VERSION "0.2"

NS_ :

BS_:

BU_: dSPACE External IFV_CWMP

BO_ 3221225472 VECTOR__INDEPENDENT_SIG_MSG: 0 Vector__XXX
 SG_ VIS_TSR_SIGN_ID_1 : 0|8@1+ (1,0) [0|255] "" Vector__XXX
 SG_ VIS_TSR_SCENE_STATUS_1 : 0|1@1+ (1,0) [0|1] "" Vector__XXX
 SG_ VIS_TSR_SCENE_ID_1 : 0|8@1+ (1,0) [0|255] "" Vector__XXX
 SG_ VIS_TSR_LANE_CHANGE : 0|2@1+ (1,0) [0|2] "" Vector__XXX
 SG_ VIS_TSR_ROAD_CLASS : 0|3@1+ (1,0) [0|4] "" Vector__XXX
 SG_ VIS_TSR_SPEED_UNIT : 0|2@1+ (1,0) [0|2] "" Vector__XXX
 SG_ VIS_TSR_TRAFFIC_STYLE : 0|1@1+ (1,0) [0|1] "" Vector__XXX
 SG_ s_AHBC_Reason_code : 0|32@1+ (1,0) [0|4294967295] "" Vector__XXX
 SG_ VIS_AHBC_DARK_ONCOMING_LANE : 0|1@1+ (1,0) [0|1] "" Vector__XXX
 SG_ VIS_AHBC_PRECEDING_SPOTS : 0|8@1+ (1,0) [0|255] "" Vector__XXX
 SG_ VIS_AHBC_ONCOMING_SPOTS : 0|8@1+ (1,0) [0|255] "" Vector__XXX
 SG_ VIS_AHBC_CLEAR_FIELD_OF_VIEW : 0|2@1+ (1,0) [0|2] "" Vector__XXX
 SG_ VIS_AHBC_STRUCT_SEPARATION_DET : 0|3@1+ (1,0) [0|4] "" Vector__XXX
 SG_ VIS_AHBC_DAY_TIME_STATUS : 0|2@1+ (1,0) [0|3] "" Vector__XXX
 SG_ VIS_AHBC_FOG_DETECTION : 0|1@1+ (1,0) [0|1] "" Vector__XXX
 SG_ VIS_AHBC_HIGHWAY_DETECTION : 0|1@1+ (1,0) [0|1] "" Vector__XXX
 SG_ VIS_AHBC_URBAN_AREA_DETECTION : 0|2@1+ (1,0) [0|2] "" Vector__XXX
 SG_ VIS_AHBC_TRAFFIC_STYLE_DETECTION : 0|1@1+ (1,0) [0|1] "" Vector__XXX
 SG_ VIS_AHBC_OBJ_10_VERTICAL_POS : 0|9@1+ (0.04,-5) [-5|5] "deg" Vector__XXX
 SG_ VIS_AHBC_OBJ_10_TYPE : 0|3@1+ (1,0) [0|5] "" Vector__XXX
 SG_ VIS_AHBC_OBJ_10_ID : 0|7@1+ (1,0) [0|127] "" Vector__XXX
 SG_ VIS_AHBC_OBJ_10_HORIZONTAL_POS : 0|11@1+ (0.04,-24) [-24|24] "deg" Vector__XXX
 SG_ VIS_AHBC_OBJ_10_HORIZONTAL_DIM : 0|9@1+ (0.04,0) [0|10] "deg" Vector__XXX
 SG_ VIS_AHBC_OBJ_10_DISTANCE : 0|4@1+ (1,0) [0|15] "" Vector__XXX
 SG_ VIS_AHBC_OBJ_09_VERTICAL_POS : 0|9@1+ (0.04,-5) [-5|5] "deg" Vector__XXX
 SG_ VIS_AHBC_OBJ_09_TYPE : 0|3@1+ (1,0) [0|5] "" Vector__XXX
 SG_ VIS_AHBC_OBJ_09_ID : 0|7@1+ (1,0) [0|127] "" Vector__XXX
 SG_ VIS_AHBC_OBJ_09_HORIZONTAL_POS : 0|11@1+ (0.04,-24) [-24|24] "deg" Vector__XXX
 SG_ VIS_AHBC_OBJ_09_HORIZONTAL_DIM : 0|9@1+ (0.04,0) [0|10] "deg" Vector__XXX
 SG_ VIS_AHBC_OBJ_09_DISTANCE : 0|4@1+ (1,0) [0|15] "" Vector__XXX
 SG_ VIS_AHBC_OBJ_08_VERTICAL_POS : 0|9@1+ (0.04,-5) [-5|5] "deg" Vector__XXX
 SG_ VIS_AHBC_OBJ_08_TYPE : 0|3@1+ (1,0) [0|5] "" Vector__XXX
 SG_ VIS_AHBC_OBJ_08_ID : 0|7@1+ (1,0) [0|127] "" Vector__XXX
 SG_ VIS_AHBC_OBJ_08_HORIZONTAL_POS : 0|11@1+ (0.04,-24) [-24|24] "deg" Vector__XXX
 SG_ VIS_AHBC_OBJ_08_HORIZONTAL_DIM : 0|9@1+ (0.04,0) [0|10] "deg" Vector__XXX
 SG_ VIS_AHBC_OBJ_08_DISTANCE : 0|4@1+ (1,0) [0|15] "" Vector__XXX
 SG_ VIS_AHBC_OBJ_07_VERTICAL_POS : 0|9@1+ (0.04,-5) [-5|5] "deg" Vector__XXX
 SG_ VIS_AHBC_OBJ_07_TYPE : 0|3@1+ (1,0) [0|5] "" Vector__XXX
 SG_ VIS_AHBC_OBJ_07_ID : 0|7@1+ (1,0) [0|127] "" Vector__XXX
 SG_ VIS_AHBC_OBJ_07_HORIZONTAL_POS : 0|11@1+ (0.04,-24) [-24|24] "deg" Vector__XXX
 SG_ VIS_AHBC_OBJ_07_HORIZONTAL_DIM : 0|9@1+ (0.04,0) [0|10] "deg" Vector__XXX
 SG_ VIS_AHBC_OBJ_07_DISTANCE : 0|4@1+ (1,0) [0|15] "" Vector__XXX
 SG_ VIS_AHBC_OBJ_06_VERTICAL_POS : 0|9@1+ (0.04,-5) [-5|5] "deg" Vector__XXX
 SG_ VIS_AHBC_OBJ_06_TYPE : 0|3@1+ (1,0) [0|5] "" Vector__XXX
 SG_ VIS_AHBC_OBJ_06_ID : 0|7@1+ (1,0) [0|127] "" Vector__XXX
 SG_ VIS_AHBC_OBJ_06_HORIZONTAL_POS : 0|11@1+ (0.04,-24) [-24|24] "deg" Vector__XXX
 SG_ VIS_AHBC_OBJ_06_HORIZONTAL_DIM : 0|9@1+ (0.04,0) [0|10] "deg" Vector__XXX
 SG_ VIS_AHBC_OBJ_06_DISTANCE : 0|4@1+ (1,0) [0|15] "" Vector__XXX
 SG_ VIS_AHBC_OBJ_05_VERTICAL_POS : 0|9@1+ (0.04,-5) [-5|5] "deg" Vector__XXX
 SG_ VIS_AHBC_OBJ_05_TYPE : 0|3@1+ (1,0) [0|5] "" Vector__XXX
 SG_ VIS_AHBC_OBJ_05_ID : 0|7@1+ (1,0) [0|127] "" Vector__XXX
 SG_ VIS_AHBC_OBJ_05_HORIZONTAL_POS : 0|11@1+ (0.04,-24) [-24|24] "deg" Vector__XXX
 SG_ VIS_AHBC_OBJ_05_HORIZONTAL_DIM : 0|9@1+ (0.04,0) [0|10] "deg" Vector__XXX
 SG_ VIS_AHBC_OBJ_05_DISTANCE : 0|4@1+ (1,0) [0|15] "" Vector__XXX
 SG_ VIS_AHBC_OBJ_04_VERTICAL_POS : 0|9@1+ (0.04,-5) [-5|5] "deg" Vector__XXX
 SG_ VIS_AHBC_OBJ_04_TYPE : 0|3@1+ (1,0) [0|5] "" Vector__XXX
 SG_ VIS_AHBC_OBJ_04_ID : 0|7@1+ (1,0) [0|127] "" Vector__XXX
 SG_ VIS_AHBC_OBJ_04_HORIZONTAL_POS : 0|11@1+ (0.04,-24) [-24|24] "deg" Vector__XXX
 SG_ VIS_AHBC_OBJ_04_HORIZONTAL_DIM : 0|9@1+ (0.04,0) [0|10] "deg" Vector__XXX
 SG_ VIS_AHBC_OBJ_04_DISTANCE : 0|4@1+ (1,0) [0|15] "" Vector__XXX
 SG_ VIS_AHBC_OBJ_03_VERTICAL_POS : 0|9@1+ (0.04,-5) [-5|5] "deg" Vector__XXX
 SG_ VIS_AHBC_OBJ_03_TYPE : 0|3@1+ (1,0) [0|5] "" Vector__XXX
 SG_ VIS_AHBC_OBJ_03_ID : 0|7@1+ (1,0) [0|127] "" Vector__XXX
 SG_ VIS_AHBC_OBJ_03_HORIZONTAL_POS : 0|11@1+ (0.04,-24) [-24|24] "deg" Vector__XXX
 SG_ VIS_AHBC_OBJ_03_HORIZONTAL_DIM : 0|9@1+ (0.04,0) [0|10] "deg" Vector__XXX
 SG_ VIS_AHBC_OBJ_03_DISTANCE : 0|4@1+ (1,0) [0|15] "" Vector__XXX
 SG_ VIS_AHBC_OBJ_02_VERTICAL_POS : 0|9@1+ (0.04,-5) [-5|5] "deg" Vector__XXX
 SG_ VIS_AHBC_OBJ_02_TYPE : 0|3@1+ (1,0) [0|5] "" Vector__XXX
 SG_ VIS_AHBC_OBJ_02_ID : 0|7@1+ (1,0) [0|127] "" Vector__XXX
 SG_ VIS_AHBC_OBJ_02_HORIZONTAL_POS : 0|11@1+ (0.04,-24) [-24|24] "deg" Vector__XXX
 SG_ VIS_AHBC_OBJ_02_HORIZONTAL_DIM : 0|9@1+ (0.04,0) [0|10] "deg" Vector__XXX
 SG_ VIS_AHBC_OBJ_02_DISTANCE : 0|4@1+ (1,0) [0|15] "" Vector__XXX
 SG_ VIS_AHBC_OBJ_01_VERTICAL_POS : 0|9@1+ (0.04,-5) [-5|5] "deg" Vector__XXX
 SG_ VIS_AHBC_OBJ_01_TYPE : 0|3@1+ (1,0) [0|5] "" Vector__XXX
 SG_ VIS_AHBC_OBJ_01_ID : 0|7@1+ (1,0) [0|127] "" Vector__XXX
 SG_ VIS_AHBC_OBJ_01_HORIZONTAL_POS : 0|11@1+ (0.04,-24) [-24|24] "deg" Vector__XXX
 SG_ VIS_AHBC_OBJ_01_HORIZONTAL_DIM : 0|9@1+ (0.04,0) [0|10] "deg" Vector__XXX
 SG_ VIS_AHBC_OBJ_01_DISTANCE : 0|4@1+ (1,0) [0|15] "" Vector__XXX
 SG_ VIS_LANE_RIGHT_PARALL_STATUS : 0|3@1+ (1,0) [0|7] "" Vector__XXX
 SG_ VIS_LANE_RIGHT_INDIVID_STATUS : 0|3@1+ (1,0) [0|7] "" Vector__XXX
 SG_ VIS_LANE_LEFT_PARALL_STATUS : 0|3@1+ (1,0) [0|7] "" Vector__XXX
 SG_ VIS_LANE_LEFT_INDIVID_STATUS : 0|3@1+ (1,0) [0|7] "" Vector__XXX
 SG_ VIS_PREDICTION_INFORMATION_R : 0|6@1+ (1,0) [0|63] "" Vector__XXX
 SG_ VIS_PREDICTION_INFORMATION_L : 0|6@1+ (1,0) [0|63] "" Vector__XXX
 SG_ VIS_CENTER_POLYNOMIAL_WIDTH : 0|10@1+ (0.01,0) [0|10] "m" Vector__XXX
 SG_ VIS_CENTER_POLYNOMIAL_A3 : 0|16@1+ (1E-008,-0.00017) [-0.00017|0.000167] "1/m^2" Vector__XXX
 SG_ VIS_CENTER_POLYNOMIAL_A2 : 0|11@1+ (1E-005,-0.01) [-0.01|0.01] "1/m" Vector__XXX
 SG_ VIS_CENTER_POLYNOMIAL_LINECASE : 0|2@1+ (1,0) [0|3] "" Vector__XXX
 SG_ VIS_CENTER_POLYNOMIAL_A1 : 0|11@1+ (0.0009,-0.9) [-0.9|0.9] "rad" Vector__XXX
 SG_ VIS_CENTER_POLYNOMIAL_A0 : 0|12@1+ (0.01,-16) [-16|15.99] "m" Vector__XXX
 SG_ VIS_CENTER_POLYNOMIAL_LANECONF : 0|2@1+ (1,0) [0|2] "" Vector__XXX
 SG_ VIS_OBS_WIDTH_15 : 0|7@1+ (0.1,0) [0|6] "m" Vector__XXX
 SG_ VIS_OBS_WIDTH_14 : 0|7@1+ (0.1,0) [0|6] "m" Vector__XXX
 SG_ VIS_OBS_WIDTH_13 : 0|7@1+ (0.1,0) [0|6] "m" Vector__XXX
 SG_ VIS_OBS_WIDTH_12 : 0|7@1+ (0.1,0) [0|6] "m" Vector__XXX
 SG_ VIS_OBS_WIDTH_11 : 0|7@1+ (0.1,0) [0|6] "m" Vector__XXX
 SG_ VIS_OBS_WIDTH_10 : 0|7@1+ (0.1,0) [0|6] "m" Vector__XXX
 SG_ VIS_OBS_WIDTH_09 : 0|7@1+ (0.1,0) [0|6] "m" Vector__XXX
 SG_ VIS_OBS_WIDTH_08 : 0|7@1+ (0.1,0) [0|6] "m" Vector__XXX
 SG_ VIS_OBS_WIDTH_07 : 0|7@1+ (0.1,0) [0|6] "m" Vector__XXX
 SG_ VIS_OBS_WIDTH_06 : 0|7@1+ (0.1,0) [0|12.7] "m" Vector__XXX
 SG_ VIS_OBS_WIDTH_05 : 0|7@1+ (0.1,0) [0|6] "m" Vector__XXX
 SG_ VIS_OBS_WIDTH_04 : 0|7@1+ (0.1,0) [0|6] "m" Vector__XXX
 SG_ VIS_OBS_WIDTH_03 : 0|7@1+ (0.1,0) [0|6] "m" Vector__XXX
 SG_ VIS_OBS_WIDTH_02 : 0|7@1+ (0.1,0) [0|6] "m" Vector__XXX
 SG_ VIS_OBS_LONG_VEL_15 : 0|12@1+ (0.0625,-128) [-128|127.9375] "m/s" Vector__XXX
 SG_ VIS_OBS_LONG_VEL_14 : 0|12@1+ (0.0625,-128) [-128|127.9375] "m/s" Vector__XXX
 SG_ VIS_OBS_LONG_VEL_13 : 0|12@1+ (0.0625,-128) [-128|127.9375] "m/s" Vector__XXX
 SG_ VIS_OBS_LONG_VEL_12 : 0|12@1+ (0.0625,-128) [-128|127.9375] "m/s" Vector__XXX
 SG_ VIS_OBS_LONG_VEL_11 : 0|12@1+ (0.0625,-128) [-128|127.9375] "m/s" Vector__XXX
 SG_ VIS_OBS_LONG_VEL_10 : 0|12@1+ (0.0625,-128) [-128|127.9375] "m/s" Vector__XXX
 SG_ VIS_OBS_LONG_VEL_09 : 0|12@1+ (0.0625,-128) [-128|127.9375] "m/s" Vector__XXX
 SG_ VIS_OBS_LONG_VEL_08 : 0|12@1+ (0.0625,-128) [-128|127.9375] "m/s" Vector__XXX
 SG_ VIS_OBS_LONG_VEL_07 : 0|12@1+ (0.0625,-128) [-128|127.9375] "m/s" Vector__XXX
 SG_ VIS_OBS_LONG_VEL_06 : 0|12@1+ (0.0625,-128) [-128|127.9375] "m/s" Vector__XXX
 SG_ VIS_OBS_LONG_VEL_05 : 0|12@1+ (0.0625,-128) [-128|127.9375] "m/s" Vector__XXX
 SG_ VIS_OBS_LONG_VEL_04 : 0|12@1+ (0.0625,-128) [-128|127.9375] "m/s" Vector__XXX
 SG_ VIS_OBS_LONG_VEL_03 : 0|12@1+ (0.0625,-128) [-128|127.9375] "m/s" Vector__XXX
 SG_ VIS_OBS_LONG_VEL_02 : 0|12@1+ (0.0625,-128) [-128|127.9375] "m/s" Vector__XXX
 SG_ VIS_OBS_LONG_POS_15 : 0|13@1+ (0.03125,0) [0|255] "m" Vector__XXX
 SG_ VIS_OBS_LONG_POS_14 : 0|13@1+ (0.03125,0) [0|255] "m" Vector__XXX
 SG_ VIS_OBS_LONG_POS_13 : 0|13@1+ (0.03125,0) [0|255] "m" Vector__XXX
 SG_ VIS_OBS_LONG_POS_12 : 0|13@1+ (0.03125,0) [0|255] "m" Vector__XXX
 SG_ VIS_OBS_LONG_POS_11 : 0|13@1+ (0.03125,0) [0|255] "m" Vector__XXX
 SG_ VIS_OBS_LONG_POS_10 : 0|13@1+ (0.03125,0) [0|255] "m" Vector__XXX
 SG_ VIS_OBS_LONG_POS_09 : 0|13@1+ (0.03125,0) [0|255] "m" Vector__XXX
 SG_ VIS_OBS_LONG_POS_08 : 0|13@1+ (0.03125,0) [0|255] "m" Vector__XXX
 SG_ VIS_OBS_LONG_POS_07 : 0|13@1+ (0.03125,0) [0|255] "m" Vector__XXX
 SG_ VIS_OBS_LONG_POS_06 : 0|13@1+ (0.03125,0) [0|255] "m" Vector__XXX
 SG_ VIS_OBS_LONG_POS_05 : 0|13@1+ (0.03125,0) [0|255] "m" Vector__XXX
 SG_ VIS_OBS_LONG_POS_04 : 0|13@1+ (0.03125,0) [0|255] "m" Vector__XXX
 SG_ VIS_OBS_LONG_POS_03 : 0|13@1+ (0.03125,0) [0|255] "m" Vector__XXX
 SG_ VIS_OBS_LONG_POS_02 : 0|13@1+ (0.03125,0) [0|255] "m" Vector__XXX
 SG_ VIS_OBS_LAT_VEL_15 : 0|12@1+ (0.0625,-128) [-128|127.9375] "m/s" Vector__XXX
 SG_ VIS_OBS_LAT_VEL_14 : 0|12@1+ (0.0625,-128) [-128|127.9375] "m/s" Vector__XXX
 SG_ VIS_OBS_LAT_VEL_13 : 0|12@1+ (0.0625,-128) [-128|127.9375] "m/s" Vector__XXX
 SG_ VIS_OBS_LAT_VEL_12 : 0|12@1+ (0.0625,-128) [-128|127.9375] "m/s" Vector__XXX
 SG_ VIS_OBS_LAT_VEL_11 : 0|12@1+ (0.0625,-128) [-128|127.9375] "m/s" Vector__XXX
 SG_ VIS_OBS_LAT_VEL_10 : 0|12@1+ (0.0625,-128) [-128|127.9375] "m/s" Vector__XXX
 SG_ VIS_OBS_LAT_VEL_09 : 0|12@1+ (0.0625,-128) [-128|127.9375] "m/s" Vector__XXX
 SG_ VIS_OBS_LAT_VEL_08 : 0|12@1+ (0.0625,-128) [-128|127.9375] "m/s" Vector__XXX
 SG_ VIS_OBS_LAT_VEL_07 : 0|12@1+ (0.0625,-128) [-128|127.9375] "m/s" Vector__XXX
 SG_ VIS_OBS_LAT_VEL_06 : 0|12@1+ (0.0625,-128) [-128|127.9375] "m/s" Vector__XXX
 SG_ VIS_OBS_LAT_VEL_05 : 0|12@1+ (0.0625,-128) [-128|127.9375] "m/s" Vector__XXX
 SG_ VIS_OBS_LAT_VEL_04 : 0|12@1+ (0.0625,-128) [-128|127.9375] "m/s" Vector__XXX
 SG_ VIS_OBS_LAT_VEL_03 : 0|12@1+ (0.0625,-128) [-128|127.9375] "m/s" Vector__XXX
 SG_ VIS_OBS_LAT_VEL_02 : 0|12@1+ (0.0625,-128) [-128|127.9375] "m/s" Vector__XXX
 SG_ VIS_OBS_LAT_POS_15 : 0|12@1+ (0.0625,-128) [-128|127.9375] "m" Vector__XXX
 SG_ VIS_OBS_LAT_POS_14 : 0|12@1+ (0.0625,-128) [-128|127.9375] "m" Vector__XXX
 SG_ VIS_OBS_LAT_POS_13 : 0|12@1+ (0.0625,-128) [-128|127.9375] "m" Vector__XXX
 SG_ VIS_OBS_LAT_POS_12 : 0|12@1+ (0.0625,-128) [-128|127.9375] "m" Vector__XXX
 SG_ VIS_OBS_LAT_POS_11 : 0|12@1+ (0.0625,-128) [-128|127.9375] "m" Vector__XXX
 SG_ VIS_OBS_LAT_POS_10 : 0|12@1+ (0.0625,-128) [-128|127.9375] "m" Vector__XXX
 SG_ VIS_OBS_LAT_POS_09 : 0|12@1+ (0.0625,-128) [-128|127.9375] "m" Vector__XXX
 SG_ VIS_OBS_LAT_POS_08 : 0|12@1+ (0.0625,-128) [-128|127.9375] "m" Vector__XXX
 SG_ VIS_OBS_LAT_POS_07 : 0|12@1+ (0.0625,-128) [-128|127.9375] "m" Vector__XXX
 SG_ VIS_OBS_LAT_POS_06 : 0|12@1+ (0.0625,-128) [-128|127.9375] "m" Vector__XXX
 SG_ VIS_OBS_LAT_POS_05 : 0|12@1+ (0.0625,-128) [-128|127.9375] "m" Vector__XXX
 SG_ VIS_OBS_LAT_POS_04 : 0|12@1+ (0.0625,-128) [-128|127.9375] "m" Vector__XXX
 SG_ VIS_OBS_LAT_POS_03 : 0|12@1+ (0.0625,-128) [-128|127.9375] "m" Vector__XXX
 SG_ VIS_OBS_LAT_POS_02 : 0|12@1+ (0.0625,-128) [-128|127.9375] "m" Vector__XXX
 SG_ VIS_OBS_WIDTH_01 : 0|7@1+ (0.1,0) [0|6] "m" Vector__XXX
 SG_ VIS_OBS_MESSAGE_COUNTER_MSG3 : 0|2@1+ (1,0) [0|3] "" Vector__XXX
 SG_ VIS_OBS_LONG_VEL_01 : 0|12@1+ (0.0625,-128) [-128|127.9375] "m/s" Vector__XXX
 SG_ VIS_OBS_LONG_POS_01 : 0|13@1+ (0.03125,0) [0|255] "m" Vector__XXX
 SG_ VIS_OBS_LAT_VEL_01 : 0|12@1+ (0.0625,-128) [-128|127.9375] "m/s" Vector__XXX
 SG_ VIS_OBS_LAT_POS_01 : 0|12@1+ (0.0625,-128) [-128|127.9375] "m" Vector__XXX
 SG_ VIS_OBS_COUNT_MSG3 : 0|4@1+ (1,0) [0|15] "obs" Vector__XXX
 SG_ VIS_OBS_TURN_INDICATOR_15 : 0|2@1+ (1,0) [0|3] "" Vector__XXX
 SG_ VIS_OBS_TURN_INDICATOR_14 : 0|2@1+ (1,0) [0|3] "" Vector__XXX
 SG_ VIS_OBS_TURN_INDICATOR_13 : 0|2@1+ (1,0) [0|3] "" Vector__XXX
 SG_ VIS_OBS_TURN_INDICATOR_12 : 0|2@1+ (1,0) [0|3] "" Vector__XXX
 SG_ VIS_OBS_TURN_INDICATOR_11 : 0|2@1+ (1,0) [0|3] "" Vector__XXX
 SG_ VIS_OBS_TURN_INDICATOR_10 : 0|2@1+ (1,0) [0|3] "" Vector__XXX
 SG_ VIS_OBS_TURN_INDICATOR_09 : 0|2@1+ (1,0) [0|3] "" Vector__XXX
 SG_ VIS_OBS_TURN_INDICATOR_08 : 0|2@1+ (1,0) [0|3] "" Vector__XXX
 SG_ VIS_OBS_TURN_INDICATOR_07 : 0|2@1+ (1,0) [0|3] "" Vector__XXX
 SG_ VIS_OBS_TURN_INDICATOR_06 : 0|2@1+ (1,0) [0|3] "" Vector__XXX
 SG_ VIS_OBS_TURN_INDICATOR_05 : 0|2@1+ (1,0) [0|3] "" Vector__XXX
 SG_ VIS_OBS_TURN_INDICATOR_04 : 0|2@1+ (1,0) [0|3] "" Vector__XXX
 SG_ VIS_OBS_TURN_INDICATOR_03 : 0|2@1+ (1,0) [0|3] "" Vector__XXX
 SG_ VIS_OBS_TURN_INDICATOR_02 : 0|2@1+ (1,0) [0|3] "" Vector__XXX
 SG_ VIS_OBS_PED_WAIST_UP_15 : 0|1@1+ (1,0) [0|1] "" Vector__XXX
 SG_ VIS_OBS_PED_WAIST_UP_14 : 0|1@1+ (1,0) [0|1] "" Vector__XXX
 SG_ VIS_OBS_PED_WAIST_UP_13 : 0|1@1+ (1,0) [0|1] "" Vector__XXX
 SG_ VIS_OBS_PED_WAIST_UP_12 : 0|1@1+ (1,0) [0|1] "" Vector__XXX
 SG_ VIS_OBS_PED_WAIST_UP_11 : 0|1@1+ (1,0) [0|1] "" Vector__XXX
 SG_ VIS_OBS_PED_WAIST_UP_10 : 0|1@1+ (1,0) [0|1] "" Vector__XXX
 SG_ VIS_OBS_PED_WAIST_UP_09 : 0|1@1+ (1,0) [0|1] "" Vector__XXX
 SG_ VIS_OBS_PED_WAIST_UP_08 : 0|1@1+ (1,0) [0|1] "" Vector__XXX
 SG_ VIS_OBS_PED_WAIST_UP_07 : 0|1@1+ (1,0) [0|1] "" Vector__XXX
 SG_ VIS_OBS_PED_WAIST_UP_06 : 0|1@1+ (1,0) [0|1] "" Vector__XXX
 SG_ VIS_OBS_PED_WAIST_UP_05 : 0|1@1+ (1,0) [0|1] "" Vector__XXX
 SG_ VIS_OBS_PED_WAIST_UP_04 : 0|1@1+ (1,0) [0|1] "" Vector__XXX
 SG_ VIS_OBS_PED_WAIST_UP_03 : 0|1@1+ (1,0) [0|1] "" Vector__XXX
 SG_ VIS_OBS_PED_WAIST_UP_02 : 0|1@1+ (1,0) [0|1] "" Vector__XXX
 SG_ VIS_OBS_ID_15 : 0|4@1+ (1,0) [0|15] "" Vector__XXX
 SG_ VIS_OBS_ID_14 : 0|4@1+ (1,0) [0|15] "" Vector__XXX
 SG_ VIS_OBS_ID_13 : 0|4@1+ (1,0) [0|15] "" Vector__XXX
 SG_ VIS_OBS_ID_12 : 0|4@1+ (1,0) [0|15] "" Vector__XXX
 SG_ VIS_OBS_ID_11 : 0|4@1+ (1,0) [0|15] "" Vector__XXX
 SG_ VIS_OBS_ID_10 : 0|4@1+ (1,0) [0|15] "" Vector__XXX
 SG_ VIS_OBS_ID_09 : 0|4@1+ (1,0) [0|15] "" Vector__XXX
 SG_ VIS_OBS_ID_08 : 0|4@1+ (1,0) [0|15] "" Vector__XXX
 SG_ VIS_OBS_ID_07 : 0|4@1+ (1,0) [0|15] "" Vector__XXX
 SG_ VIS_OBS_ID_06 : 0|4@1+ (1,0) [0|15] "" Vector__XXX
 SG_ VIS_OBS_ID_05 : 0|4@1+ (1,0) [0|15] "" Vector__XXX
 SG_ VIS_OBS_ID_04 : 0|4@1+ (1,0) [0|15] "" Vector__XXX
 SG_ VIS_OBS_ID_03 : 0|4@1+ (1,0) [0|15] "" Vector__XXX
 SG_ VIS_OBS_ID_02 : 0|4@1+ (1,0) [0|15] "" Vector__XXX
 SG_ VIS_OBS_HEIGHT_15 : 0|5@1+ (0.1,0) [0|3] "m" Vector__XXX
 SG_ VIS_OBS_HEIGHT_14 : 0|5@1+ (0.1,0) [0|3] "m" Vector__XXX
 SG_ VIS_OBS_HEIGHT_13 : 0|5@1+ (0.1,0) [0|3] "m" Vector__XXX
 SG_ VIS_OBS_HEIGHT_12 : 0|5@1+ (0.1,0) [0|3] "m" Vector__XXX
 SG_ VIS_OBS_HEIGHT_11 : 0|5@1+ (0.1,0) [0|3] "m" Vector__XXX
 SG_ VIS_OBS_HEIGHT_10 : 0|5@1+ (0.1,0) [0|3] "m" Vector__XXX
 SG_ VIS_OBS_HEIGHT_09 : 0|5@1+ (0.1,0) [0|3] "m" Vector__XXX
 SG_ VIS_OBS_HEIGHT_08 : 0|5@1+ (0.1,0) [0|3] "m" Vector__XXX
 SG_ VIS_OBS_HEIGHT_07 : 0|5@1+ (0.1,0) [0|3] "m" Vector__XXX
 SG_ VIS_OBS_HEIGHT_06 : 0|5@1+ (0.1,0) [0|3] "m" Vector__XXX
 SG_ VIS_OBS_HEIGHT_05 : 0|5@1+ (0.1,0) [0|3] "m" Vector__XXX
 SG_ VIS_OBS_HEIGHT_04 : 0|5@1+ (0.1,0) [0|3] "m" Vector__XXX
 SG_ VIS_OBS_HEIGHT_03 : 0|5@1+ (0.1,0) [0|3] "m" Vector__XXX
 SG_ VIS_OBS_HEIGHT_02 : 0|5@1+ (0.1,0) [0|3] "m" Vector__XXX
 SG_ VIS_OBS_CLASSIFICATION_15 : 0|4@1+ (1,0) [0|10] "" Vector__XXX
 SG_ VIS_OBS_CLASSIFICATION_14 : 0|4@1+ (1,0) [0|10] "" Vector__XXX
 SG_ VIS_OBS_CLASSIFICATION_13 : 0|4@1+ (1,0) [0|10] "" Vector__XXX
 SG_ VIS_OBS_CLASSIFICATION_12 : 0|4@1+ (1,0) [0|10] "" Vector__XXX
 SG_ VIS_OBS_CLASSIFICATION_11 : 0|4@1+ (1,0) [0|10] "" Vector__XXX
 SG_ VIS_OBS_CLASSIFICATION_10 : 0|4@1+ (1,0) [0|10] "" Vector__XXX
 SG_ VIS_OBS_CLASSIFICATION_09 : 0|4@1+ (1,0) [0|10] "" Vector__XXX
 SG_ VIS_OBS_CLASSIFICATION_08 : 0|4@1+ (1,0) [0|10] "" Vector__XXX
 SG_ VIS_OBS_CLASSIFICATION_07 : 0|4@1+ (1,0) [0|10] "" Vector__XXX
 SG_ VIS_OBS_CLASSIFICATION_06 : 0|4@1+ (1,0) [0|10] "" Vector__XXX
 SG_ VIS_OBS_CLASSIFICATION_05 : 0|4@1+ (1,0) [0|10] "" Vector__XXX
 SG_ VIS_OBS_CLASSIFICATION_04 : 0|4@1+ (1,0) [0|10] "" Vector__XXX
 SG_ VIS_OBS_CLASSIFICATION_03 : 0|4@1+ (1,0) [0|10] "" Vector__XXX
 SG_ VIS_OBS_CLASSIFICATION_02 : 0|4@1+ (1,0) [0|10] "" Vector__XXX
 SG_ VIS_OBS_BRAKE_LIGHT_INDIC_15 : 0|2@1+ (1,0) [0|2] "" Vector__XXX
 SG_ VIS_OBS_BRAKE_LIGHT_INDIC_14 : 0|2@1+ (1,0) [0|2] "" Vector__XXX
 SG_ VIS_OBS_BRAKE_LIGHT_INDIC_13 : 0|2@1+ (1,0) [0|2] "" Vector__XXX
 SG_ VIS_OBS_BRAKE_LIGHT_INDIC_12 : 0|2@1+ (1,0) [0|2] "" Vector__XXX
 SG_ VIS_OBS_BRAKE_LIGHT_INDIC_11 : 0|2@1+ (1,0) [0|2] "" Vector__XXX
 SG_ VIS_OBS_BRAKE_LIGHT_INDIC_10 : 0|2@1+ (1,0) [0|2] "" Vector__XXX
 SG_ VIS_OBS_BRAKE_LIGHT_INDIC_09 : 0|2@1+ (1,0) [0|2] "" Vector__XXX
 SG_ VIS_OBS_BRAKE_LIGHT_INDIC_08 : 0|2@1+ (1,0) [0|2] "" Vector__XXX
 SG_ VIS_OBS_BRAKE_LIGHT_INDIC_07 : 0|2@1+ (1,0) [0|2] "" Vector__XXX
 SG_ VIS_OBS_BRAKE_LIGHT_INDIC_06 : 0|2@1+ (1,0) [0|2] "" Vector__XXX
 SG_ VIS_OBS_BRAKE_LIGHT_INDIC_05 : 0|2@1+ (1,0) [0|2] "" Vector__XXX
 SG_ VIS_OBS_BRAKE_LIGHT_INDIC_04 : 0|2@1+ (1,0) [0|2] "" Vector__XXX
 SG_ VIS_OBS_BRAKE_LIGHT_INDIC_03 : 0|2@1+ (1,0) [0|2] "" Vector__XXX
 SG_ VIS_OBS_BRAKE_LIGHT_INDIC_02 : 0|2@1+ (1,0) [0|2] "" Vector__XXX
 SG_ VIS_OBS_TURN_INDICATOR_01 : 0|2@1+ (1,0) [0|3] "" Vector__XXX
 SG_ VIS_OBS_PED_WAIST_UP_01 : 0|1@1+ (1,0) [0|1] "" Vector__XXX
 SG_ VIS_OBS_MESSAGE_COUNTER_MSG1 : 0|2@1+ (1,0) [0|3] "" Vector__XXX
 SG_ VIS_OBS_ID_01 : 0|4@1+ (1,0) [0|15] "" Vector__XXX
 SG_ VIS_OBS_HEIGHT_01 : 0|5@1+ (0.1,0) [0|3] "m" Vector__XXX
 SG_ VIS_OBS_COUNT_MSG1 : 0|4@1+ (1,0) [0|15] "obs" Vector__XXX
 SG_ VIS_OBS_CLASSIFICATION_01 : 0|4@1+ (1,0) [0|10] "" Vector__XXX
 SG_ VIS_OBS_BRAKE_LIGHT_INDIC_01 : 0|2@1+ (1,0) [0|2] "" Vector__XXX
 SG_ VIS_LANE_RIGHT_PARALL_RANGE : 0|9@1+ (0.25,0) [0|127.75] "m" Vector__XXX
 SG_ VIS_LANE_RIGHT_PARALL_A3 : 0|16@1+ (1E-008,-0.00017) [-0.00017|0.000167] "1/m^2" Vector__XXX
 SG_ VIS_LANE_RIGHT_PARALL_A2 : 0|12@1+ (5E-006,-0.01) [-0.01|0.01] "1/m" Vector__XXX
 SG_ VIS_LANE_RIGHT_PARALL_A1 : 0|11@1+ (0.0009,-0.9) [-0.9|0.9] "" Vector__XXX
 SG_ VIS_LANE_RIGHT_PARALL_A0 : 0|12@1+ (0.01,-16) [-16|15.99] "m" Vector__XXX
 SG_ VIS_LANE_RIGHT_PA_MARKER_COLOR : 0|2@1+ (1,0) [0|3] "" Vector__XXX
 SG_ VIS_LANE_RIGHT_INDIVID_RANGE : 0|9@1+ (0.25,0) [0|127.75] "m" Vector__XXX
 SG_ VIS_LANE_RIGHT_INDIVID_A3 : 0|16@1+ (1E-008,-0.00017) [-0.00017|0.000167] "1/m^2" Vector__XXX
 SG_ VIS_LANE_RIGHT_INDIVID_A2 : 0|12@1+ (5E-006,-0.01) [-0.01|0.01] "1/m" Vector__XXX
 SG_ VIS_LANE_RIGHT_INDIVID_A1 : 0|11@1+ (0.0009,-0.9) [-0.9|0.9] "" Vector__XXX
 SG_ VIS_LANE_RIGHT_INDIVID_A0 : 0|12@1+ (0.01,-16) [-16|15.99] "m" Vector__XXX
 SG_ VIS_LANE_RIGHT_IN_MARKER_COLOR : 0|2@1+ (1,0) [0|3] "" Vector__XXX
 SG_ VIS_LANE_LEFT_PARALL_RANGE : 0|9@1+ (0.25,0) [0|127.75] "m" Vector__XXX
 SG_ VIS_LANE_LEFT_PARALL_A3 : 0|16@1+ (1E-008,-0.00017) [-0.00017|0.000167] "1/m^2" Vector__XXX
 SG_ VIS_LANE_LEFT_PARALL_A2 : 0|12@1+ (5E-006,-0.01) [-0.01|0.01] "1/m" Vector__XXX
 SG_ VIS_LANE_LEFT_PARALL_A1 : 0|11@1+ (0.0009,-0.9) [-0.9|0.9] "" Vector__XXX
 SG_ VIS_LANE_LEFT_PARALL_A0 : 0|12@1+ (0.01,-16) [-16|15.99] "m" Vector__XXX
 SG_ VIS_LANE_LEFT_PA_MARKER_COLOR : 0|2@1+ (1,0) [0|3] "" Vector__XXX
 SG_ VIS_LANE_LEFT_INDIVID_RANGE : 0|9@1+ (0.25,0) [0|127.75] "m" Vector__XXX
 SG_ VIS_LANE_LEFT_INDIVID_A3 : 0|16@1+ (1E-008,-0.00017) [-0.00017|0.000167] "1/m^2" Vector__XXX
 SG_ VIS_LANE_LEFT_INDIVID_A2 : 0|12@1+ (5E-006,-0.01) [-0.01|0.01] "1/m" Vector__XXX
 SG_ VIS_LANE_LEFT_INDIVID_A1 : 0|11@1+ (0.0009,-0.9) [-0.9|0.9] "" Vector__XXX
 SG_ VIS_LANE_LEFT_INDIVID_A0 : 0|12@1+ (0.01,-16) [-16|15.99] "m" Vector__XXX
 SG_ VIS_LANE_LEFT_IN_MARKER_COLOR : 0|2@1+ (1,0) [0|3] "" Vector__XXX
 SG_ SIGN_8_VIS_TSR_RELEVANT : 0|1@1+ (1,0) [0|1] "" Vector__XXX
 SG_ SIGN_8_VIS_TSR_RELEVANT_DECISION : 0|3@1+ (1,0) [0|7] "" Vector__XXX
 SG_ SIGN_8_VIS_TSR_LOCATION : 0|1@1+ (1,0) [0|1] "" Vector__XXX
 SG_ SIGN_8_VIS_TSR_POS_LONG : 0|7@1+ (1,0) [0|127] "" Vector__XXX
 SG_ SIGN_8_VIS_TSR_SIGN_EMBEDDED : 0|1@1+ (1,0) [0|1] "" Vector__XXX
 SG_ SIGN_8_VIS_TSR_POSITION_LATERAL : 0|7@1+ (1,-64) [-64|63] "m" Vector__XXX
 SG_ SIGN_8_VIS_TSR_SUPPL_TYPE_1ST : 0|5@1+ (1,0) [0|24] "" Vector__XXX
 SG_ SIGN_8_VIS_TSR_ID : 0|3@1+ (1,0) [0|7] "" Vector__XXX
 SG_ SIGN_8_VIS_TSR_SIGN_VALUE : 0|8@1+ (1,0) [0|255] "" Vector__XXX
 SG_ SIGN_8_VIS_TSR_CONFIDENCE : 0|5@1+ (0.0625,0) [0|1] "" Vector__XXX
 SG_ SIGN_8_VIS_TSR_STATUS : 0|3@1+ (1,0) [0|7] "" Vector__XXX
 SG_ SIGN_8_VIS_TSR_SUPPL_TYPE_2ND : 0|5@1+ (1,0) [0|24] "" Vector__XXX
 SG_ SIGN_8_VIS_TSR_LOCATION_LANE : 0|3@1+ (1,-4) [-4|3] "" Vector__XXX
 SG_ SIGN_8_VIS_TSR_ELECTRONIC_SIGN : 0|1@1+ (1,0) [0|1] "" Vector__XXX
 SG_ SIGN_8_VIS_TSR_TYPE : 0|7@1+ (1,0) [0|127] "" Vector__XXX
 SG_ SIGN_7_VIS_TSR_RELEVANT : 0|1@1+ (1,0) [0|1] "" Vector__XXX
 SG_ SIGN_7_VIS_TSR_RELEVANT_DECISION : 0|3@1+ (1,0) [0|7] "" Vector__XXX
 SG_ SIGN_7_VIS_TSR_LOCATION : 0|1@1+ (1,0) [0|1] "" Vector__XXX
 SG_ SIGN_7_VIS_TSR_POS_LONG : 0|7@1+ (1,0) [0|127] "" Vector__XXX
 SG_ SIGN_7_VIS_TSR_SIGN_EMBEDDED : 0|1@1+ (1,0) [0|1] "" Vector__XXX
 SG_ SIGN_7_VIS_TSR_POSITION_LATERAL : 0|7@1+ (1,-64) [-64|63] "m" Vector__XXX
 SG_ SIGN_7_VIS_TSR_SUPPL_TYPE_1ST : 0|5@1+ (1,0) [0|24] "" Vector__XXX
 SG_ SIGN_7_VIS_TSR_ID : 0|3@1+ (1,0) [0|7] "" Vector__XXX
 SG_ SIGN_7_VIS_TSR_SIGN_VALUE : 0|8@1+ (1,0) [0|255] "" Vector__XXX
 SG_ SIGN_7_VIS_TSR_CONFIDENCE : 0|5@1+ (0.0625,0) [0|1] "" Vector__XXX
 SG_ SIGN_7_VIS_TSR_STATUS : 0|3@1+ (1,0) [0|7] "" Vector__XXX
 SG_ SIGN_7_VIS_TSR_SUPPL_TYPE_2ND : 0|5@1+ (1,0) [0|24] "" Vector__XXX
 SG_ SIGN_7_VIS_TSR_LOCATION_LANE : 0|3@1+ (1,-4) [-4|3] "" Vector__XXX
 SG_ SIGN_7_VIS_TSR_ELECTRONIC_SIGN : 0|1@1+ (1,0) [0|1] "" Vector__XXX
 SG_ SIGN_7_VIS_TSR_TYPE : 0|7@1+ (1,0) [0|127] "" Vector__XXX
 SG_ SIGN_6_VIS_TSR_RELEVANT : 0|1@1+ (1,0) [0|1] "" Vector__XXX
 SG_ SIGN_6_VIS_TSR_RELEVANT_DECISION : 0|3@1+ (1,0) [0|7] "" Vector__XXX
 SG_ SIGN_6_VIS_TSR_LOCATION : 0|1@1+ (1,0) [0|1] "" Vector__XXX
 SG_ SIGN_6_VIS_TSR_POS_LONG : 0|7@1+ (1,0) [0|127] "" Vector__XXX
 SG_ SIGN_6_VIS_TSR_SIGN_EMBEDDED : 0|1@1+ (1,0) [0|1] "" Vector__XXX
 SG_ SIGN_6_VIS_TSR_POSITION_LATERAL : 0|7@1+ (1,-64) [-64|63] "m" Vector__XXX
 SG_ SIGN_6_VIS_TSR_SUPPL_TYPE_1ST : 0|5@1+ (1,0) [0|24] "" Vector__XXX
 SG_ SIGN_6_VIS_TSR_ID : 0|3@1+ (1,0) [0|7] "" Vector__XXX
 SG_ SIGN_6_VIS_TSR_SIGN_VALUE : 0|8@1+ (1,0) [0|255] "" Vector__XXX
 SG_ SIGN_6_VIS_TSR_CONFIDENCE : 0|5@1+ (0.0625,0) [0|1] "" Vector__XXX
 SG_ SIGN_6_VIS_TSR_STATUS : 0|3@1+ (1,0) [0|7] "" Vector__XXX
 SG_ SIGN_6_VIS_TSR_SUPPL_TYPE_2ND : 0|5@1+ (1,0) [0|24] "" Vector__XXX
 SG_ SIGN_6_VIS_TSR_LOCATION_LANE : 0|3@1+ (1,-4) [-4|3] "" Vector__XXX
 SG_ SIGN_6_VIS_TSR_ELECTRONIC_SIGN : 0|1@1+ (1,0) [0|1] "" Vector__XXX
 SG_ SIGN_6_VIS_TSR_TYPE : 0|7@1+ (1,0) [0|127] "" Vector__XXX
 SG_ SIGN_5_VIS_TSR_RELEVANT : 0|1@1+ (1,0) [0|1] "" Vector__XXX
 SG_ SIGN_5_VIS_TSR_RELEVANT_DECISION : 0|3@1+ (1,0) [0|7] "" Vector__XXX
 SG_ SIGN_5_VIS_TSR_LOCATION : 0|1@1+ (1,0) [0|1] "" Vector__XXX
 SG_ SIGN_5_VIS_TSR_POS_LONG : 0|7@1+ (1,0) [0|127] "" Vector__XXX
 SG_ SIGN_5_VIS_TSR_SIGN_EMBEDDED : 0|1@1+ (1,0) [0|1] "" Vector__XXX
 SG_ SIGN_5_VIS_TSR_POSITION_LATERAL : 0|7@1+ (1,-64) [-64|63] "m" Vector__XXX
 SG_ SIGN_5_VIS_TSR_SUPPL_TYPE_1ST : 0|5@1+ (1,0) [0|24] "" Vector__XXX
 SG_ SIGN_5_VIS_TSR_ID : 0|3@1+ (1,0) [0|7] "" Vector__XXX
 SG_ SIGN_5_VIS_TSR_SIGN_VALUE : 0|8@1+ (1,0) [0|255] "" Vector__XXX
 SG_ SIGN_5_VIS_TSR_CONFIDENCE : 0|5@1+ (0.0625,0) [0|1] "" Vector__XXX
 SG_ SIGN_5_VIS_TSR_STATUS : 0|3@1+ (1,0) [0|7] "" Vector__XXX
 SG_ SIGN_5_VIS_TSR_SUPPL_TYPE_2ND : 0|5@1+ (1,0) [0|24] "" Vector__XXX
 SG_ SIGN_5_VIS_TSR_LOCATION_LANE : 0|3@1+ (1,-4) [-4|3] "" Vector__XXX
 SG_ SIGN_5_VIS_TSR_ELECTRONIC_SIGN : 0|1@1+ (1,0) [0|1] "" Vector__XXX
 SG_ SIGN_5_VIS_TSR_TYPE : 0|7@1+ (1,0) [0|127] "" Vector__XXX
 SG_ SIGN_4_VIS_TSR_RELEVANT : 0|1@1+ (1,0) [0|1] "" Vector__XXX
 SG_ SIGN_4_VIS_TSR_RELEVANT_DECISION : 0|3@1+ (1,0) [0|7] "" Vector__XXX
 SG_ SIGN_4_VIS_TSR_LOCATION : 0|1@1+ (1,0) [0|1] "" Vector__XXX
 SG_ SIGN_4_VIS_TSR_POS_LONG : 0|7@1+ (1,0) [0|127] "" Vector__XXX
 SG_ SIGN_4_VIS_TSR_SIGN_EMBEDDED : 0|1@1+ (1,0) [0|1] "" Vector__XXX
 SG_ SIGN_4_VIS_TSR_POSITION_LATERAL : 0|7@1+ (1,-64) [-64|63] "m" Vector__XXX
 SG_ SIGN_4_VIS_TSR_SUPPL_TYPE_1ST : 0|5@1+ (1,0) [0|24] "" Vector__XXX
 SG_ SIGN_4_VIS_TSR_ID : 0|3@1+ (1,0) [0|7] "" Vector__XXX
 SG_ SIGN_4_VIS_TSR_SIGN_VALUE : 0|8@1+ (1,0) [0|255] "" Vector__XXX
 SG_ SIGN_4_VIS_TSR_CONFIDENCE : 0|5@1+ (0.0625,0) [0|1] "" Vector__XXX
 SG_ SIGN_4_VIS_TSR_STATUS : 0|3@1+ (1,0) [0|7] "" Vector__XXX
 SG_ SIGN_4_VIS_TSR_SUPPL_TYPE_2ND : 0|5@1+ (1,0) [0|24] "" Vector__XXX
 SG_ SIGN_4_VIS_TSR_LOCATION_LANE : 0|3@1+ (1,-4) [-4|3] "" Vector__XXX
 SG_ SIGN_4_VIS_TSR_ELECTRONIC_SIGN : 0|1@1+ (1,0) [0|1] "" Vector__XXX
 SG_ SIGN_4_VIS_TSR_TYPE : 0|7@1+ (1,0) [0|127] "" Vector__XXX
 SG_ SIGN_3_VIS_TSR_RELEVANT : 0|1@1+ (1,0) [0|1] "" Vector__XXX
 SG_ SIGN_3_VIS_TSR_RELEVANT_DECISION : 0|3@1+ (1,0) [0|7] "" Vector__XXX
 SG_ SIGN_3_VIS_TSR_LOCATION : 0|1@1+ (1,0) [0|1] "" Vector__XXX
 SG_ SIGN_3_VIS_TSR_POS_LONG : 0|7@1+ (1,0) [0|127] "" Vector__XXX
 SG_ SIGN_3_VIS_TSR_SIGN_EMBEDDED : 0|1@1+ (1,0) [0|1] "" Vector__XXX
 SG_ SIGN_3_VIS_TSR_POSITION_LATERAL : 0|7@1+ (1,-64) [-64|63] "m" Vector__XXX
 SG_ SIGN_3_VIS_TSR_SUPPL_TYPE_1ST : 0|5@1+ (1,0) [0|24] "" Vector__XXX
 SG_ SIGN_3_VIS_TSR_ID : 0|3@1+ (1,0) [0|7] "" Vector__XXX
 SG_ SIGN_3_VIS_TSR_SIGN_VALUE : 0|8@1+ (1,0) [0|255] "" Vector__XXX
 SG_ SIGN_3_VIS_TSR_CONFIDENCE : 0|5@1+ (0.0625,0) [0|1] "" Vector__XXX
 SG_ SIGN_3_VIS_TSR_STATUS : 0|3@1+ (1,0) [0|7] "" Vector__XXX
 SG_ SIGN_3_VIS_TSR_SUPPL_TYPE_2ND : 0|5@1+ (1,0) [0|24] "" Vector__XXX
 SG_ SIGN_3_VIS_TSR_LOCATION_LANE : 0|3@1+ (1,-4) [-4|3] "" Vector__XXX
 SG_ SIGN_3_VIS_TSR_ELECTRONIC_SIGN : 0|1@1+ (1,0) [0|1] "" Vector__XXX
 SG_ SIGN_3_VIS_TSR_TYPE : 0|7@1+ (1,0) [0|127] "" Vector__XXX
 SG_ SIGN_2_VIS_TSR_RELEVANT : 0|1@1+ (1,0) [0|1] "" Vector__XXX
 SG_ SIGN_2_VIS_TSR_RELEVANT_DECISION : 0|3@1+ (1,0) [0|7] "" Vector__XXX
 SG_ SIGN_2_VIS_TSR_LOCATION : 0|1@1+ (1,0) [0|1] "" Vector__XXX
 SG_ SIGN_2_VIS_TSR_POS_LONG : 0|7@1+ (1,0) [0|127] "" Vector__XXX
 SG_ SIGN_2_VIS_TSR_SIGN_EMBEDDED : 0|1@1+ (1,0) [0|1] "" Vector__XXX
 SG_ SIGN_2_VIS_TSR_POSITION_LATERAL : 0|7@1+ (1,-64) [-64|63] "m" Vector__XXX
 SG_ SIGN_2_VIS_TSR_SUPPL_TYPE_1ST : 0|5@1+ (1,0) [0|24] "" Vector__XXX
 SG_ SIGN_2_VIS_TSR_ID : 0|3@1+ (1,0) [0|7] "" Vector__XXX
 SG_ SIGN_2_VIS_TSR_SIGN_VALUE : 0|8@1+ (1,0) [0|255] "" Vector__XXX
 SG_ SIGN_2_VIS_TSR_CONFIDENCE : 0|5@1+ (0.0625,0) [0|1] "" Vector__XXX
 SG_ SIGN_2_VIS_TSR_STATUS : 0|3@1+ (1,0) [0|7] "" Vector__XXX
 SG_ SIGN_2_VIS_TSR_SUPPL_TYPE_2ND : 0|5@1+ (1,0) [0|24] "" Vector__XXX
 SG_ SIGN_2_VIS_TSR_LOCATION_LANE : 0|3@1+ (1,-4) [-4|3] "" Vector__XXX
 SG_ SIGN_2_VIS_TSR_ELECTRONIC_SIGN : 0|1@1+ (1,0) [0|1] "" Vector__XXX
 SG_ SIGN_2_VIS_TSR_TYPE : 0|7@1+ (1,0) [0|127] "" Vector__XXX
 SG_ SIGN_1_VIS_TSR_RELEVANT : 0|1@1+ (1,0) [0|1] "" Vector__XXX
 SG_ SIGN_1_VIS_TSR_RELEVANT_DECISION : 0|3@1+ (1,0) [0|7] "" Vector__XXX
 SG_ SIGN_1_VIS_TSR_LOCATION : 0|1@1+ (1,0) [0|0] "" Vector__XXX
 SG_ SIGN_1_VIS_TSR_POS_LONG : 0|7@1+ (1,0) [0|127] "" Vector__XXX
 SG_ SIGN_1_VIS_TSR_SIGN_EMBEDDED : 0|1@1+ (1,0) [0|1] "" Vector__XXX
 SG_ SIGN_1_VIS_TSR_POSITION_LATERAL : 0|7@1+ (1,-64) [-64|63] "m" Vector__XXX
 SG_ SIGN_1_VIS_TSR_SUPPL_TYPE_1ST : 0|5@1+ (1,0) [0|24] "" Vector__XXX
 SG_ SIGN_1_VIS_TSR_ID : 0|3@1+ (1,0) [0|7] "" Vector__XXX
 SG_ SIGN_1_VIS_TSR_SIGN_VALUE : 0|8@1+ (1,0) [0|255] "" Vector__XXX
 SG_ SIGN_1_VIS_TSR_CONFIDENCE : 0|5@1+ (0.0625,0) [0|1] "" Vector__XXX
 SG_ SIGN_1_VIS_TSR_STATUS : 0|3@1+ (1,0) [0|7] "" Vector__XXX
 SG_ SIGN_1_VIS_TSR_SUPPL_TYPE_2ND : 0|5@1+ (1,0) [0|24] "" Vector__XXX
 SG_ SIGN_1_VIS_TSR_LOCATION_LANE : 0|3@1+ (1,-4) [-4|3] "" Vector__XXX
 SG_ SIGN_1_VIS_TSR_ELECTRONIC_SIGN : 0|1@1+ (1,0) [0|1] "" Vector__XXX
 SG_ SIGN_1_VIS_TSR_TYPE : 0|7@1+ (1,0) [0|127] "" Vector__XXX
 SG_ VIS_LANE_PARALL_PROB : 0|1@1+ (1,0) [0|1] "" Vector__XXX
 SG_ VIS_ROAD_ISTUNNEL_ENTRYEXIT : 0|1@1+ (1,0) [0|1] "" Vector__XXX
 SG_ VIS_OBS_CIPV : 0|4@1+ (1,0) [0|15] "" Vector__XXX
 SG_ VIS_FCN_VIS_VRU_FCE_UNCONF_BRK : 0|4@1+ (1,0) [0|15] "" Vector__XXX
 SG_ VIS_FCN_VIS_VEH_FCE_UNCONF_BRK : 0|4@1+ (1,0) [0|15] "" Vector__XXX
 SG_ VIS_FCW_VIS_ONLY_VRU_WARN : 0|4@1+ (1,0) [0|15] "" Vector__XXX
 SG_ VIS_FCW_VIS_ONLY_VRU_PART_BRAKE : 0|4@1+ (1,0) [0|15] "" Vector__XXX
 SG_ VIS_FCW_VIS_ONLY_VEH_PART_BRAKE : 0|4@1+ (1,0) [0|15] "" Vector__XXX
 SG_ VIS_FCW_SENS_LEVEL : 0|2@1+ (1,0) [0|2] "" Vector__XXX
 SG_ VIS_FCW_NEAR_RNG_OBS_VIO : 0|2@1+ (1,0) [0|3] "" Vector__XXX
 SG_ VIS_FCW_VIS_ONLY_VEH_WARN : 0|4@1+ (1,0) [0|15] "" Vector__XXX
 SG_ VIS_FCW_VIS_ONLY_VEH_BRAKE : 0|4@1+ (1,0) [0|15] "" Vector__XXX
 SG_ VIS_FCW_VIS_ONLY_VRU_BRAKE : 0|4@1+ (1,0) [0|15] "" Vector__XXX
 SG_ PAC_visTrkID : 0|4@1+ (1,0) [0|15] "" Vector__XXX
 SG_ PAC_Stage_age : 0|8@1+ (1,0) [0|255] "" Vector__XXX
 SG_ PAC_Object_class : 0|4@1+ (1,0) [0|10] "" Vector__XXX
 SG_ P9C_visTrkID : 0|4@1+ (1,0) [0|15] "" Vector__XXX
 SG_ P9C_Stage_age : 0|8@1+ (1,0) [0|255] "" Vector__XXX
 SG_ P9C_Object_class : 0|4@1+ (1,0) [0|10] "" Vector__XXX
 SG_ P8C_visTrkID : 0|4@1+ (1,0) [0|15] "" Vector__XXX
 SG_ P8C_Stage_age : 0|8@1+ (1,0) [0|255] "" Vector__XXX
 SG_ P8C_Object_class : 0|4@1+ (1,0) [0|10] "" Vector__XXX
 SG_ P7C_visTrkID : 0|4@1+ (1,0) [0|15] "" Vector__XXX
 SG_ P7C_Stage_age : 0|8@1+ (1,0) [0|255] "" Vector__XXX
 SG_ P7C_Object_class : 0|4@1+ (1,0) [0|10] "" Vector__XXX
 SG_ P6C_visTrkID : 0|4@1+ (1,0) [0|15] "" Vector__XXX
 SG_ P6C_Stage_age : 0|8@1+ (1,0) [0|255] "" Vector__XXX
 SG_ P6C_Object_class : 0|4@1+ (1,0) [0|10] "" Vector__XXX
 SG_ P5C_visTrkID : 0|4@1+ (1,0) [0|15] "" Vector__XXX
 SG_ P5C_Stage_age : 0|8@1+ (1,0) [0|255] "" Vector__XXX
 SG_ P5C_Object_class : 0|4@1+ (1,0) [0|10] "" Vector__XXX
 SG_ P4C_visTrkID : 0|4@1+ (1,0) [0|15] "" Vector__XXX
 SG_ P4C_Stage_age : 0|8@1+ (1,0) [0|255] "" Vector__XXX
 SG_ P4C_Object_class : 0|4@1+ (1,0) [0|10] "" Vector__XXX
 SG_ P3C_visTrkID : 0|4@1+ (1,0) [0|15] "" Vector__XXX
 SG_ P3C_Stage_age : 0|8@1+ (1,0) [0|255] "" Vector__XXX
 SG_ P3C_Object_class : 0|4@1+ (1,0) [0|10] "" Vector__XXX
 SG_ P2C_visTrkID : 0|4@1+ (1,0) [0|15] "" Vector__XXX
 SG_ P2C_Stage_age : 0|8@1+ (1,0) [0|255] "" Vector__XXX
 SG_ P2C_Object_class : 0|4@1+ (1,0) [0|10] "" Vector__XXX
 SG_ PAB_A_lat_obj : 0|11@1+ (0.01,-10) [-10|10] "m/s^2" Vector__XXX
 SG_ PAB_V_lat_obj : 0|12@1+ (0.05,-20) [-20|20] "m/s" Vector__XXX
 SG_ PAB_FcwConfidence : 0|3@1+ (1,0) [0|1] "" Vector__XXX
 SG_ PAB_CmbbPrimaryConfidence : 0|3@1+ (1,0) [0|3] "" Vector__XXX
 SG_ PAB_Status : 0|3@1+ (1,0) [0|7] "" Vector__XXX
 SG_ PAB_Age : 0|8@1+ (1,0) [0|255] "" Vector__XXX
 SG_ P9B_V_lat_obj : 0|12@1+ (0.05,-20) [-20|20] "m/s" Vector__XXX
 SG_ P9B_FcwConfidence : 0|3@1+ (1,0) [0|1] "" Vector__XXX
 SG_ P9B_CmbbPrimaryConfidence : 0|3@1+ (1,0) [0|3] "" Vector__XXX
 SG_ P9B_Status : 0|3@1+ (1,0) [0|7] "" Vector__XXX
 SG_ P9B_Age : 0|8@1+ (1,0) [0|255] "" Vector__XXX
 SG_ P9B_A_lat_obj : 0|11@1+ (0.01,-10) [-10|10] "m/s^2" Vector__XXX
 SG_ P8B_V_lat_obj : 0|12@1+ (0.05,-20) [-20|20] "m/s" Vector__XXX
 SG_ P8B_FcwConfidence : 0|3@1+ (1,0) [0|1] "" Vector__XXX
 SG_ P8B_CmbbPrimaryConfidence : 0|3@1+ (1,0) [0|3] "" Vector__XXX
 SG_ P8B_Status : 0|3@1+ (1,0) [0|7] "" Vector__XXX
 SG_ P8B_Age : 0|8@1+ (1,0) [0|255] "" Vector__XXX
 SG_ P8B_A_lat_obj : 0|11@1+ (0.01,-10) [-10|10] "m/s^2" Vector__XXX
 SG_ P7B_V_lat_obj : 0|12@1+ (0.05,-20) [-20|20] "m/s" Vector__XXX
 SG_ P7B_FcwConfidence : 0|3@1+ (1,0) [0|1] "" Vector__XXX
 SG_ P7B_CmbbPrimaryConfidence : 0|3@1+ (1,0) [0|3] "" Vector__XXX
 SG_ P7B_Status : 0|3@1+ (1,0) [0|7] "" Vector__XXX
 SG_ P7B_Age : 0|8@1+ (1,0) [0|255] "" Vector__XXX
 SG_ P7B_A_lat_obj : 0|11@1+ (0.01,-10) [-10|10] "m/s^2" Vector__XXX
 SG_ P6B_V_lat_obj : 0|12@1+ (0.05,-20) [-20|20] "m/s" Vector__XXX
 SG_ P6B_FcwConfidence : 0|3@1+ (1,0) [0|1] "" Vector__XXX
 SG_ P6B_CmbbPrimaryConfidence : 0|3@1+ (1,0) [0|3] "" Vector__XXX
 SG_ P6B_Status : 0|3@1+ (1,0) [0|7] "" Vector__XXX
 SG_ P6B_Age : 0|8@1+ (1,0) [0|255] "" Vector__XXX
 SG_ P6B_A_lat_obj : 0|11@1+ (0.01,-10) [-10|10] "m/s^2" Vector__XXX
 SG_ P5B_V_lat_obj : 0|12@1+ (0.05,-20) [-20|20] "m/s" Vector__XXX
 SG_ P5B_FcwConfidence : 0|3@1+ (1,0) [0|1] "" Vector__XXX
 SG_ P5B_CmbbPrimaryConfidence : 0|3@1+ (1,0) [0|3] "" Vector__XXX
 SG_ P5B_Status : 0|3@1+ (1,0) [0|7] "" Vector__XXX
 SG_ P5B_Age : 0|8@1+ (1,0) [0|255] "" Vector__XXX
 SG_ P5B_A_lat_obj : 0|11@1+ (0.01,-10) [-10|10] "m/s^2" Vector__XXX
 SG_ P4B_V_lat_obj : 0|12@1+ (0.05,-20) [-20|20] "m/s" Vector__XXX
 SG_ P4B_FcwConfidence : 0|3@1+ (1,0) [0|1] "" Vector__XXX
 SG_ P4B_CmbbPrimaryConfidence : 0|3@1+ (1,0) [0|3] "" Vector__XXX
 SG_ P4B_Status : 0|3@1+ (1,0) [0|7] "" Vector__XXX
 SG_ P4B_Age : 0|8@1+ (1,0) [0|255] "" Vector__XXX
 SG_ P4B_A_lat_obj : 0|11@1+ (0.01,-10) [-10|10] "m/s^2" Vector__XXX
 SG_ P3B_V_lat_obj : 0|12@1+ (0.05,-20) [-20|20] "m/s" Vector__XXX
 SG_ P3B_FcwConfidence : 0|3@1+ (1,0) [0|1] "" Vector__XXX
 SG_ P3B_CmbbPrimaryConfidence : 0|3@1+ (1,0) [0|3] "" Vector__XXX
 SG_ P3B_Status : 0|3@1+ (1,0) [0|7] "" Vector__XXX
 SG_ P3B_Age : 0|8@1+ (1,0) [0|255] "" Vector__XXX
 SG_ P3B_A_lat_obj : 0|11@1+ (0.01,-10) [-10|10] "m/s^2" Vector__XXX
 SG_ P2B_V_lat_obj : 0|12@1+ (0.05,-20) [-20|20] "m/s" Vector__XXX
 SG_ P2B_FcwConfidence : 0|3@1+ (1,0) [0|1] "" Vector__XXX
 SG_ P2B_CmbbPrimaryConfidence : 0|3@1+ (1,0) [0|3] "" Vector__XXX
 SG_ P2B_Status : 0|3@1+ (1,0) [0|7] "" Vector__XXX
 SG_ P2B_Age : 0|8@1+ (1,0) [0|255] "" Vector__XXX
 SG_ P2B_A_lat_obj : 0|11@1+ (0.01,-10) [-10|10] "m/s^2" Vector__XXX
 SG_ PAA_V_long_obj : 0|12@1+ (0.05,-100) [-100|100] "m/s" Vector__XXX
 SG_ PAA_TrackID : 0|7@1+ (1,0) [0|64] "" Vector__XXX
 SG_ PAA_L_long_rel : 0|12@1+ (0.05,0) [0|180] "m" Vector__XXX
 SG_ PAA_L_lat_rel : 0|14@1+ (0.01,-50) [-50|50] "m" Vector__XXX
 SG_ PAA_A_long_obj : 0|12@1+ (0.01,-20) [-20|20] "m/s^2" Vector__XXX
 SG_ P9A_V_long_obj : 0|12@1+ (0.05,-100) [-100|100] "m/s" Vector__XXX
 SG_ P9A_TrackID : 0|7@1+ (1,0) [0|64] "" Vector__XXX
 SG_ P9A_L_long_rel : 0|12@1+ (0.05,0) [0|180] "m" Vector__XXX
 SG_ P9A_L_lat_rel : 0|14@1+ (0.01,-50) [-50|50] "m" Vector__XXX
 SG_ P9A_A_long_obj : 0|12@1+ (0.01,-20) [-20|20] "m/s^2" Vector__XXX
 SG_ P8A_V_long_obj : 0|12@1+ (0.05,-100) [-100|100] "m/s" Vector__XXX
 SG_ P8A_TrackID : 0|7@1+ (1,0) [0|64] "" Vector__XXX
 SG_ P8A_L_long_rel : 0|12@1+ (0.05,0) [0|180] "m" Vector__XXX
 SG_ P8A_L_lat_rel : 0|14@1+ (0.01,-50) [-50|50] "m" Vector__XXX
 SG_ P8A_A_long_obj : 0|12@1+ (0.01,-20) [-20|20] "m/s^2" Vector__XXX
 SG_ P7A_V_long_obj : 0|12@1+ (0.05,-100) [-100|100] "m/s" Vector__XXX
 SG_ P7A_TrackID : 0|7@1+ (1,0) [0|64] "" Vector__XXX
 SG_ P7A_L_long_rel : 0|12@1+ (0.05,0) [0|180] "m" Vector__XXX
 SG_ P7A_L_lat_rel : 0|14@1+ (0.01,-50) [-50|50] "m" Vector__XXX
 SG_ P7A_A_long_obj : 0|12@1+ (0.01,-20) [-20|20] "m/s^2" Vector__XXX
 SG_ P6A_L_lat_rel : 0|14@1+ (0.01,-50) [-50|50] "m" Vector__XXX
 SG_ P6A_A_long_obj : 0|12@1+ (0.01,-20) [-20|20] "m/s^2" Vector__XXX
 SG_ P6A_V_long_obj : 0|12@1+ (0.05,-100) [-100|100] "m/s" Vector__XXX
 SG_ P6A_L_long_rel : 0|12@1+ (0.05,0) [0|180] "m" Vector__XXX
 SG_ P6A_TrackID : 0|7@1+ (1,0) [0|64] "" Vector__XXX
 SG_ P5A_L_lat_rel : 0|14@1+ (0.01,-50) [-50|50] "m" Vector__XXX
 SG_ P5A_A_long_obj : 0|12@1+ (0.01,-20) [-20|20] "m/s^2" Vector__XXX
 SG_ P5A_V_long_obj : 0|12@1+ (0.05,-100) [-100|100] "m/s" Vector__XXX
 SG_ P5A_L_long_rel : 0|12@1+ (0.05,0) [0|180] "m" Vector__XXX
 SG_ P5A_TrackID : 0|7@1+ (1,0) [0|64] "" Vector__XXX
 SG_ P4A_L_lat_rel : 0|14@1+ (0.01,-50) [-50|50] "m" Vector__XXX
 SG_ P4A_A_long_obj : 0|12@1+ (0.01,-20) [-20|20] "m/s^2" Vector__XXX
 SG_ P4A_V_long_obj : 0|12@1+ (0.05,-100) [-100|100] "m/s" Vector__XXX
 SG_ P4A_L_long_rel : 0|12@1+ (0.05,0) [0|180] "m" Vector__XXX
 SG_ P4A_TrackID : 0|7@1+ (1,0) [0|64] "" Vector__XXX
 SG_ P3A_L_lat_rel : 0|14@1+ (0.01,-50) [-50|50] "m" Vector__XXX
 SG_ P3A_A_long_obj : 0|12@1+ (0.01,-20) [-20|20] "m/s^2" Vector__XXX
 SG_ P3A_V_long_obj : 0|12@1+ (0.05,-100) [-100|100] "m/s" Vector__XXX
 SG_ P3A_L_long_rel : 0|12@1+ (0.05,0) [0|180] "m" Vector__XXX
 SG_ P3A_TrackID : 0|7@1+ (1,0) [0|64] "" Vector__XXX
 SG_ P2A_L_lat_rel : 0|14@1+ (0.01,-50) [-50|50] "m" Vector__XXX
 SG_ P2A_V_long_obj : 0|12@1+ (0.05,-100) [-100|100] "m/s" Vector__XXX
 SG_ P2A_A_long_obj : 0|12@1+ (0.01,-20) [-20|20] "m/s^2" Vector__XXX
 SG_ P2A_L_long_rel : 0|12@1+ (0.05,0) [0|180] "m" Vector__XXX
 SG_ P2A_TrackID : 0|7@1+ (1,0) [0|64] "" Vector__XXX
 SG_ P1B_Age : 0|8@1+ (1,0) [0|255] "" Vector__XXX
 SG_ P1B_V_lat_obj : 0|12@1+ (0.05,-20) [-20|20] "m/s" Vector__XXX
 SG_ P1B_FcwConfidence : 0|3@1+ (1,0) [0|1] "" Vector__XXX
 SG_ P1B_CmbbPrimaryConfidence : 0|3@1+ (1,0) [0|3] "" Vector__XXX
 SG_ P1B_Status : 0|3@1+ (1,0) [0|7] "" Vector__XXX
 SG_ P1B_A_lat_obj : 0|11@1+ (0.01,-10) [-10|10] "m/s^2" Vector__XXX
 SG_ ldp_Veh_status_check : 0|1@1+ (1,0) [0|1] "" Vector__XXX
 SG_ LKA_Handcode_diag_RC_Mask : 0|23@1- (1,0) [0|8388607] "" Vector__XXX
 SG_ Handcode_Diag_Validity_mask : 0|20@1- (1,0) [0|1048575] "" Vector__XXX
 SG_ LKA_Feature_diag_mask : 0|19@1- (1,0) [-262144|262143] "" Vector__XXX
 SG_ LKA_Feature_diag : 0|1@1+ (1,0) [0|1] "" Vector__XXX
 SG_ ldp_f_left_driver_suppression : 0|1@1+ (1,0) [0|1] "" Vector__XXX
 SG_ ldp_torq_req_from_right_w_PI : 0|8@1- (0.05,0) [-6.4|6.35] "" Vector__XXX
 SG_ ldp_torq_req_from_left_w_PI : 0|8@1- (0.05,0) [-6.4|6.35] "" Vector__XXX
 SG_ ldp_i_term_init_flags : 0|8@1+ (1,0) [0|255] "" Vector__XXX
 SG_ ldp_i_term_freeze_flags : 0|8@1+ (1,0) [0|255] "" Vector__XXX
 SG_ ldp_i_term : 0|8@1- (0.025,0) [-3.2|3.175] "" Vector__XXX
 SG_ ldp_f_hands_off_warning : 0|1@1+ (1,0) [0|1] "" Vector__XXX
 SG_ ldp_right_lane_change : 0|1@1+ (1,0) [0|1] "" Vector__XXX
 SG_ ldp_left_lane_change : 0|1@1+ (1,0) [0|1] "" Vector__XXX
 SG_ ldp_road_state : 0|1@1+ (1,0) [0|1] "" Vector__XXX
 SG_ ldp_f_right_curve : 0|1@1+ (1,0) [0|1] "" Vector__XXX
 SG_ ldp_f_left_curve : 0|1@1+ (1,0) [0|1] "" Vector__XXX
 SG_ ldp_valid_MM_lane_width : 0|1@1+ (1,0) [0|1] "" Vector__XXX
 SG_ ldp_valid_MM_curvature : 0|1@1+ (1,0) [0|1] "" Vector__XXX
 SG_ ldp_MM_turn_signal : 0|2@1+ (1,0) [0|3] "" Vector__XXX
 SG_ ldp_f_right_driver_suppression : 0|1@1+ (1,0) [0|1] "" Vector__XXX
 SG_ ldp_SysStatusInfo : 0|3@1+ (1,0) [0|7] "enum" Vector__XXX
 SG_ ldp_Veh_status_check_mask : 0|8@1- (1,0) [0|255] "" Vector__XXX
 SG_ LKA_Handcode_Comm_diag_Mask : 0|6@1- (1,0) [0|63] "" Vector__XXX
 SG_ ldp_hands_off_warning : 0|1@1+ (1,0) [0|1] "" Vector__XXX
 SG_ LKA_Moded_Torq_Req_w_LCT : 0|10@1- (0.01,0) [-5.12|5.11] "Nm" Vector__XXX
 SG_ ME_vision_fault : 0|1@1- (1,0) [0|1] "" Vector__XXX
 SG_ ldp_sw_version : 0|12@1+ (0.001,0) [0|4.095] "" Vector__XXX
 SG_ ldp_f_recent_turn_made : 0|1@1+ (1,0) [0|1] "" Vector__XXX
 SG_ ldp_LKAMode : 0|4@1+ (1,0) [0|8] "" Vector__XXX
 SG_ ldp_EPS_fault : 0|1@1+ (1,0) [0|1] "" Vector__XXX
 SG_ ldp_right_P_term : 0|8@1- (0.02,0) [-2.56|2.54] "" Vector__XXX
 SG_ ldp_left_P_term : 0|8@1- (0.02,0) [-2.56|2.54] "" Vector__XXX
 SG_ ldp_torq_req_from_right_raw : 0|10@1- (0.01,0) [-5.12|5.11] "Nm" Vector__XXX
 SG_ ldp_torq_req_from_left_raw : 0|10@1- (0.01,0) [-5.12|5.11] "Nm" Vector__XXX
 SG_ ldp_torq_req_from_right_mag_lim : 0|10@1- (0.01,0) [-5.12|5.11] "Nm" Vector__XXX
 SG_ ldp_torq_req_from_left_mag_lim : 0|10@1- (0.01,0) [-5.12|5.11] "Nm" Vector__XXX
 SG_ ldp_f_brake_pedal_inhibit : 0|1@1+ (1,0) [0|1] "" Vector__XXX
 SG_ ldp_f_accel_pedal_inhibit : 0|1@1+ (1,0) [0|1] "" Vector__XXX
 SG_ ldp_f_right_hi_conf : 0|1@1+ (1,0) [0|1] "" Vector__XXX
 SG_ ldp_f_left_hi_conf : 0|1@1+ (1,0) [0|1] "" Vector__XXX
 SG_ ldp_f_dist_right_mkr : 0|1@1+ (1,0) [0|1] "" Vector__XXX
 SG_ ldp_f_dist_left_mkr : 0|1@1+ (1,0) [0|1] "" Vector__XXX
 SG_ ldp_f_right_TTLC_lo_or_low_latR : 0|1@1+ (1,0) [0|1] "" Vector__XXX
 SG_ ldp_f_left_TTLC_lo_or_low_latR : 0|1@1+ (1,0) [0|1] "" Vector__XXX
 SG_ ldp_curr_right_dist_to_mkr : 0|12@1- (0.01,0) [-20.48|20.47] "m" Vector__XXX
 SG_ ldp_curr_left_dist_to_mkr : 0|12@1- (0.01,0) [-20.48|20.47] "m" Vector__XXX
 SG_ ldp_fut_host_abs_posn : 0|12@1- (0.01,0) [-20.48|20.47] "m" Vector__XXX
 SG_ ldp_curr_lane_width : 0|8@1+ (0.05,0) [0|12.75] "m" Vector__XXX
 SG_ ldp_curr_host_abs_posn : 0|12@1- (0.01,0) [-20.48|20.47] "m" Vector__XXX
 SG_ ldp_f_right_mkr_crossed : 0|1@1+ (1,0) [0|1] "" Vector__XXX
 SG_ ldp_f_sas_turning_right : 0|1@1+ (1,0) [0|1] "" Vector__XXX
 SG_ ldp_f_driv_override_right : 0|1@1+ (1,0) [0|1] "" Vector__XXX
 SG_ ldp_f_right_lane_aligned : 0|1@1+ (1,0) [0|1] "" Vector__XXX
 SG_ ldp_f_right_mrkr_valid : 0|1@1+ (1,0) [0|1] "" Vector__XXX
 SG_ ldp_f_right_intervention_valid : 0|1@1+ (1,0) [0|1] "" Vector__XXX
 SG_ ldp_Final_Torq_Cmd : 0|10@1- (0.01,0) [-5.12|5.11] "Nm" Vector__XXX
 SG_ ldp_right_TTLC : 0|12@1- (0.005,0) [-10.24|10.235] "sec" Vector__XXX
 SG_ ldp_right_lane_heading : 0|12@1- (0.0025,0) [-5.12|5.1175] "deg" Vector__XXX
 SG_ ldp_right_lat_rate : 0|12@1- (0.01,0) [-20.48|20.47] "m/s" Vector__XXX
 SG_ ldp_fut_right_dist_to_mkr : 0|12@1- (0.005,0) [-10.24|10.235] "m" Vector__XXX
 SG_ ldp_f_left_mkr_crossed : 0|1@1+ (1,0) [0|1] "" Vector__XXX
 SG_ ldp_f_sas_turning_left : 0|1@1+ (1,0) [0|1] "" Vector__XXX
 SG_ ldp_f_driv_override_left : 0|1@1+ (1,0) [0|1] "" Vector__XXX
 SG_ ldp_f_left_lane_aligned : 0|1@1+ (1,0) [0|1] "" Vector__XXX
 SG_ ldp_f_left_mrkr_valid : 0|1@1+ (1,0) [0|1] "" Vector__XXX
 SG_ ldp_f_left_intervention_valid : 0|1@1+ (1,0) [0|1] "" Vector__XXX
 SG_ LKA_Moded_Torq_Req_raw : 0|10@1- (0.01,0) [-5.12|5.11] "Nm" Vector__XXX
 SG_ ldp_left_TTLC : 0|12@1- (0.005,0) [-10.24|10.235] "sec" Vector__XXX
 SG_ ldp_left_lane_heading : 0|12@1- (0.0025,0) [-5.12|5.1175] "deg" Vector__XXX
 SG_ ldp_left_lat_rate : 0|12@1- (0.01,0) [-20.48|20.47] "m/s" Vector__XXX
 SG_ ldp_fut_left_dist_to_mkr : 0|12@1- (0.005,0) [-10.24|10.235] "m" Vector__XXX
 SG_ MM_inhibit_flags : 0|10@0+ (1,0) [0|1023] "enum" Vector__XXX
 SG_ k_select_LDP_function : 0|1@0+ (1,0) [0|1] "" Vector__XXX
 SG_ ldp_f_misuse : 0|1@0+ (1,0) [0|1] "" Vector__XXX
 SG_ ldp_f_disable_LDP : 0|1@0+ (1,0) [0|1] "" Vector__XXX
 SG_ ldp_hands_off_warning : 0|1@0+ (1,0) [0|1] "" Vector__XXX
 SG_ ME_vision_fault : 0|1@0+ (1,0) [0|1] "" Vector__XXX
 SG_ ldp_sw_version : 0|12@0+ (0.001,0) [0|4.095] "" Vector__XXX
 SG_ ldp_f_recent_turn_made : 0|1@0+ (1,0) [0|1] "" Vector__XXX
 SG_ ldp_EPS_fault : 0|1@0+ (1,0) [0|0] "" Vector__XXX
 SG_ AHBC_Spd_Enable_debug : 0|1@0+ (1,0) [0|1] "" Vector__XXX
 SG_ AHBC_VIS_REASON_CODE : 0|20@0+ (1,0) [0|1048575] "Bit Mapped" Vector__XXX
 SG_ AHBC_StrucSepera_Apear_debug : 0|1@0+ (1,0) [0|1] "" Vector__XXX
 SG_ AHBC_ObjNum_debug : 0|5@0+ (1,0) [0|20] "" Vector__XXX
 SG_ AHBC_inhibit_temp : 0|20@0+ (1,0) [0|1048575] "Bit Mapped" Vector__XXX
 SG_ LKA_Handcode_Comm_diag_Mask : 0|6@1- (1,0) [0|63] "" Vector__XXX
 SG_ VIS_Spd_Indx_temp : 0|8@0+ (1,0) [0|20] "" Vector__XXX
 SG_ ldp_Veh_status_check_mask : 0|8@1- (1,0) [0|255] "" Vector__XXX
 SG_ ldp_Veh_status_check : 0|1@1- (1,0) [0|1] "" Vector__XXX
 SG_ LKA_Handcode_diag_RC_Mask : 0|23@1- (1,0) [0|8388607] "" Vector__XXX
 SG_ Handcode_Diag_Validity_mask : 0|20@1- (1,0) [0|1048575] "" Vector__XXX
 SG_ LKA_Feature_diag_mask : 0|11@1- (1,0) [0|2047] "" Vector__XXX
 SG_ LKA_Feature_diag : 0|1@1- (1,0) [0|1] "" Vector__XXX
 SG_ ldp_Final_Torq_Cmd : 0|10@1- (0.01,0) [-5.12|5.11] "Nm" Vector__XXX
 SG_ IMUSecondaryPlausibilityFault : 0|1@0+ (1,0) [0|0] "" Vector__XXX
 SG_ IMUPrimaryPlausibilityFault : 0|1@0+ (1,0) [0|0] "" Vector__XXX
 SG_ WSSPlausibilityFault : 0|1@0+ (1,0) [0|0] "" Vector__XXX
 SG_ SASPlausibilityFault : 0|1@0+ (1,0) [0|0] "" Vector__XXX
 SG_ SP_f_rlm_cutin : 0|1@0+ (1,0) [0|0] "" Vector__XXX
 SG_ SP_f_llm_cutin : 0|1@0+ (1,0) [0|0] "" Vector__XXX

BO_ 2 New_Message_97: 8 Vector__XXX
 SG_ New_Signal_2825 : 32|8@1+ (1,0) [0|0] "" Vector__XXX

BO_ 1 New_Message_96: 8 Vector__XXX
 SG_ New_Signal_2819 : 48|8@1+ (1,0) [0|0] "" Vector__XXX

BO_ 0 New_Message_95: 8 Vector__XXX
 SG_ New_Signal_2818 : 40|8@1+ (1,0) [0|0] "" Vector__XXX

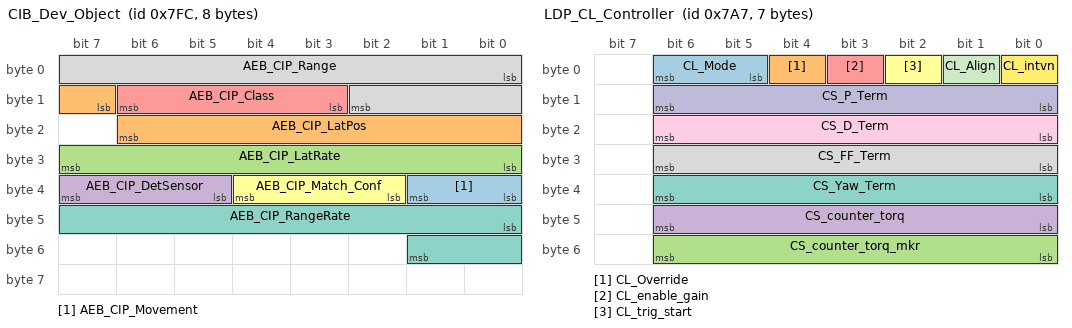
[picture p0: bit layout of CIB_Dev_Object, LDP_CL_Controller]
BO_ 2044 CIB_Dev_Object: 8 Vector__XXX
 SG_ AEB_CIP_Movement : 32|2@1+ (1,0) [0|3] "" Vector__XXX
 SG_ AEB_CIP_LatPos : 15|8@1- (0.1,0) [-12.8|12.7] "" Vector__XXX
 SG_ AEB_CIP_LatRate : 24|8@1- (0.1,0) [-12.8|12.7] "" Vector__XXX
 SG_ AEB_CIP_DetSensor : 37|3@1+ (1,0) [0|7] "" Vector__XXX
 SG_ AEB_CIP_Class : 11|4@1+ (1,0) [0|15] "" Vector__XXX
 SG_ AEB_CIP_Match_Conf : 34|3@1+ (1,0) [0|7] "" Vector__XXX
 SG_ AEB_CIP_RangeRate : 40|10@1- (0.1,0) [-51.2|51.1] "" Vector__XXX
 SG_ AEB_CIP_Range : 0|11@1+ (0.1,0) [0|204.7] "" Vector__XXX

BO_ 2043 CIB_Dev_Threshold_2: 8 Vector__XXX
 SG_ AEB_IMULonAcc : 32|12@1- (0.01,0) [-20.48|20.47] "" Vector__XXX
 SG_ AEB_LowBrakeAccelOffset : 16|16@1- (0.001,0) [-32.768|32.767] "" Vector__XXX
 SG_ AEB_Low_Annoying : 0|16@1- (0.001,0) [-32.768|32.767] "" Vector__XXX

BO_ 2042 CIB_Dev_Threshold_1: 8 Vector__XXX
 SG_ AEB_HiBrakeAccelOffset : 48|16@1- (0.001,0) [-32.768|32.767] "" Vector__XXX
 SG_ AEB_High_Thresh : 32|16@1- (0.001,0) [-32.768|32.767] "" Vector__XXX
 SG_ AEB_Low_Thresh : 16|16@1- (0.001,0) [-32.768|32.767] "" Vector__XXX
 SG_ AEB_Prefill_Thresh : 0|16@1- (0.001,0) [-32.768|32.767] "" Vector__XXX

BO_ 1959 LDP_CL_Controller: 7 dSPACE
 SG_ CL_Mode : 5|2@1+ (1,0) [0|3] "" Vector__XXX
 SG_ CL_Override : 4|1@1+ (1,0) [0|1] "" Vector__XXX
 SG_ CS_counter_torq_mkr : 48|7@1- (0.05,0) [-3.2|3.15] "Nm" Vector__XXX
 SG_ CS_counter_torq : 40|7@1- (0.05,0) [-3.2|3.15] "Nm" Vector__XXX
 SG_ CL_enable_gain : 3|1@1+ (1,0) [0|1] "" Vector__XXX
 SG_ CL_trig_start : 2|1@1+ (1,0) [0|1] "" Vector__XXX
 SG_ CS_Yaw_Term : 32|7@1- (0.05,0) [-3.2|3.15] "Nm" Vector__XXX
 SG_ CS_FF_Term : 24|7@1- (0.05,0) [-3.2|3.15] "Nm" Vector__XXX
 SG_ CS_D_Term : 16|7@1- (0.05,0) [-3.2|3.15] "Nm" Vector__XXX
 SG_ CS_P_Term : 8|7@1- (0.05,0) [-3.2|3.15] "Nm" Vector__XXX
 SG_ CL_Align : 1|1@1+ (1,0) [0|1] "" Vector__XXX
 SG_ CL_intvn : 0|1@1+ (1,0) [0|1] "" Vector__XXX

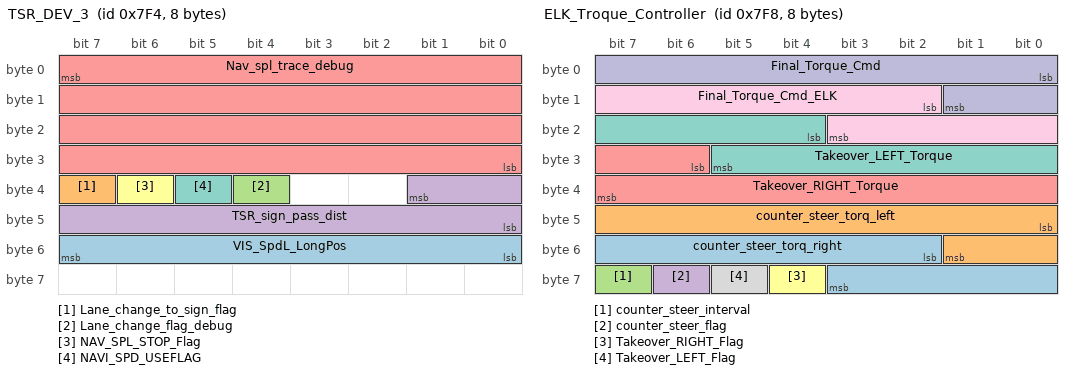
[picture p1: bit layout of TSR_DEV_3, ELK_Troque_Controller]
BO_ 2036 TSR_DEV_3: 8 dSPACE
 SG_ VIS_SpdL_LongPos : 55|8@0+ (1,0) [0|255] "" Vector__XXX
 SG_ Lane_change_to_sign_flag : 39|1@0+ (1,0) [0|1] "boolean" Vector__XXX
 SG_ Lane_change_flag_debug : 36|1@0+ (1,0) [0|1] "boolean" Vector__XXX
 SG_ TSR_sign_pass_dist : 33|10@0+ (0.1,0) [0|102.3] "m" Vector__XXX
 SG_ Nav_spl_trace_debug : 7|32@0- (0.01,0) [-5000|50000] "m" Vector__XXX
 SG_ NAV_SPL_STOP_Flag : 38|1@0+ (1,0) [0|1] "boolean" Vector__XXX
 SG_ NAVI_SPD_USEFLAG : 37|1@0+ (1,0) [0|1] "boolean" Vector__XXX

BO_ 2040 ELK_Troque_Controller: 8 Vector__XXX
 SG_ counter_steer_torq_right : 50|10@1- (0.01,0) [-5.12|5.11] "Nm" Vector__XXX
 SG_ counter_steer_torq_left : 40|10@1- (0.01,0) [-5.12|5.11] "Nm" Vector__XXX
 SG_ counter_steer_interval : 63|1@1+ (1,0) [0|1] "" Vector__XXX
 SG_ counter_steer_flag : 62|1@1+ (1,0) [0|1] "" Vector__XXX
 SG_ Takeover_RIGHT_Torque : 30|10@1- (0.01,0) [-5.12|5.11] "Nm" Vector__XXX
 SG_ Takeover_RIGHT_Flag : 60|1@1+ (1,0) [0|1] "" Vector__XXX
 SG_ Takeover_LEFT_Torque : 20|10@1- (0.01,0) [-5.12|5.11] "Nm" Vector__XXX
 SG_ Takeover_LEFT_Flag : 61|1@1+ (1,0) [0|1] "" Vector__XXX
 SG_ Final_Torque_Cmd_ELK : 10|10@1- (0.01,0) [-5.12|5.11] "Nm" Vector__XXX
 SG_ Final_Torque_Cmd : 0|10@1- (0.01,0) [-5.12|5.11] "Nm" Vector__XXX

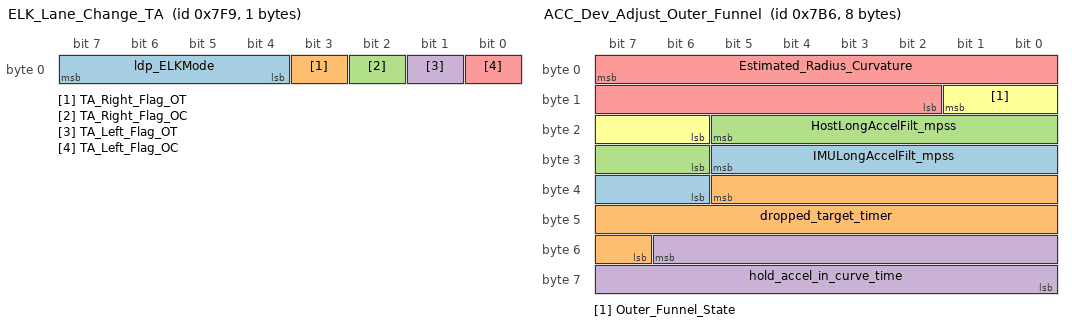
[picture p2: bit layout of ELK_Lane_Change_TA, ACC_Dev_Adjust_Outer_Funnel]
BO_ 2041 ELK_Lane_Change_TA: 1 Vector__XXX
 SG_ ldp_ELKMode : 4|4@1+ (1,0) [0|8] "" Vector__XXX
 SG_ TA_Right_Flag_OT : 3|1@1+ (1,0) [0|1] "" Vector__XXX
 SG_ TA_Right_Flag_OC : 2|1@1+ (1,0) [0|1] "" Vector__XXX
 SG_ TA_Left_Flag_OT : 1|1@1+ (1,0) [0|1] "" Vector__XXX
 SG_ TA_Left_Flag_OC : 0|1@1+ (1,0) [0|1] "" Vector__XXX

BO_ 2027 ILC2: 8 Vector__XXX
 SG_ SP_A1_ILC : 55|16@0- (0.01,0) [0|0] "" Vector__XXX
 SG_ SP_A0_ILC : 39|16@0- (0.01,0) [0|0] "" Vector__XXX
 SG_ x_f : 23|16@0+ (0.1,0) [0|0] "" Vector__XXX
 SG_ y_f_ref : 7|16@0- (0.1,0) [0|0] "" Vector__XXX

BO_ 2026 ILC1: 8 Vector__XXX
 SG_ preview_range_ALC_P1 : 15|16@0+ (0.1,0) [0|0] "" Vector__XXX
 SG_ ALC_phase_debug : 4|4@0+ (0.5,0) [0|0] "" Vector__XXX
 SG_ ALC_P1_active : 5|1@0+ (1,0) [0|0] "" Vector__XXX
 SG_ ALC_done : 6|1@0+ (1,0) [0|0] "" Vector__XXX
 SG_ ALC_active : 7|1@0+ (1,0) [0|0] "" Vector__XXX

BO_ 2035 TSR_DEV_2: 8 dSPACE
 SG_ TSR_Latch_dist : 51|12@0- (0.1,0) [-200|200] "m" Vector__XXX
 SG_ VIS_trace_dist : 29|26@0- (0.1,0) [-5000|50000] "m" Vector__XXX
 SG_ VIS_Spd_temp : 21|8@0+ (1,0) [0|250] "k/mph" Vector__XXX
 SG_ VIS_Spd_Conf_temp : 15|10@0+ (0.001,0) [0|1] "" Vector__XXX
 SG_ VIS_disp_value : 7|8@0+ (1,0) [0|255] "km/h" Vector__XXX

BO_ 2025 LaneBias: 8 Vector__XXX
 SG_ RightLaneBias2ACTIVE_Magic_Out : 55|16@0+ (1,0) [0|0] "" Vector__XXX
 SG_ LeftLaneBias2ACTIVE_Magic_Out : 39|16@0+ (1,0) [0|0] "" Vector__XXX
 SG_ ACTIVE2RightLaneBias_Magic_Out : 23|16@0+ (1,0) [0|0] "" Vector__XXX
 SG_ ACTIVE2LeftLaneBias_Magic_Out : 7|16@0+ (1,0) [0|0] "" Vector__XXX

BO_ 1983 ACC_Dev_Extra_Info: 8 dSPACE
 SG_ ACCBSCE_AutBrkTp : 2|3@1+ (1,0) [0|0] "" Vector__XXX
 SG_ Auto_Resume_OK : 1|1@1+ (1,0) [0|0] "" Vector__XXX
 SG_ Go_Notifier_Request : 0|1@1+ (1,0) [0|0] "" Vector__XXX

BO_ 2008 TJA_Dev_Disengage: 8 dSPACE
 SG_ TJA_Last_Disengage_Magic_3 : 55|16@0+ (1,0) [0|0] "" Vector__XXX
 SG_ TJA_Last_Disengage_Magic_2 : 39|16@0+ (1,0) [0|0] "" Vector__XXX
 SG_ TJA_Last_Disengage_Magic_1 : 23|16@0+ (1,0) [0|0] "" Vector__XXX
 SG_ TJA_Last_Disengage_Magic_0 : 7|16@0+ (1,0) [0|0] "" Vector__XXX

BO_ 2007 TJA_Develop_Info: 7 dSPACE
 SG_ TJA_wait_hold_release : 36|1@0+ (1,0) [0|1] "" Vector__XXX
 SG_ TJA_InvalidDrv_TillStop : 16|1@0+ (1,0) [0|1] "" Vector__XXX
 SG_ TJA_Active_ACCOnly : 17|1@0+ (1,0) [0|1] "" Vector__XXX
 SG_ TJA_Allow_Activation_Magic : 55|8@0+ (1,0) [0|0] "" Vector__XXX
 SG_ LatCtlRampType_Rq : 38|2@0+ (1,0) [0|3] "" Vector__XXX
 SG_ TJA_Warn_Disp_Rq : 47|2@0+ (1,0) [0|3] "" Vector__XXX
 SG_ TJA_Res_Rq : 45|1@0+ (1,0) [0|1] "" Vector__XXX
 SG_ TJA_Mode : 29|4@0+ (1,0) [0|15] "" Vector__XXX
 SG_ TJA_LatCtrl_Rq : 39|1@0+ (1,0) [0|1] "" Vector__XXX
 SG_ TJA_ACC_Rq : 25|2@0+ (1,0) [0|3] "" Vector__XXX
 SG_ TJA_UcrtLocation_flg : 20|1@0+ (1,0) [0|1] "none" Vector__XXX
 SG_ TJA_handsoff_Warning : 44|1@0+ (1,0) [0|1] "" Vector__XXX
 SG_ TJA_Situation_enum : 19|2@0+ (1,0) [0|3] "" Vector__XXX
 SG_ TJA_DrvCancel_flg : 21|1@0+ (1,0) [0|1] "none" Vector__XXX
 SG_ TJA_Drv_OvRd_enum : 31|2@0+ (1,0) [0|3] "" Vector__XXX
 SG_ TJA_DriverInvalid_flg : 22|1@0+ (1,0) [0|1] "none" Vector__XXX
 SG_ TJA_Allow_Activation : 23|1@0+ (1,0) [0|1] "" Vector__XXX
 SG_ TJA_VehInvalid_Magic : 7|16@0+ (1,0) [0|65535] "" Vector__XXX

BO_ 1988 CIB_Inhibits_5_4: 8 dSPACE
 SG_ CIB_Inhibit_5_Flags : 7|32@0+ (1,0) [0|0] "Bit Mapped" Vector__XXX
 SG_ CIB_Inhibit_4_Flags : 39|32@0+ (1,0) [0|0] "Bit Mapped" Vector__XXX

BO_ 1987 CIB_Inhibits_3_2: 8 dSPACE
 SG_ CIB_Inhibit_2_Flags : 39|32@0+ (1,0) [0|0] "Bit Mapped" Vector__XXX
 SG_ CIB_Inhibit_3_Flags : 7|32@0+ (1,0) [0|0] "Bit Mapped" Vector__XXX

BO_ 1986 CIB_Inhibits_1_0: 8 dSPACE
 SG_ CIB_Inhibit_0_Flags : 39|32@0+ (1,0) [0|0] "Bit Mapped" Vector__XXX
 SG_ CIB_Inhibit_1_Flags : 7|32@0+ (1,0) [0|0] "Bit Mapped" Vector__XXX

BO_ 1994 FCW_Inhibits_5_4: 8 dSPACE
 SG_ FCW_Inhibit_5_Flags : 7|32@0+ (1,0) [0|0] "Bit Mapped" Vector__XXX
 SG_ FCW_Inhibit_4_Flags : 39|32@0+ (1,0) [0|0] "Bit Mapped" Vector__XXX

BO_ 1993 FCW_Inhibits_3_2: 8 dSPACE
 SG_ FCW_Inhibit_2_Flags : 39|32@0+ (1,0) [0|0] "Bit Mapped" Vector__XXX
 SG_ FCW_Inhibit_3_Flags : 7|32@0+ (1,0) [0|0] "Bit Mapped" Vector__XXX

BO_ 1992 FCW_Inhibits_1_0: 8 dSPACE
 SG_ FCW_Inhibit_1_Flags : 7|32@0+ (1,0) [0|0] "Bit Mapped" Vector__XXX
 SG_ FCW_Inhibit_0_Flags : 39|32@0+ (1,0) [0|0] "Bit Mapped" Vector__XXX

BO_ 1973 ACC_Dev_Diseng_5_4: 8 dSPACE
 SG_ Disengage_ACC_5_Flags : 7|32@0+ (1,0) [0|0] "Bit Mapped" Vector__XXX
 SG_ Disengage_ACC_4_Flags : 39|32@0+ (1,0) [0|0] "Bit Mapped" Vector__XXX

BO_ 1972 ACC_Dev_Diseng_3_2: 8 dSPACE
 SG_ Disengage_ACC_2_Flags : 39|32@0+ (1,0) [0|0] "Bit Mapped" Vector__XXX
 SG_ Disengage_ACC_3_Flags : 7|32@0+ (1,0) [0|0] "Bit Mapped" Vector__XXX

BO_ 1971 ACC_Dev_Diseng_1_0: 8 dSPACE
 SG_ Disengage_ACC_0_Flags : 39|32@0+ (1,0) [0|0] "Bit Mapped" Vector__XXX
 SG_ Disengage_ACC_1_Flags : 7|32@0+ (1,0) [0|0] "Bit Mapped" Vector__XXX

BO_ 1970 ACC_Dev_Inh_5_4: 8 dSPACE
 SG_ Inhibit_ACC_4_Flags : 39|32@0+ (1,0) [0|0] "Bit Mapped" Vector__XXX
 SG_ Inhibit_ACC_5_Flags : 7|32@0+ (1,0) [0|0] "Bit Mapped" Vector__XXX

BO_ 1969 ACC_Dev_Inh_3_2: 8 dSPACE
 SG_ Inhibit_ACC_2_Flags : 39|32@0+ (1,0) [0|0] "Bit Mapped" Vector__XXX
 SG_ Inhibit_ACC_3_Flags : 7|32@0+ (1,0) [0|0] "Bit Mapped" Vector__XXX

BO_ 1968 ACC_Dev_Inh_1_0: 8 dSPACE
 SG_ Inhibit_ACC_0_Flags : 39|32@0+ (1,0) [0|0] "Bit Mapped" Vector__XXX
 SG_ Inhibit_ACC_1_Flags : 7|32@0+ (1,0) [0|0] "Bit Mapped" Vector__XXX

BO_ 1974 ACC_Dev_Adjust_Outer_Funnel: 8 dSPACE
 SG_ IMULongAccelFilt_mpss : 29|8@0- (0.0625,0) [-8|7.9375] "mpss" Vector__XXX
 SG_ dropped_target_timer : 37|15@0+ (1,0) [0|32767] "" Vector__XXX
 SG_ HostLongAccelFilt_mpss : 21|8@0- (0.0625,0) [-8|7.9375] "mpss" Vector__XXX
 SG_ hold_accel_in_curve_time : 54|15@0+ (1,0) [0|32767] "sec" Vector__XXX
 SG_ Estimated_Radius_Curvature : 7|14@0- (1,0) [-8192|8191] "m" Vector__XXX
 SG_ Outer_Funnel_State : 9|4@0+ (1,0) [0|8] "Enum" Vector__XXX

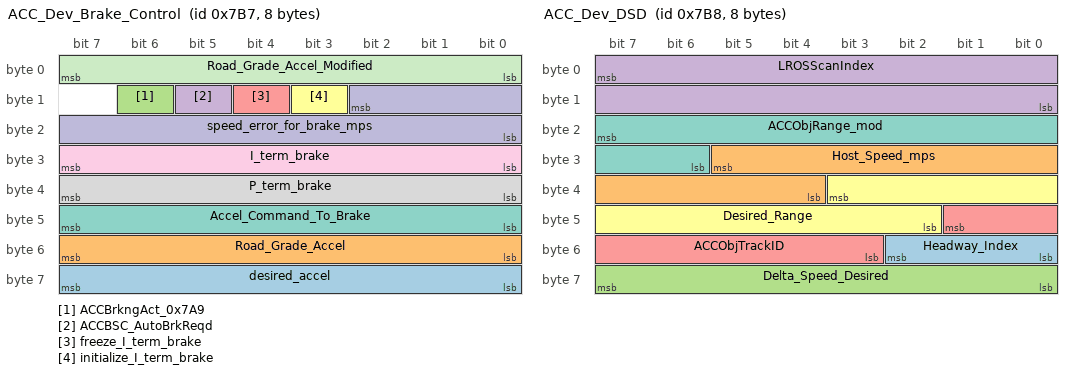
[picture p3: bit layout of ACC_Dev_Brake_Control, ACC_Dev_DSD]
BO_ 1975 ACC_Dev_Brake_Control: 8 dSPACE
 SG_ desired_accel : 63|8@0- (0.0625,0) [-8|7.9375] "mpss" Vector__XXX
 SG_ Road_Grade_Accel : 55|8@0- (0.0625,0) [-8|7.9375] "mpss" Vector__XXX
 SG_ ACCBrkngAct_0x7A9 : 14|1@0+ (1,0) [0|0] "" Vector__XXX
 SG_ ACCBSC_AutoBrkReqd : 13|1@0+ (1,0) [0|0] "" Vector__XXX
 SG_ freeze_I_term_brake : 12|1@0+ (1,0) [0|0] "" Vector__XXX
 SG_ initialize_I_term_brake : 11|1@0+ (1,0) [0|0] "" Vector__XXX
 SG_ Accel_Command_To_Brake : 47|8@0- (0.0625,0) [-8|7.9375] "mpss" Vector__XXX
 SG_ P_term_brake : 39|8@0- (0.0625,0) [-8|7.9375] "mpss" Vector__XXX
 SG_ I_term_brake : 31|8@0- (0.0625,0) [-8|7.9375] "mpss" Vector__XXX
 SG_ speed_error_for_brake_mps : 10|11@0- (0.0625,0) [-64|63.9375] "mps" Vector__XXX
 SG_ Road_Grade_Accel_Modified : 7|8@0- (0.0625,0) [-8|7.9375] "mpss" Vector__XXX

BO_ 1976 ACC_Dev_DSD: 8 dSPACE
 SG_ Headway_Index : 50|3@0+ (1,0) [0|7] "table index" Vector__XXX
 SG_ Host_Speed_mps : 29|10@0+ (0.0625,0) [0|63.9375] "m/sec" Vector__XXX
 SG_ Delta_Speed_Desired : 63|8@0- (0.0625,0) [-8|7.9375] "m/sec^2" Vector__XXX
 SG_ LROSScanIndex : 7|16@0+ (1,0) [0|65535] "Counts" Vector__XXX
 SG_ ACCObjTrackID : 41|7@0+ (1,0) [0|127] "Counts" Vector__XXX
 SG_ Desired_Range : 35|10@0+ (0.25,0) [0|255.75] "Meters" Vector__XXX
 SG_ ACCObjRange_mod : 23|10@0+ (0.25,0) [0|255.75] "Meters" Vector__XXX

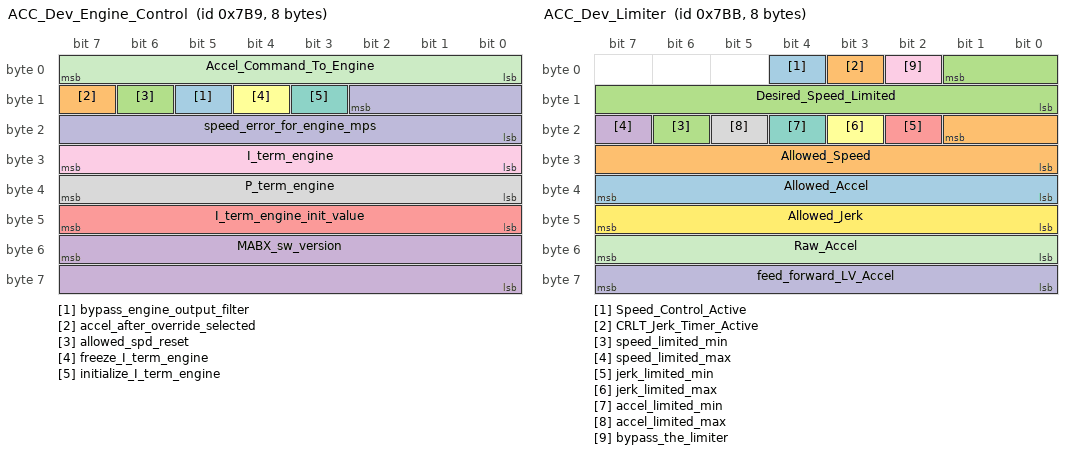
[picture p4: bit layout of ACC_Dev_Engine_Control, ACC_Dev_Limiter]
BO_ 1977 ACC_Dev_Engine_Control: 8 dSPACE
 SG_ bypass_engine_output_filter : 13|1@0+ (1,0) [0|0] "" Vector__XXX
 SG_ accel_after_override_selected : 15|1@0+ (1,0) [0|1] "Boolean" Vector__XXX
 SG_ allowed_spd_reset : 14|1@0+ (1,0) [0|1] "Boolean" Vector__XXX
 SG_ MABX_sw_version : 55|16@0+ (0.001,0) [0|65.535] "" Vector__XXX
 SG_ I_term_engine_init_value : 47|8@0- (0.0625,0) [-8|7.9375] "mpss" Vector__XXX
 SG_ freeze_I_term_engine : 12|1@0+ (1,0) [0|0] "" Vector__XXX
 SG_ initialize_I_term_engine : 11|1@0+ (1,0) [0|0] "" Vector__XXX
 SG_ P_term_engine : 39|8@0- (0.0625,0) [-8|7.9375] "mpss" Vector__XXX
 SG_ I_term_engine : 31|8@0- (0.0625,0) [-8|7.9375] "mpss" Vector__XXX
 SG_ speed_error_for_engine_mps : 10|11@0- (0.0625,0) [-64|63.9375] "mps" Vector__XXX
 SG_ Accel_Command_To_Engine : 7|8@0- (0.0625,0) [-8|7.9375] "mpss" Vector__XXX

BO_ 1978 ACC_Dev_Engine_Control_2: 8 dSPACE
 SG_ freeze_engine_integrator_flags : 7|32@0+ (1,0) [0|0] "Bit Mapped" Vector__XXX

BO_ 1979 ACC_Dev_Limiter: 8 dSPACE
 SG_ Speed_Control_Active : 4|1@0+ (1,0) [0|1] "" Vector__XXX
 SG_ CRLT_Jerk_Timer_Active : 3|1@0+ (1,0) [0|1] "" Vector__XXX
 SG_ speed_limited_min : 22|1@0+ (1,0) [0|0] "" Vector__XXX
 SG_ speed_limited_max : 23|1@0+ (1,0) [0|0] "" Vector__XXX
 SG_ jerk_limited_min : 18|1@0+ (1,0) [0|0] "" Vector__XXX
 SG_ jerk_limited_max : 19|1@0+ (1,0) [0|0] "" Vector__XXX
 SG_ accel_limited_min : 20|1@0+ (1,0) [0|0] "" Vector__XXX
 SG_ accel_limited_max : 21|1@0+ (1,0) [0|0] "" Vector__XXX
 SG_ bypass_the_limiter : 2|1@0+ (1,0) [0|0] "" Vector__XXX
 SG_ feed_forward_LV_Accel : 63|8@0- (0.0625,0) [-8|7.9375] "mpss" Vector__XXX
 SG_ Raw_Accel : 55|8@0- (0.0625,0) [-8|7.9375] "mpss" Vector__XXX
 SG_ Allowed_Jerk : 47|8@0- (0.1,0) [-12.8|12.7] "mpsss" Vector__XXX
 SG_ Allowed_Accel : 39|8@0- (0.0625,0) [-8|7.9375] "mpss" Vector__XXX
 SG_ Allowed_Speed : 17|10@0+ (0.0625,0) [0|63.9375] "mps" Vector__XXX
 SG_ Desired_Speed_Limited : 1|10@0+ (0.0625,0) [0|63.9375] "mps" Vector__XXX

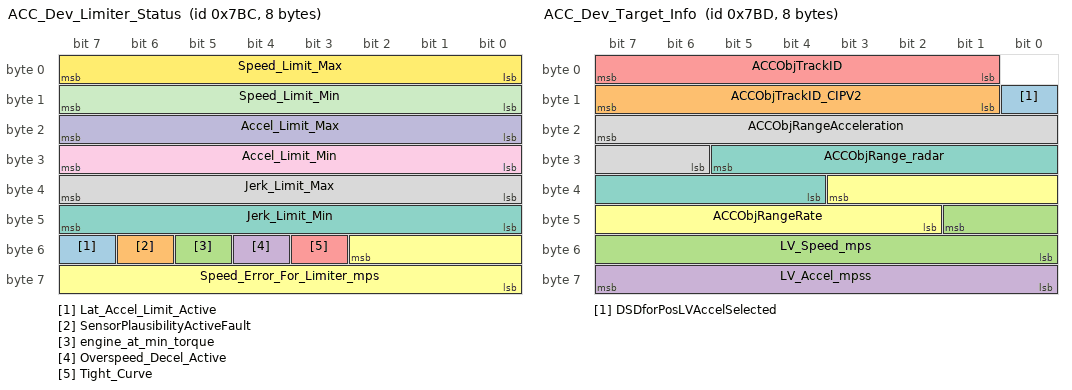
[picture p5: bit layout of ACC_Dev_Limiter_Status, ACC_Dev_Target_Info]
BO_ 1980 ACC_Dev_Limiter_Status: 8 dSPACE
 SG_ Lat_Accel_Limit_Active : 55|1@0+ (1,0) [0|0] "" Vector__XXX
 SG_ SensorPlausibilityActiveFault : 54|1@0+ (1,0) [0|0] "" Vector__XXX
 SG_ engine_at_min_torque : 53|1@0+ (1,0) [0|0] "" Vector__XXX
 SG_ Overspeed_Decel_Active : 52|1@0+ (1,0) [0|0] "" Vector__XXX
 SG_ Tight_Curve : 51|1@0+ (1,0) [0|0] "" Vector__XXX
 SG_ Speed_Error_For_Limiter_mps : 50|11@0- (0.0625,0) [-64|63.9375] "mps" Vector__XXX
 SG_ Jerk_Limit_Min : 47|8@0- (0.1,0) [-12.8|12.7] "mpsss" Vector__XXX
 SG_ Jerk_Limit_Max : 39|8@0- (0.1,0) [-12.8|12.7] "mpsss" Vector__XXX
 SG_ Accel_Limit_Min : 31|8@0- (0.0625,-2) [-10|5.9375] "mpss" Vector__XXX
 SG_ Accel_Limit_Max : 23|8@0- (0.0625,0) [-8|7.9375] "mpss" Vector__XXX
 SG_ Speed_Limit_Min : 15|8@0+ (0.25,0) [0|64] "mps" Vector__XXX
 SG_ Speed_Limit_Max : 7|8@0+ (0.25,0) [0|64] "mps" Vector__XXX

BO_ 1981 ACC_Dev_Target_Info: 8 dSPACE
 SG_ DSDforPosLVAccelSelected : 8|1@0+ (1,0) [0|1] "Boolean" Vector__XXX
 SG_ ACCObjTrackID_CIPV2 : 15|7@0+ (1,0) [0|127] "Counts" Vector__XXX
 SG_ LV_Speed_mps : 41|10@0+ (0.0625,0) [0|64] "mps" Vector__XXX
 SG_ LV_Accel_mpss : 63|8@0- (0.0625,0) [-8|7.9375] "mpss" Vector__XXX
 SG_ ACCObjTrackID : 7|7@0+ (1,0) [0|127] "Counts" Vector__XXX
 SG_ ACCObjRangeRate : 35|10@0- (0.125,0) [-64|63.875] "mps" Vector__XXX
 SG_ ACCObjRange_radar : 29|10@0+ (0.25,0) [0|255.75] "Meters" Vector__XXX
 SG_ ACCObjRangeAcceleration : 23|10@0- (0.05,0) [-25.6|25.55] "m/s/s" Vector__XXX

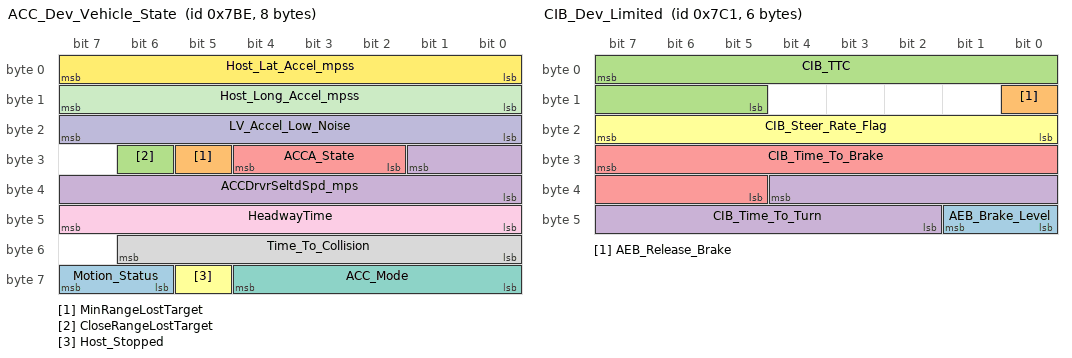
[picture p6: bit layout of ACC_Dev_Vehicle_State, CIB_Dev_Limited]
BO_ 1982 ACC_Dev_Vehicle_State: 8 dSPACE
 SG_ Motion_Status : 63|2@0+ (1,0) [0|3] "" Vector__XXX
 SG_ MinRangeLostTarget : 29|1@0+ (1,0) [0|1] "" Vector__XXX
 SG_ CloseRangeLostTarget : 30|1@0+ (1,0) [0|1] "" Vector__XXX
 SG_ ACCDrvrSeltdSpd_mps : 25|10@0+ (0.0625,0) [0|63.9375] "m/sec" Vector__XXX
 SG_ ACCA_State : 28|3@0+ (1,0) [0|0] "Enum" Vector__XXX
 SG_ Host_Stopped : 61|1@0+ (1,0) [0|0] "" Vector__XXX
 SG_ ACC_Mode : 60|5@0+ (1,0) [0|31] "ENUM" Vector__XXX
 SG_ Time_To_Collision : 54|7@0+ (0.25,0) [0|32] "sec" Vector__XXX
 SG_ HeadwayTime : 47|8@0+ (0.05,0) [0|12.75] "Sec" Vector__XXX
 SG_ LV_Accel_Low_Noise : 23|8@0- (0.0625,0) [-8|7.9375] "mpss" Vector__XXX
 SG_ Host_Long_Accel_mpss : 15|8@0- (0.0625,0) [-8|7.9375] "mpss" Vector__XXX
 SG_ Host_Lat_Accel_mpss : 7|8@0- (0.0625,0) [-8|7.9375] "mpss" Vector__XXX

BO_ 1984 CIB_Dev_Data: 8 dSPACE
 SG_ CIB_PCSEntryGatePassed : 59|1@0+ (1,0) [0|1] "Enum" Vector__XXX
 SG_ CIB_LowBrakeDeploy : 62|1@0+ (1,0) [0|1] "Enum" Vector__XXX
 SG_ CIB_HighBrakeDeploy : 61|1@0+ (1,0) [0|1] "Enum" Vector__XXX
 SG_ CIB_InPathGatePassed : 60|1@0+ (1,0) [0|1] "Enum" Vector__XXX
 SG_ CIB_ProcessCmbbTrack : 58|1@0+ (1,0) [0|1] "Enum" Vector__XXX
 SG_ CIB_ProcessEachTrack : 57|1@0+ (1,0) [0|1] "Enum" Vector__XXX
 SG_ CIB_NewTrackData : 56|1@0+ (1,0) [0|1] "Enum" Vector__XXX
 SG_ CIB_PCSAlgoEntered : 50|1@0+ (1,0) [0|1] "Enum" Vector__XXX
 SG_ CIB_StationaryObjectDelay_On : 5|1@0+ (1,0) [0|1] "Enum" Vector__XXX
 SG_ CIB_Inhibit_Steering_OR : 4|1@0+ (1,0) [0|1] "Enum" Vector__XXX
 SG_ CIB_Steering_OR : 3|1@0+ (1,0) [0|1] "Enum" Vector__XXX
 SG_ CIB_OverrideTimer_On : 2|1@0+ (1,0) [0|1] "Enum" Vector__XXX
 SG_ CIB_HighBrakeTimer_On : 1|1@0+ (1,0) [0|1] "Enum" Vector__XXX
 SG_ CIB_GasPedal_OR : 0|1@0+ (1,0) [0|1] "Enum" Vector__XXX
 SG_ CIB_Activation_Target_ID : 41|7@0- (1,0) [0|64] "Track No." Vector__XXX
 SG_ CIB_Time_To_Turn : 36|11@0+ (0.015625,0) [0|31.984375] "Sec" Vector__XXX
 SG_ CIB_Time_To_Brake : 31|11@0+ (0.015625,0) [0|31.984375] "Sec" Vector__XXX
 SG_ CIB_Steer_Rate_Flag : 23|8@0+ (1,0) [0|0] "Counts" Vector__XXX
 SG_ CIB_Filt_Accel_mpss : 15|8@0- (0.0625,0) [-8|7.9375] "mpss" Vector__XXX
 SG_ CIB_FCW : 7|1@0+ (1,0) [0|0] "Boolean" Vector__XXX
 SG_ CIB_Brake_Release : 6|1@0+ (1,0) [0|0] "boolean" Vector__XXX
 SG_ CIB_Brake_Level : 49|3@0+ (1,0) [0|0] "Enum" Vector__XXX

BO_ 1985 CIB_Dev_Limited: 6 dSPACE
 SG_ AEB_Brake_Level : 40|2@1- (1,0) [0|6] "" Vector__XXX
 SG_ AEB_Release_Brake : 8|1@1- (1,0) [0|1] "" Vector__XXX
 SG_ CIB_TTC : 7|11@0+ (0.015625,0) [0|31.984375] "Sec" Vector__XXX
 SG_ CIB_Time_To_Turn : 36|11@0+ (0.015625,0) [0|31.984375] "Sec" Vector__XXX
 SG_ CIB_Time_To_Brake : 31|11@0+ (0.015625,0) [0|31.984375] "Sec" Vector__XXX
 SG_ CIB_Steer_Rate_Flag : 23|8@0+ (1,0) [0|0] "Counts" Vector__XXX

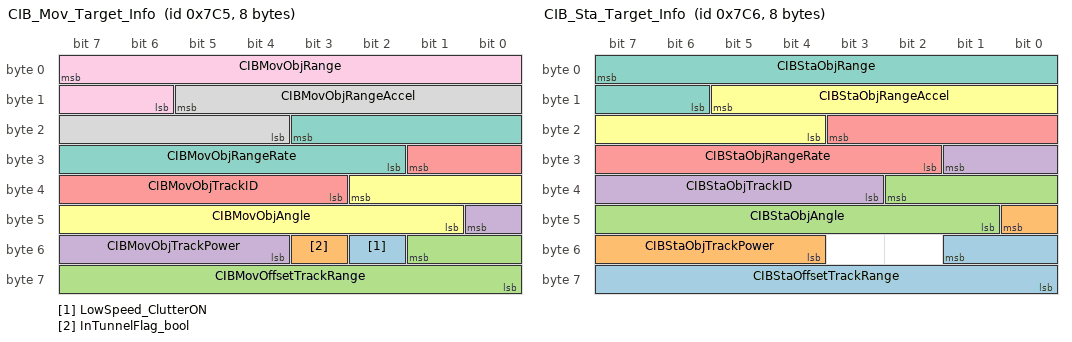
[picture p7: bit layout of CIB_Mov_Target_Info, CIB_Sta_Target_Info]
BO_ 1989 CIB_Mov_Target_Info: 8 dSPACE
 SG_ LowSpeed_ClutterON : 50|1@0+ (1,0) [0|0] "" Vector__XXX
 SG_ InTunnelFlag_bool : 51|1@0+ (1,0) [0|0] "" Vector__XXX
 SG_ CIBMovOffsetTrackRange : 49|10@0+ (0.25,0) [0|255.75] "Meters" Vector__XXX
 SG_ CIBMovObjTrackPower : 40|5@0+ (1,-10) [-10|21] "dB" Vector__XXX
 SG_ CIBMovObjTrackID : 25|7@0+ (1,0) [0|127] "Counts" Vector__XXX
 SG_ CIBMovObjAngle : 34|10@0- (0.1,0) [-51.2|51.1] "deg" Vector__XXX
 SG_ CIBMovObjRangeRate : 19|10@0- (0.125,0) [-64|63.875] "mps" Vector__XXX
 SG_ CIBMovObjRangeAccel : 13|10@0- (0.05,0) [-25.6|25.55] "m/s/s" Vector__XXX
 SG_ CIBMovObjRange : 7|10@0+ (0.25,0) [0|255.75] "Meters" Vector__XXX

BO_ 1990 CIB_Sta_Target_Info: 8 dSPACE
 SG_ CIBStaOffsetTrackRange : 49|10@0+ (0.25,0) [0|255.75] "Meters" Vector__XXX
 SG_ CIBStaObjTrackPower : 40|5@0+ (1,-10) [-10|21] "dB" Vector__XXX
 SG_ CIBStaObjAngle : 34|10@0- (0.1,0) [-51.2|51.1] "deg" Vector__XXX
 SG_ CIBStaObjTrackID : 25|7@0+ (1,0) [0|127] "Counts" Vector__XXX
 SG_ CIBStaObjRangeRate : 19|10@0- (0.125,0) [-64|63.875] "mps" Vector__XXX
 SG_ CIBStaObjRangeAccel : 13|10@0- (0.05,0) [-25.6|25.55] "m/s/s" Vector__XXX
 SG_ CIBStaObjRange : 7|10@0+ (0.25,0) [0|255.75] "Meters" Vector__XXX

BO_ 1991 FCW_Dev_Data: 4 dSPACE
 SG_ FCW_Ref_TTC : 7|16@0+ (1,0) [0|65535] "" Vector__XXX

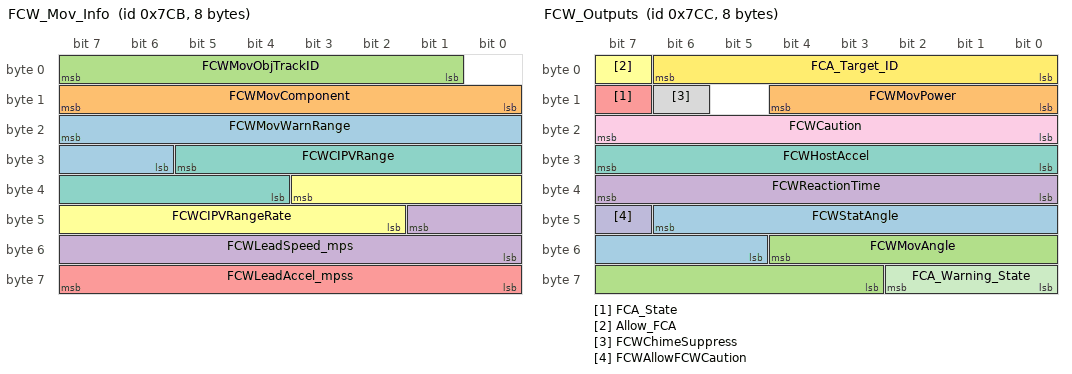
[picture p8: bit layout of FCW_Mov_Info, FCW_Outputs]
BO_ 1995 FCW_Mov_Info: 8 dSPACE
 SG_ FCWMovWarnRange : 23|10@0+ (0.25,0) [0|255.75] "Meters" Vector__XXX
 SG_ FCWMovComponent : 15|8@0+ (1,0) [0|0] "Bit Mapped" Vector__XXX
 SG_ FCWMovObjTrackID : 7|7@0+ (1,0) [0|127] "Counts" Vector__XXX
 SG_ FCWLeadSpeed_mps : 41|10@0+ (0.0625,0) [0|63.9375] "m/sec" Vector__XXX
 SG_ FCWLeadAccel_mpss : 63|8@0- (0.0625,0) [-8|7.9375] "mpss" Vector__XXX
 SG_ FCWCIPVRangeRate : 35|10@0- (0.125,0) [-64|63.875] "mps" Vector__XXX
 SG_ FCWCIPVRange : 29|10@0+ (0.25,0) [0|255.75] "Meters" Vector__XXX

BO_ 1996 FCW_Outputs: 8 dSPACE
 SG_ FCWStatAngle : 46|10@0- (0.1,0) [-51.2|51.1] "deg" Vector__XXX
 SG_ FCWMovPower : 12|5@0+ (1,-10) [-10|21] "dB" Vector__XXX
 SG_ FCWMovAngle : 52|10@0- (0.1,0) [-51.2|51.1] "deg" Vector__XXX
 SG_ FCWReactionTime : 39|8@0+ (0.0625,0) [0|10] "Sec" Vector__XXX
 SG_ FCA_State : 15|1@0+ (1,0) [0|0] "Boolean" Vector__XXX
 SG_ Allow_FCA : 7|1@0+ (1,0) [0|0] "Boolean" Vector__XXX
 SG_ FCWHostAccel : 31|8@0- (0.0625,0) [-8|7.9375] "mpss" Vector__XXX
 SG_ FCWChimeSuppress : 14|1@0+ (1,0) [0|0] "Boolean" Vector__XXX
 SG_ FCWCaution : 23|8@0+ (0.5,0) [0|100] "Percent" Vector__XXX
 SG_ FCWAllowFCWCaution : 47|1@0+ (1,0) [0|0] "Boolean" Vector__XXX
 SG_ FCA_Warning_State : 58|3@0+ (1,0) [0|0] "Enumerated" Vector__XXX
 SG_ FCA_Target_ID : 6|7@0+ (1,0) [0|127] "Counts" Vector__XXX

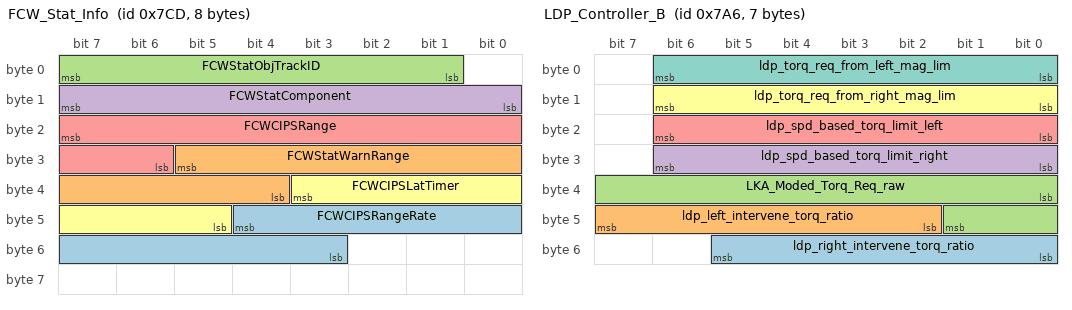
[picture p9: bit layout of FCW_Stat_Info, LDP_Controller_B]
BO_ 1997 FCW_Stat_Info: 8 dSPACE
 SG_ FCWCIPSRangeRate : 44|10@0- (0.125,0) [-64|63.875] "mps" Vector__XXX
 SG_ FCWStatWarnRange : 29|10@0+ (0.25,0) [0|255.75] "Meters" Vector__XXX
 SG_ FCWStatObjTrackID : 7|7@0+ (1,0) [0|127] "Counts" Vector__XXX
 SG_ FCWStatComponent : 15|8@0+ (1,0) [0|0] "Bit Mapped" Vector__XXX
 SG_ FCWCIPSRange : 23|10@0+ (0.25,0) [0|255.75] "Meters" Vector__XXX
 SG_ FCWCIPSLatTimer : 35|7@0+ (1,0) [0|100] "Counts" Vector__XXX

BO_ 2000 GM_Performance: 8 dSPACE
 SG_ GM_VehSpdAvgNDrvn : 6|15@0+ (0.015625,0) [0|511.984375] "km / h" Vector__XXX
 SG_ GM_Host_Speed_Filt_kph : 23|16@0+ (0.00390625,0) [0|255.99609375] "kph" Vector__XXX
 SG_ GM_Host_Jerk_g_per_sec : 55|16@0- (6.103515625E-005,0) [-2|1.9999389648] "g/sec" Vector__XXX
 SG_ GM_Host_Accel_g : 39|16@0- (6.103515625E-005,0) [-2|1.9999389648] "g" Vector__XXX

BO_ 1958 LDP_Controller_B: 7 dSPACE
 SG_ ldp_right_intervene_torq_ratio : 48|6@1+ (0.02,0) [0|1.26] "" Vector__XXX
 SG_ ldp_left_intervene_torq_ratio : 42|6@1+ (0.02,0) [0|1.26] "" Vector__XXX
 SG_ LKA_Moded_Torq_Req_raw : 32|10@1- (0.01,0) [-5.12|5.11] "Nm" Vector__XXX
 SG_ ldp_spd_based_torq_limit_right : 24|7@1- (0.05,0) [-3.2|3.15] "" Vector__XXX
 SG_ ldp_spd_based_torq_limit_left : 16|7@1- (0.05,0) [-3.2|3.15] "" Vector__XXX
 SG_ ldp_torq_req_from_right_mag_lim : 8|7@1- (0.05,0) [-3.2|3.15] "Nm" Vector__XXX
 SG_ ldp_torq_req_from_left_mag_lim : 0|7@1- (0.05,0) [-3.2|3.15] "Nm" Vector__XXX

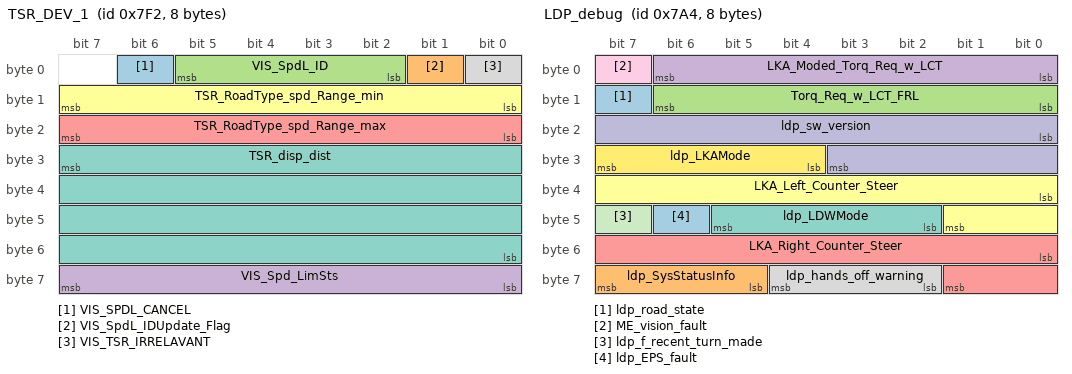
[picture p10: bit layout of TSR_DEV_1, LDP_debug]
BO_ 2034 TSR_DEV_1: 8 dSPACE
 SG_ VIS_SPDL_CANCEL : 6|1@0+ (1,0) [0|1] "boolean" Vector__XXX
 SG_ VIS_SpdL_IDUpdate_Flag : 1|1@0+ (1,0) [0|1] "boolean" Vector__XXX
 SG_ VIS_SpdL_ID : 5|4@0+ (1,0) [0|8] "" Vector__XXX
 SG_ VIS_Spd_LimSts : 63|8@0+ (1,0) [0|5] "" Vector__XXX
 SG_ TSR_RoadType_spd_Range_max : 23|8@0+ (1,0) [0|255] "km/h" Vector__XXX
 SG_ TSR_RoadType_spd_Range_min : 15|8@0+ (1,0) [0|255] "km/h" Vector__XXX
 SG_ TSR_disp_dist : 31|32@0- (0.01,0) [-5000|50000] "m" Vector__XXX
 SG_ VIS_TSR_IRRELAVANT : 0|1@0+ (1,0) [0|1] "boolean" Vector__XXX

BO_ 1957 LDP_debug_A: 5 dSPACE
 SG_ ldp_i_term_init_flags : 32|8@1+ (1,0) [0|255] "" Vector__XXX
 SG_ ldp_i_term_freeze_flags : 24|8@1+ (1,0) [0|255] "" Vector__XXX
 SG_ ldp_f_right_suppression : 18|1@1+ (1,0) [0|1] "" Vector__XXX
 SG_ ldp_f_left_suppression : 17|1@1+ (1,0) [0|1] "" Vector__XXX
 SG_ Type_Source_Boundary_Right : 4|2@1+ (1,0) [0|3] "" Vector__XXX
 SG_ Type_Source_Boundary_Left : 2|2@1+ (1,0) [0|3] "" Vector__XXX
 SG_ ldp_valid_MM_lane_Marker : 16|1@1+ (1,0) [0|1] "" Vector__XXX
 SG_ Cross_Detected : 15|1@1+ (1,0) [0|1] "" Vector__XXX
 SG_ Hill_Detected : 14|1@1+ (1,0) [0|1] "" Vector__XXX
 SG_ ldp_f_brake_pedal_inhibit : 13|1@1+ (1,0) [0|1] "" Vector__XXX
 SG_ ldp_f_accel_pedal_inhibit : 12|1@1+ (1,0) [0|1] "" Vector__XXX
 SG_ ldp_f_steer_angle_CR_inhibit : 11|1@1+ (1,0) [0|1] "" Vector__XXX
 SG_ ldp_f_left_driver_suppression : 10|1@1+ (1,0) [0|1] "" Vector__XXX
 SG_ ldp_f_hands_off_warning : 9|1@1+ (1,0) [0|1] "" Vector__XXX
 SG_ ldp_valid_MM_lane_width : 8|1@1+ (1,0) [0|1] "" Vector__XXX
 SG_ ldp_valid_MM_curvature : 7|1@1+ (1,0) [0|1] "" Vector__XXX
 SG_ ldp_MM_turn_signal : 0|2@1+ (1,0) [0|3] "" Vector__XXX
 SG_ ldp_f_right_driver_suppression : 6|1@1+ (1,0) [0|1] "" Vector__XXX

BO_ 2033 ELK_Mode_Manager: 8 Vector__XXX
 SG_ f_dist_right_mkr : 52|12@1- (0.01,0) [-20.48|20.47] "m" Vector__XXX
 SG_ f_dist_left_mkr : 28|12@1- (0.01,0) [-20.48|20.47] "" Vector__XXX
 SG_ f_dist_right_edge : 40|12@1- (0.01,0) [-20.48|20.47] "m" Vector__XXX
 SG_ f_dist_left_edge : 16|12@1- (0.01,0) [-20.48|20.47] "m" Vector__XXX
 SG_ ELK_Func_Flow_Activated_R : 14|2@1+ (1,0) [0|3] "" Vector__XXX
 SG_ ELK_Func_Flow_Activated_L : 12|2@1+ (1,0) [0|3] "" Vector__XXX
 SG_ ELK_Right_Intervene : 9|1@1+ (1,0) [0|1] "" Vector__XXX
 SG_ ELK_Left_Intervene : 8|1@1+ (1,0) [0|1] "" Vector__XXX
 SG_ ELK_Right_Lane_Change : 11|1@1+ (1,0) [0|1] "" Vector__XXX
 SG_ ELK_Left_Lane_Change : 10|1@1+ (1,0) [0|1] "" Vector__XXX
 SG_ ELK_Right_Lane_Crossed : 7|1@1+ (1,0) [0|1] "" Vector__XXX
 SG_ ELK_Left_Lane_Crossed : 6|1@1+ (1,0) [0|1] "" Vector__XXX
 SG_ ELK_Left_Suppression : 4|1@1+ (1,0) [0|1] "" Vector__XXX
 SG_ ELK_Right_Suppression : 5|1@1+ (1,0) [0|1] "" Vector__XXX
 SG_ ELK_Right_Aligned : 3|1@1+ (1,0) [0|1] "" Vector__XXX
 SG_ ELK_Left_Aligned : 2|1@1+ (1,0) [0|1] "" Vector__XXX
 SG_ ELK_Right_Override : 1|1@1+ (1,0) [0|1] "" Vector__XXX
 SG_ ELK_Left_Override : 0|1@1+ (1,0) [0|1] "" Vector__XXX

BO_ 1956 LDP_debug: 8 dSPACE
 SG_ ldp_road_state : 15|1@1+ (1,0) [0|1] "" Vector__XXX
 SG_ ldp_SysStatusInfo : 61|3@1+ (1,0) [0|7] "enum" Vector__XXX
 SG_ Torq_Req_w_LCT_FRL : 8|7@1- (0.05,0) [-3.2|3.15] "Nm" Vector__XXX
 SG_ LKA_Moded_Torq_Req_w_LCT : 0|7@1- (0.05,0) [-3.2|3.15] "Nm" Vector__XXX
 SG_ LKA_Right_Counter_Steer : 48|10@1- (0.01,0) [-5.12|5.11] "" Vector__XXX
 SG_ LKA_Left_Counter_Steer : 32|10@1- (0.01,0) [-5.12|5.11] "" Vector__XXX
 SG_ ldp_LDWMode : 42|4@1+ (1,0) [0|8] "" Vector__XXX
 SG_ ldp_hands_off_warning : 58|3@1+ (1,0) [0|7] "" Vector__XXX
 SG_ ME_vision_fault : 7|1@1- (1,0) [0|1] "" Vector__XXX
 SG_ ldp_sw_version : 16|12@1+ (0.001,0) [0|4.095] "" Vector__XXX
 SG_ ldp_f_recent_turn_made : 47|1@1+ (1,0) [0|1] "" Vector__XXX
 SG_ ldp_LKAMode : 28|4@1+ (1,0) [0|8] "" Vector__XXX
 SG_ ldp_EPS_fault : 46|1@1+ (1,0) [0|1] "" Vector__XXX

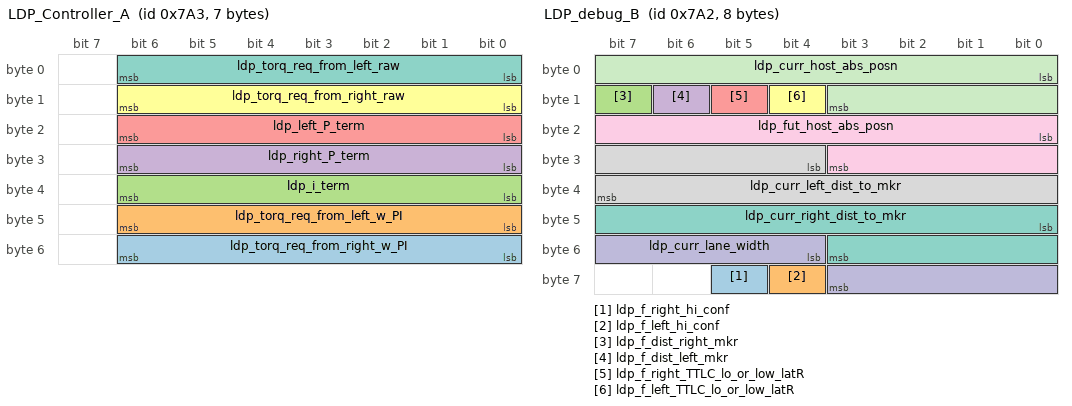
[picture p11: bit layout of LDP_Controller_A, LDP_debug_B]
BO_ 1955 LDP_Controller_A: 7 dSPACE
 SG_ ldp_torq_req_from_right_w_PI : 48|7@1- (0.05,0) [-3.2|3.15] "" Vector__XXX
 SG_ ldp_torq_req_from_left_w_PI : 40|7@1- (0.05,0) [-3.2|3.15] "" Vector__XXX
 SG_ ldp_i_term : 32|7@1- (0.05,0) [-3.2|3.15] "" Vector__XXX
 SG_ ldp_right_P_term : 24|7@1- (0.05,0) [-3.2|3.15] "" Vector__XXX
 SG_ ldp_left_P_term : 16|7@1- (0.05,0) [-3.2|3.15] "" Vector__XXX
 SG_ ldp_torq_req_from_right_raw : 8|7@1- (0.05,0) [-3.2|3.15] "Nm" Vector__XXX
 SG_ ldp_torq_req_from_left_raw : 0|7@1- (0.05,0) [-3.2|3.15] "Nm" Vector__XXX

BO_ 1954 LDP_debug_B: 8 dSPACE
 SG_ ldp_f_right_hi_conf : 61|1@1+ (1,0) [0|1] "" Vector__XXX
 SG_ ldp_f_left_hi_conf : 60|1@1+ (1,0) [0|1] "" Vector__XXX
 SG_ ldp_f_dist_right_mkr : 15|1@1+ (1,0) [0|1] "" Vector__XXX
 SG_ ldp_f_dist_left_mkr : 14|1@1+ (1,0) [0|1] "" Vector__XXX
 SG_ ldp_f_right_TTLC_lo_or_low_latR : 13|1@1+ (1,0) [0|1] "" Vector__XXX
 SG_ ldp_f_left_TTLC_lo_or_low_latR : 12|1@1+ (1,0) [0|1] "" Vector__XXX
 SG_ ldp_curr_right_dist_to_mkr : 40|12@1- (0.01,0) [-20.48|20.47] "m" Vector__XXX
 SG_ ldp_curr_left_dist_to_mkr : 28|12@1- (0.01,0) [-20.48|20.47] "m" Vector__XXX
 SG_ ldp_fut_host_abs_posn : 16|12@1- (0.01,0) [-20.48|20.47] "m" Vector__XXX
 SG_ ldp_curr_lane_width : 52|8@1+ (0.05,0) [0|12.75] "m" Vector__XXX
 SG_ ldp_curr_host_abs_posn : 0|12@1- (0.01,0) [-20.48|20.47] "m" Vector__XXX

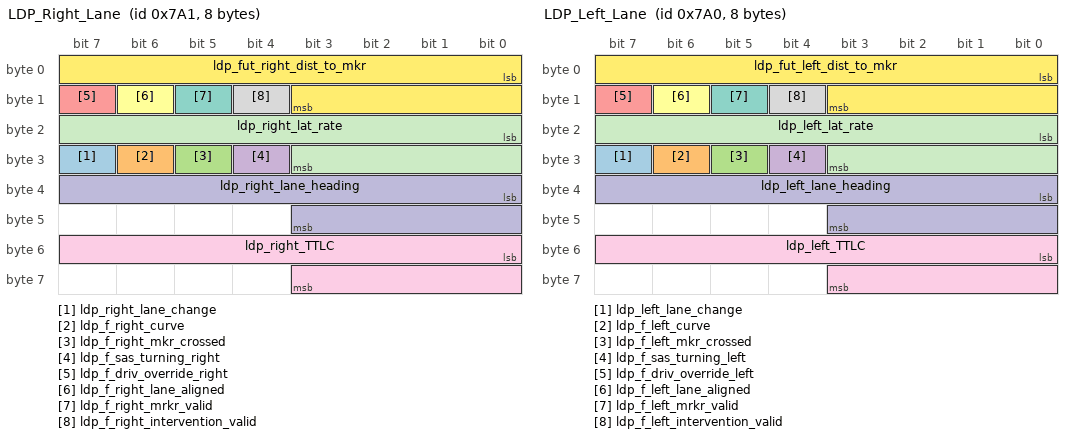
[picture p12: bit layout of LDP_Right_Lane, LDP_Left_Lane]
BO_ 1953 LDP_Right_Lane: 8 dSPACE
 SG_ ldp_right_lane_change : 31|1@1+ (1,0) [0|1] "" Vector__XXX
 SG_ ldp_f_right_curve : 30|1@1+ (1,0) [0|1] "" Vector__XXX
 SG_ ldp_f_right_mkr_crossed : 29|1@1+ (1,0) [0|1] "" Vector__XXX
 SG_ ldp_f_sas_turning_right : 28|1@1+ (1,0) [0|1] "" Vector__XXX
 SG_ ldp_f_driv_override_right : 15|1@1+ (1,0) [0|1] "" Vector__XXX
 SG_ ldp_f_right_lane_aligned : 14|1@1+ (1,0) [0|1] "" Vector__XXX
 SG_ ldp_f_right_mrkr_valid : 13|1@1+ (1,0) [0|1] "" Vector__XXX
 SG_ ldp_f_right_intervention_valid : 12|1@1+ (1,0) [0|1] "" Vector__XXX
 SG_ ldp_right_TTLC : 48|12@1- (0.005,0) [-10.24|10.235] "sec" Vector__XXX
 SG_ ldp_right_lane_heading : 32|12@1- (0.01,0) [-20.48|20.47] "deg" Vector__XXX
 SG_ ldp_right_lat_rate : 16|12@1- (0.01,0) [-20.48|20.47] "m/s" Vector__XXX
 SG_ ldp_fut_right_dist_to_mkr : 0|12@1- (0.005,0) [-10.24|10.235] "m" Vector__XXX

BO_ 1952 LDP_Left_Lane: 8 dSPACE
 SG_ ldp_left_lane_change : 31|1@1+ (1,0) [0|1] "" Vector__XXX
 SG_ ldp_f_left_curve : 30|1@1+ (1,0) [0|1] "" Vector__XXX
 SG_ ldp_f_left_mkr_crossed : 29|1@1+ (1,0) [0|1] "" Vector__XXX
 SG_ ldp_f_sas_turning_left : 28|1@1+ (1,0) [0|1] "" Vector__XXX
 SG_ ldp_f_driv_override_left : 15|1@1+ (1,0) [0|1] "" Vector__XXX
 SG_ ldp_f_left_lane_aligned : 14|1@1+ (1,0) [0|1] "" Vector__XXX
 SG_ ldp_f_left_mrkr_valid : 13|1@1+ (1,0) [0|1] "" Vector__XXX
 SG_ ldp_f_left_intervention_valid : 12|1@1+ (1,0) [0|1] "" Vector__XXX
 SG_ ldp_left_TTLC : 48|12@1- (0.005,0) [-10.24|10.235] "sec" Vector__XXX
 SG_ ldp_left_lane_heading : 32|12@1- (0.01,0) [-20.48|20.47] "deg" Vector__XXX
 SG_ ldp_left_lat_rate : 16|12@1- (0.01,0) [-20.48|20.47] "m/s" Vector__XXX
 SG_ ldp_fut_left_dist_to_mkr : 0|12@1- (0.005,0) [-10.24|10.235] "m" Vector__XXX

BO_ 1998 IBA: 8 dSPACE
 SG_ IBA_NeededAccel : 55|8@0- (0.0625,-2) [-10|5.9375] "" Vector__XXX
 SG_ IBA_MinDecelRequest : 15|8@0- (0.0625,-2) [-10|5.9375] "mpss" Vector__XXX
 SG_ IBA_BrakeRateUnfilt : 39|16@0+ (1,0) [0|65535] "" Vector__XXX
 SG_ IBA_BrakePedalActive : 6|1@0+ (1,0) [0|0] "Boolean" Vector__XXX
 SG_ IBA_BrakePressUnfilt : 23|16@0+ (1,0) [0|65535] "" Vector__XXX
 SG_ IBA_BrakePressActive : 7|1@0+ (1,0) [0|0] "Boolean" Vector__XXX

BO_ 1962 LKA_Inhibits_5_4: 8 dSPACE
 SG_ LKA_Inhibit_5_Flags : 7|32@0+ (1,0) [0|0] "Bit Mapped" Vector__XXX
 SG_ LKA_Inhibit_4_Flags : 39|32@0+ (1,0) [0|0] "Bit Mapped" Vector__XXX

BO_ 1961 LKA_Inhibits_3_2: 8 dSPACE
 SG_ LKA_Inhibit_2_Flags : 39|32@0+ (1,0) [0|0] "Bit Mapped" Vector__XXX
 SG_ LKA_Inhibit_3_Flags : 7|32@0+ (1,0) [0|0] "Bit Mapped" Vector__XXX

BO_ 1960 LKA_Inhibits_1_0: 8 dSPACE
 SG_ LKA_Inhibit_1_Flags : 7|32@0+ (1,0) [0|0] "Bit Mapped" Vector__XXX
 SG_ LKA_Inhibit_0_Flags : 39|32@0+ (1,0) [0|0] "Bit Mapped" Vector__XXX

BO_ 1966 LDW_Inhibits_5_4: 8 dSPACE
 SG_ LDW_Inhibit_5_Flags : 7|32@0+ (1,0) [0|0] "Bit Mapped" Vector__XXX
 SG_ LDW_Inhibit_4_Flags : 39|32@0+ (1,0) [0|0] "Bit Mapped" Vector__XXX

BO_ 1965 LDW_Inhibits_3_2: 8 dSPACE
 SG_ LDW_Inhibit_2_Flags : 39|32@0+ (1,0) [0|0] "Bit Mapped" Vector__XXX
 SG_ LDW_Inhibit_3_Flags : 7|32@0+ (1,0) [0|0] "Bit Mapped" Vector__XXX

BO_ 1964 LDW_Inhibits_1_0: 8 dSPACE
 SG_ LDW_Inhibit_1_Flags : 7|32@0+ (1,0) [0|0] "Bit Mapped" Vector__XXX
 SG_ LDW_Inhibit_0_Flags : 39|32@0+ (1,0) [0|0] "Bit Mapped" Vector__XXX

BO_ 2003 LCA_Inhibits_5_4: 8 dSPACE
 SG_ LCA_Inhibit_5_Flags : 7|32@0+ (1,0) [0|0] "Bit Mapped" Vector__XXX
 SG_ LCA_Inhibit_4_Flags : 39|32@0+ (1,0) [0|0] "Bit Mapped" Vector__XXX

BO_ 2002 LCA_Inhibits_3_2: 8 dSPACE
 SG_ LCA_Inhibit_2_Flags : 39|32@0+ (1,0) [0|0] "Bit Mapped" Vector__XXX
 SG_ LCA_Inhibit_3_Flags : 7|32@0+ (1,0) [0|0] "Bit Mapped" Vector__XXX

BO_ 2001 LCA_Inhibits_1_0: 8 dSPACE
 SG_ LCA_Inhibit_1_Flags : 7|32@0+ (1,0) [0|0] "Bit Mapped" Vector__XXX
 SG_ LCA_Inhibit_0_Flags : 39|32@0+ (1,0) [0|0] "Bit Mapped" Vector__XXX

BO_ 2018 FDI_Inhibits_5_4: 8 dSPACE
 SG_ FDI_Inhibit_5_Flags : 7|32@0+ (1,0) [0|0] "Bit Mapped" Vector__XXX
 SG_ FDI_Inhibit_4_Flags : 39|32@0+ (1,0) [0|0] "Bit Mapped" Vector__XXX

BO_ 2017 FDI_Inhibits_3_2: 8 dSPACE
 SG_ FDI_Inhibit_2_Flags : 39|32@0+ (1,0) [0|0] "Bit Mapped" Vector__XXX
 SG_ FDI_Inhibit_3_Flags : 7|32@0+ (1,0) [0|0] "Bit Mapped" Vector__XXX

BO_ 2016 FDI_Inhibits_1_0: 8 dSPACE
 SG_ FDI_Inhibit_1_Flags : 7|32@0+ (1,0) [0|0] "Bit Mapped" Vector__XXX
 SG_ FDI_Inhibit_0_Flags : 39|32@0+ (1,0) [0|0] "Bit Mapped" Vector__XXX

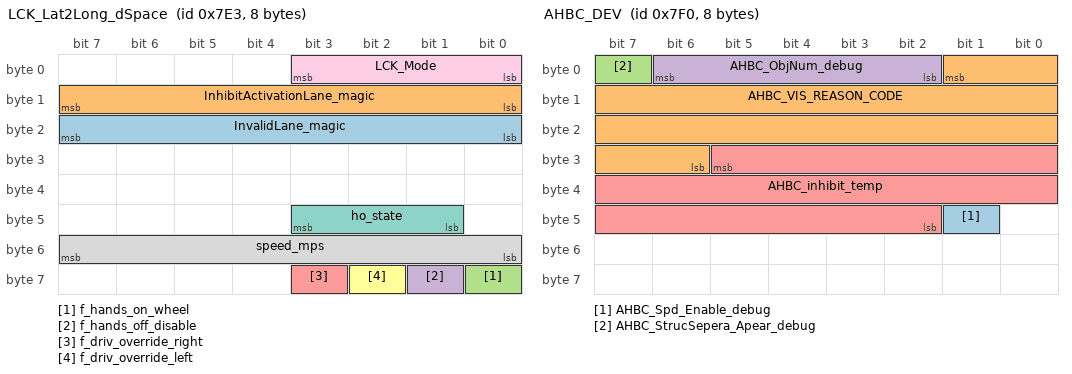
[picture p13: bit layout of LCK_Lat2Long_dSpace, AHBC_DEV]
BO_ 2019 LCK_Lat2Long_dSpace: 8 Vector__XXX
 SG_ InvalidLane_magic : 23|8@0+ (1,0) [0|0] "" Vector__XXX
 SG_ InhibitActivationLane_magic : 15|8@0+ (1,0) [0|0] "" Vector__XXX
 SG_ f_hands_on_wheel : 56|1@1+ (1,0) [0|0] "" Vector__XXX
 SG_ f_hands_off_disable : 57|1@1+ (1,0) [0|0] "" Vector__XXX
 SG_ f_driv_override_right : 59|1@1+ (1,0) [0|0] "" Vector__XXX
 SG_ f_driv_override_left : 58|1@1+ (1,0) [0|0] "" Vector__XXX
 SG_ ho_state : 43|3@0+ (1,0) [0|7] "" Vector__XXX
 SG_ speed_mps : 55|8@0+ (0.2,0) [0|51] "m/s" Vector__XXX
 SG_ LCK_Mode : 3|4@0+ (1,0) [0|0] "" Vector__XXX

BO_ 2020 LCK_ModeTransition: 8 Vector__XXX
 SG_ ACTIVE2READY_Magic_Out : 55|16@0+ (1,0) [0|0] "" Vector__XXX
 SG_ READY2ACTIVE_Magic_Out : 39|16@0+ (1,0) [0|0] "" Vector__XXX
 SG_ READY2IDLE_Magic_Out : 23|16@0+ (1,0) [0|0] "" Vector__XXX
 SG_ IDLE2READY_Magic_Out : 7|16@0+ (1,0) [0|0] "" Vector__XXX

BO_ 2021 LQR_Final_Terms_Angle: 8 Vector__XXX
 SG_ LQR_angle_integral : 48|14@1- (0.0001,0) [-0.8192|0.8191] "rad" Vector__XXX
 SG_ LQR_angle_cur_plus_ff : 32|14@1- (0.0001,0) [-0.8192|0.8191] "rad" Vector__XXX
 SG_ LQR_angle_feedforward : 16|14@1- (0.0001,0) [-0.8192|0.8191] "rad" Vector__XXX
 SG_ LQR_angle_current : 0|14@1- (0.0001,0) [-0.8192|0.8191] "rad" Vector__XXX

BO_ 2022 LQR_Final_Terms_Torque: 8 Vector__XXX
 SG_ LQR_torque_robust : 32|15@1- (0.001,0) [-16.384|16.383] "Nm" Vector__XXX
 SG_ LQR_torque_PID : 48|15@1- (0.001,0) [-16.384|16.383] "Nm" Vector__XXX
 SG_ LQR_torque_integral : 16|15@1- (0.001,0) [-16.384|16.383] "Nm" Vector__XXX
 SG_ LQR_torque_cur_plus_ff : 0|15@1- (0.001,0) [-16.384|16.383] "Nm" Vector__XXX

BO_ 2032 AHBC_DEV: 8 dSPACE
 SG_ AHBC_Spd_Enable_debug : 41|1@0+ (1,0) [0|1] "" Vector__XXX
 SG_ AHBC_VIS_REASON_CODE : 1|20@0+ (1,0) [0|1048575] "Bit Mapped" Vector__XXX
 SG_ AHBC_StrucSepera_Apear_debug : 7|1@0+ (1,0) [0|1] "" Vector__XXX
 SG_ AHBC_ObjNum_debug : 6|5@0+ (1,0) [0|20] "" Vector__XXX
 SG_ AHBC_inhibit_temp : 29|20@0+ (1,0) [0|1048575] "Bit Mapped" Vector__XXX

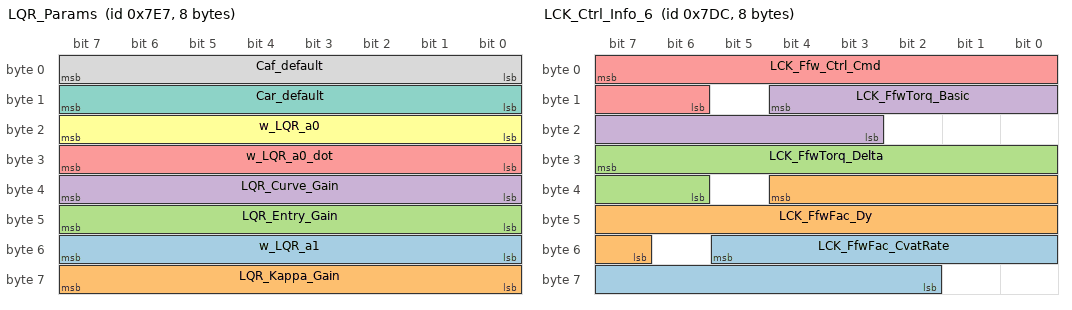
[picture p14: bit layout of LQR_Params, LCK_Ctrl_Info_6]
BO_ 2023 LQR_Params: 8 Vector__XXX
 SG_ w_LQR_a1 : 55|8@0+ (0.1,0) [0|0] "" Vector__XXX
 SG_ LQR_Kappa_Gain : 63|8@0+ (0.1,0) [0|0] "" Vector__XXX
 SG_ LQR_Entry_Gain : 47|8@0+ (0.1,0) [0|0] "" Vector__XXX
 SG_ LQR_Curve_Gain : 39|8@0+ (0.1,0) [0|0] "" Vector__XXX
 SG_ w_LQR_a0_dot : 31|8@0- (0.1,0) [0|0] "" Vector__XXX
 SG_ w_LQR_a0 : 23|8@0+ (0.1,0) [0|0] "" Vector__XXX
 SG_ Car_default : 15|8@0+ (5000,0) [0|0] "" Vector__XXX
 SG_ Caf_default : 7|8@0+ (5000,0) [0|0] "" Vector__XXX

BO_ 2014 LCK_Ctrl_Info_8: 8 Vector__XXX
 SG_ LCK_LatCtrl_I_Term_Cur : 55|10@0- (0.01,0) [-5.12|5.11] "" Vector__XXX
 SG_ LCK_LatCtrl_I_Term_Prvd : 39|10@0- (0.01,0) [-5.12|5.11] "" Vector__XXX
 SG_ LCK_LatCtrl_P_Term_Cur : 23|10@0- (0.01,0) [-5.12|5.11] "" Vector__XXX
 SG_ LCK_LatCtrl_P_Term_Prvd : 7|10@0- (0.01,0) [-5.12|5.11] "" Vector__XXX

BO_ 2012 LCK_Ctrl_Info_6: 8 Vector__XXX
 SG_ LCK_FfwFac_CvatRate : 53|12@0+ (0.001,0) [0|4.095] "" Vector__XXX
 SG_ LCK_FfwFac_Dy : 36|14@0+ (0.0001,0) [0|1.6383] "" Vector__XXX
 SG_ LCK_FfwTorq_Delta : 31|10@0- (0.01,0) [-5.12|5.11] "" Vector__XXX
 SG_ LCK_FfwTorq_Basic : 12|10@0- (0.01,0) [-5.12|5.11] "" Vector__XXX
 SG_ LCK_Ffw_Ctrl_Cmd : 7|10@0- (0.01,0) [-5.12|5.11] "" Vector__XXX

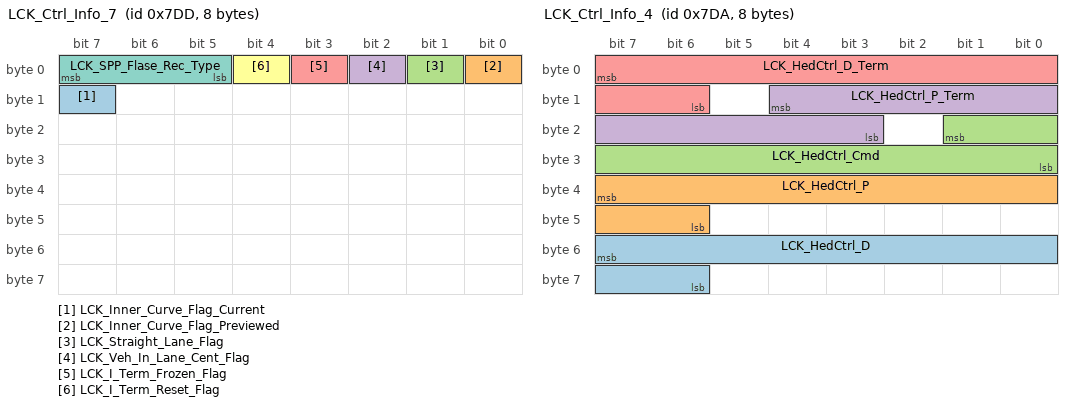
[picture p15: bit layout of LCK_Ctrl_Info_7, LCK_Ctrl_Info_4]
BO_ 2013 LCK_Ctrl_Info_7: 8 Vector__XXX
 SG_ LCK_Inner_Curve_Flag_Current : 15|1@0+ (1,0) [0|1] "" Vector__XXX
 SG_ LCK_Inner_Curve_Flag_Previewed : 0|1@0+ (1,0) [0|1] "" Vector__XXX
 SG_ LCK_Straight_Lane_Flag : 1|1@0+ (1,0) [0|1] "" Vector__XXX
 SG_ LCK_Veh_In_Lane_Cent_Flag : 2|1@0+ (1,0) [0|1] "" Vector__XXX
 SG_ LCK_I_Term_Frozen_Flag : 3|1@0+ (1,0) [0|1] "" Vector__XXX
 SG_ LCK_I_Term_Reset_Flag : 4|1@0+ (1,0) [0|1] "" Vector__XXX
 SG_ LCK_SPP_Flase_Rec_Type : 7|3@0+ (1,0) [0|7] "" Vector__XXX

BO_ 2011 LCK_Ctrl_Info_5: 8 Vector__XXX
 SG_ LCK_FinalTorqCmd : 55|10@0- (0.01,0) [-5.12|5.11] "" Vector__XXX
 SG_ LCK_PIDTorqCmd_Percent : 39|16@0- (0.01,0) [-327.68|327.67] "" Vector__XXX
 SG_ LCK_PID_TorqCmd : 23|10@0- (0.01,0) [-5.12|5.11] "" Vector__XXX
 SG_ LCK_PIDPlusFfw_TorqCmd : 7|10@0- (0.01,0) [-5.12|5.11] "" Vector__XXX

BO_ 2010 LCK_Ctrl_Info_4: 8 Vector__XXX
 SG_ LCK_HedCtrl_D : 55|10@0+ (0.01,0) [0|10.23] "" Vector__XXX
 SG_ LCK_HedCtrl_P : 39|10@0+ (0.01,0) [0|10.23] "" Vector__XXX
 SG_ LCK_HedCtrl_Cmd : 17|10@0- (0.01,0) [-5.12|5.11] "" Vector__XXX
 SG_ LCK_HedCtrl_P_Term : 12|10@0- (0.01,0) [-5.12|5.11] "" Vector__XXX
 SG_ LCK_HedCtrl_D_Term : 7|10@0- (0.01,0) [-5.12|5.11] "" Vector__XXX

BO_ 2009 LCK_Ctrl_Info_3: 8 Vector__XXX
 SG_ LCK_LatCtrl_D : 39|14@0+ (0.001,0) [0|16.383] "" Vector__XXX
 SG_ LCK_LatCtrl_I : 23|14@0+ (0.001,0) [0|16.383] "" Vector__XXX
 SG_ LCK_LatCtrl_P : 7|14@0+ (0.001,0) [0|16.383] "" Vector__XXX

BO_ 2006 LCK_Ctrl_Info_2: 8 Vector__XXX
 SG_ LCK_LatCtrl_Cmd : 23|10@0- (0.01,0) [-5.12|5.11] "" Vector__XXX
 SG_ LCK_LatCtrl_D_Term : 55|10@0- (0.01,0) [-5.12|5.11] "" Vector__XXX
 SG_ LCK_LatCtrl_I_Term : 39|10@0- (0.01,0) [-5.12|5.11] "" Vector__XXX
 SG_ LCK_LatCtrl_P_Term : 7|10@0- (0.01,0) [-5.12|5.11] "" Vector__XXX

BO_ 2005 LCK_Ctrl_Info_1: 8 Vector__XXX
 SG_ LCK_CurvatureRate : 39|14@0- (1E-006,0) [-0.008192|0.008191] "" Vector__XXX
 SG_ LCK_RoadRadius : 55|16@0- (1,0) [-32768|32767] "" Vector__XXX
 SG_ LCK_FutCurv : 23|14@0- (1E-005,0) [-0.08192|0.08191] "" Vector__XXX
 SG_ LCK_CurCurv : 7|14@0- (1E-005,0) [-0.08192|0.08191] "" Vector__XXX

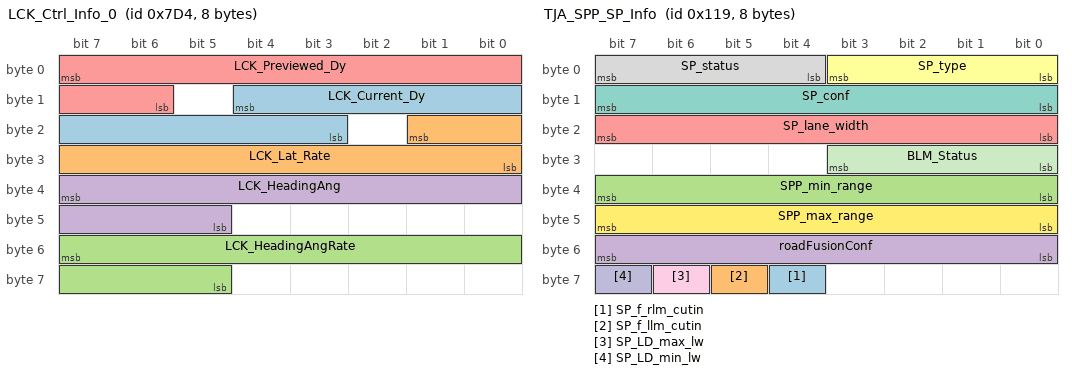
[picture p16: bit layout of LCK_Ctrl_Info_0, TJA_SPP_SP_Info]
BO_ 2004 LCK_Ctrl_Info_0: 8 Vector__XXX
 SG_ LCK_Current_Dy : 12|10@0- (0.01,0) [-5.12|5.11] "" Vector__XXX
 SG_ LCK_Lat_Rate : 17|10@0- (0.01,0) [-5.12|5.11] "" Vector__XXX
 SG_ LCK_HeadingAngRate : 55|11@0- (0.01,0) [-10.24|10.23] "" Vector__XXX
 SG_ LCK_HeadingAng : 39|11@0- (0.01,0) [-10.24|10.23] "" Vector__XXX
 SG_ LCK_Previewed_Dy : 7|10@0- (0.01,0) [-5.12|5.11] "" Vector__XXX

BO_ 281 TJA_SPP_SP_Info: 8 IFV_CWMP
 SG_ SP_f_rlm_cutin : 60|1@1+ (1,0) [0|0] "" Vector__XXX
 SG_ SP_f_llm_cutin : 61|1@1+ (1,0) [0|0] "" Vector__XXX
 SG_ SPP_min_range : 32|8@1+ (0.5,0) [0|127.5] "" Vector__XXX
 SG_ roadFusionConf : 48|8@1+ (0.01,0) [0|1] ""  External
 SG_ SP_lane_width : 16|8@1+ (0.05,0) [0|12.75] "meters"  External
 SG_ SP_type : 0|4@1+ (1,0) [0|15] "SED"  External
 SG_ SP_conf : 8|8@1+ (1,0) [0|4] "SED"  External
 SG_ SP_status : 4|4@1+ (1,0) [0|15] "SED"  External
 SG_ SP_LD_max_lw : 62|1@1+ (1,0) [0|1] ""  External
 SG_ SP_LD_min_lw : 63|1@1+ (1,0) [0|1] ""  External
 SG_ BLM_Status : 24|4@1+ (1,0) [0|15] "SED"  External
 SG_ SPP_max_range : 40|8@1+ (0.5,0) [0|127.5] "SED"  External

BO_ 289 TJA_SPP_SP_Poly_Coeff: 8 IFV_CWMP
 SG_ SPP_POLY_COEFF_A3 : 48|16@1+ (3.7252902985E-009,-0.00012206658721) [-0.00012|0.00012] "1/m^2"  External
 SG_ SPP_POLY_COEFF_A2 : 32|16@1+ (9.765625E-007,-0.031999023438) [-0.02|0.02] "1/m"  External
 SG_ SPP_POLY_COEFF_A1 : 16|16@1+ (0.0009765625,-31.999023438) [-31.999023438|31.999023438] "radians"  External
 SG_ SPP_POLY_COEFF_A0 : 0|16@1+ (0.00390625,-128) [-128|127] "m"  External

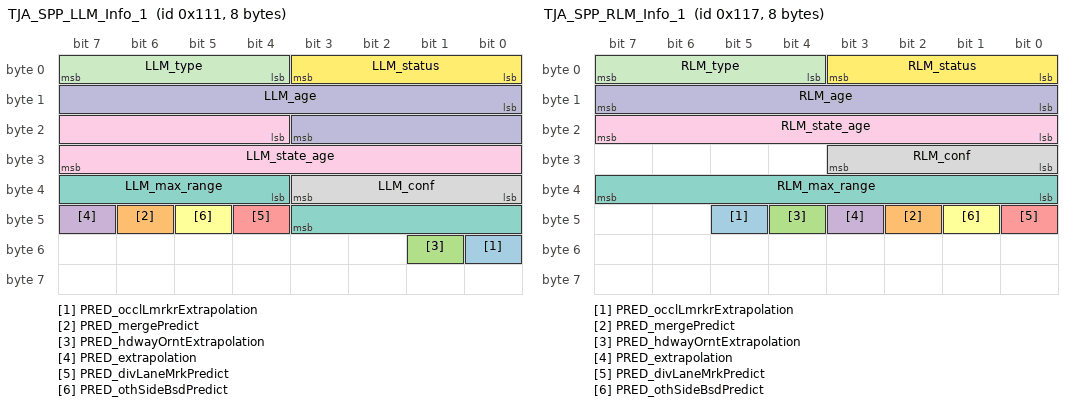
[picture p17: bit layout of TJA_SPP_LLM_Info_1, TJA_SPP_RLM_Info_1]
BO_ 273 TJA_SPP_LLM_Info_1: 8 IFV_CWMP
 SG_ PRED_occlLmrkrExtrapolation : 48|1@1+ (1,0) [0|1] "" Vector__XXX
 SG_ PRED_mergePredict : 46|1@1+ (1,0) [0|1] "" Vector__XXX
 SG_ PRED_hdwayOrntExtrapolation : 49|1@1+ (1,0) [0|1] "" Vector__XXX
 SG_ PRED_extrapolation : 47|1@1+ (1,0) [0|1] "" Vector__XXX
 SG_ PRED_divLaneMrkPredict : 44|1@1+ (1,0) [0|1] "" Vector__XXX
 SG_ PRED_othSideBsdPredict : 45|1@1+ (1,0) [0|1] "" Vector__XXX
 SG_ LLM_max_range : 36|8@1+ (0.5,0) [0|127.5] "m" Vector__XXX
 SG_ LLM_conf : 32|4@1+ (1,0) [0|15] "" Vector__XXX
 SG_ LLM_state_age : 20|12@1+ (1,0) [0|4095] "" Vector__XXX
 SG_ LLM_age : 8|12@1+ (1,0) [0|4095] "" Vector__XXX
 SG_ LLM_type : 4|4@1+ (1,0) [0|15] "" Vector__XXX
 SG_ LLM_status : 0|4@1+ (1,0) [0|15] "" Vector__XXX

BO_ 274 TJA_SPP_LLM_Poly_Coeff: 8 IFV_CWMP
 SG_ LLM_A3 : 48|16@1+ (3.7252902985E-009,-0.00012206658721) [-0.00012|0.00012] "1/m^2"  External
 SG_ LLM_A2 : 32|16@1+ (9.765625E-007,-0.031999023438) [-0.02|0.02] "1/m"  External
 SG_ LLM_A1 : 16|16@1+ (0.0009765625,-31.999023438) [-31.999023438|31.999023438] "radians"  External
 SG_ LLM_A0 : 0|16@1+ (0.00390625,-128) [-128|127] "m"  External

BO_ 279 TJA_SPP_RLM_Info_1: 8 IFV_CWMP
 SG_ PRED_occlLmrkrExtrapolation : 45|1@1+ (1,0) [0|1] "" Vector__XXX
 SG_ PRED_mergePredict : 42|1@1+ (1,0) [0|1] "" Vector__XXX
 SG_ PRED_hdwayOrntExtrapolation : 44|1@1+ (1,0) [0|1] "" Vector__XXX
 SG_ PRED_extrapolation : 43|1@1+ (1,0) [0|1] "" Vector__XXX
 SG_ PRED_divLaneMrkPredict : 40|1@1+ (1,0) [0|1] "" Vector__XXX
 SG_ PRED_othSideBsdPredict : 41|1@1+ (1,0) [0|1] "" Vector__XXX
 SG_ RLM_max_range : 32|8@1+ (0.5,0) [0|127.5] "m" Vector__XXX
 SG_ RLM_conf : 24|4@1+ (1,0) [0|15] "" Vector__XXX
 SG_ RLM_state_age : 16|8@1+ (1,-128) [-128|127] "" Vector__XXX
 SG_ RLM_age : 8|8@1+ (1,-128) [-128|127] "" Vector__XXX
 SG_ RLM_type : 4|4@1+ (1,0) [0|15] "" Vector__XXX
 SG_ RLM_status : 0|4@1+ (1,0) [0|15] "" Vector__XXX

BO_ 280 TJA_SPP_RLM_Poly_Coeff: 8 IFV_CWMP
 SG_ RLM_A3 : 48|16@1+ (3.7252902985E-009,-0.00012206658721) [-0.00012|0.00012] "1/m^2"  External
 SG_ RLM_A2 : 32|16@1+ (9.765625E-007,-0.031999023438) [-0.02|0.02] "1/m"  External
 SG_ RLM_A1 : 16|16@1+ (0.0009765625,-31.999023438) [-31.999023438|31.999023438] "radians"  External
 SG_ RLM_A0 : 0|16@1+ (0.00390625,-128) [-128|127] "m"  External

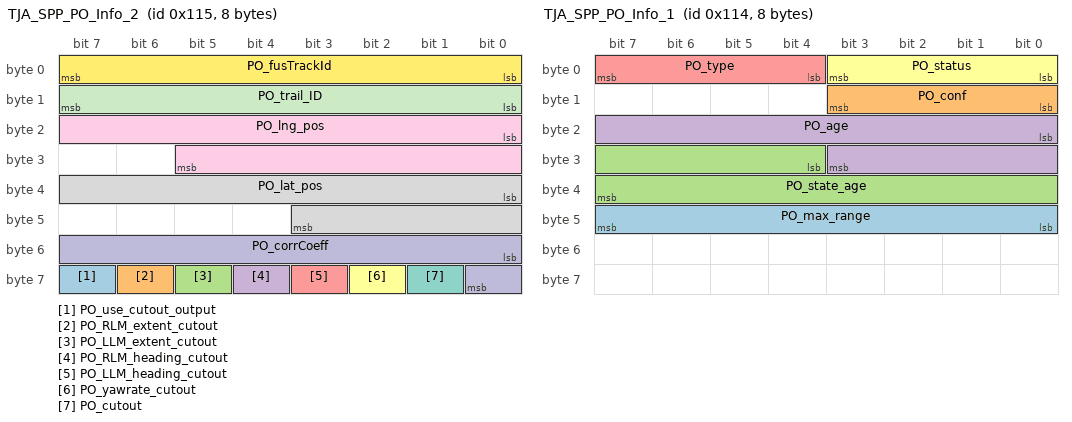
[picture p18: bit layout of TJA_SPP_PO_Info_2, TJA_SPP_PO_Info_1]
BO_ 277 TJA_SPP_PO_Info_2: 8 IFV_CWMP
 SG_ PO_use_cutout_output : 63|1@1+ (1,0) [0|1] "bool" Vector__XXX
 SG_ PO_RLM_extent_cutout : 62|1@1+ (1,0) [0|1] "bool" Vector__XXX
 SG_ PO_LLM_extent_cutout : 61|1@1+ (1,0) [0|1] "bool" Vector__XXX
 SG_ PO_RLM_heading_cutout : 60|1@1+ (1,0) [0|1] "bool" Vector__XXX
 SG_ PO_LLM_heading_cutout : 59|1@1+ (1,0) [0|1] "bool" Vector__XXX
 SG_ PO_yawrate_cutout : 58|1@1+ (1,0) [0|1] "bool" Vector__XXX
 SG_ PO_cutout : 57|1@1+ (1,0) [0|1] "bool" Vector__XXX
 SG_ PO_lat_pos : 32|12@1+ (0.01,-20.48) [-20.48|20.47] "m" Vector__XXX
 SG_ PO_lng_pos : 16|14@1+ (0.01,0) [0|163.83] "m" Vector__XXX
 SG_ PO_corrCoeff : 48|9@1+ (0.00390625,-1) [-1|0.99609375] "" Vector__XXX
 SG_ PO_trail_ID : 8|8@1+ (1,0) [0|255] "" Vector__XXX
 SG_ PO_fusTrackId : 0|8@1+ (1,0) [0|255] "" Vector__XXX

BO_ 276 TJA_SPP_PO_Info_1: 8 IFV_CWMP
 SG_ PO_max_range : 40|8@1+ (0.5,0) [0|127.5] "m" Vector__XXX
 SG_ PO_conf : 8|4@1+ (1,0) [0|15] "" Vector__XXX
 SG_ PO_state_age : 28|12@1+ (1,0) [0|4095] "" Vector__XXX
 SG_ PO_age : 16|12@1+ (1,0) [0|4095] "" Vector__XXX
 SG_ PO_type : 4|4@1+ (1,0) [0|15] "" Vector__XXX
 SG_ PO_status : 0|4@1+ (1,0) [0|15] "" Vector__XXX

BO_ 278 TJA_SPP_PO_Poly_Coeff: 8 IFV_CWMP
 SG_ PO_A3 : 48|16@1+ (3.7252902985E-009,-0.00012206658721) [-0.00012|0.00012] "1/m^2" Vector__XXX
 SG_ PO_A2 : 32|16@1+ (9.765625E-007,-0.031999023438) [-0.02|0.02] "1/m" Vector__XXX
 SG_ PO_A1 : 16|16@1+ (0.0009765625,-31.999023438) [-31.999023438|31.999023438] "radians" Vector__XXX
 SG_ PO_A0 : 0|16@1+ (0.00390625,-128) [-128|127] "m" Vector__XXX

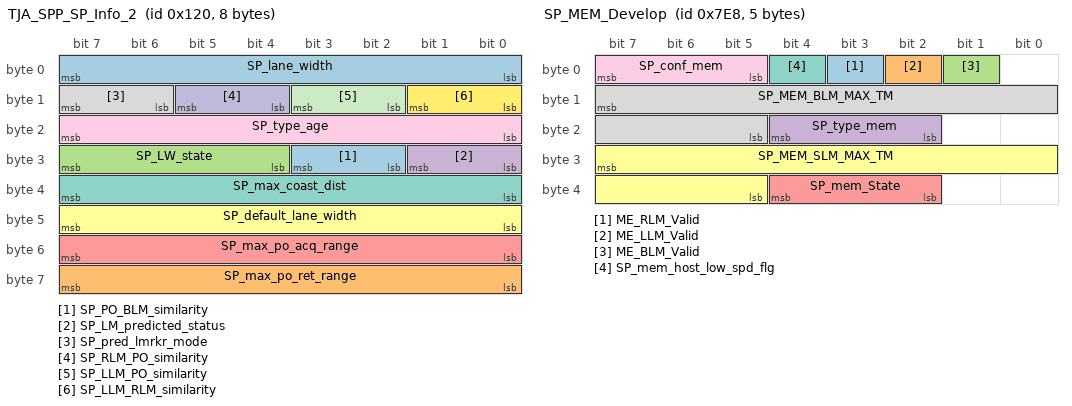
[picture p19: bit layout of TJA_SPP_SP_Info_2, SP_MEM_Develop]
BO_ 288 TJA_SPP_SP_Info_2: 8 IFV_CWMP
 SG_ SP_PO_BLM_similarity : 26|2@1+ (1,0) [0|3] "" Vector__XXX
 SG_ SP_max_po_ret_range : 56|8@1+ (1,0) [0|255] "m" Vector__XXX
 SG_ SP_LW_state : 28|4@1+ (1,0) [0|15] "" Vector__XXX
 SG_ SP_LM_predicted_status : 24|2@1+ (1,0) [0|3] "" Vector__XXX
 SG_ SP_max_po_acq_range : 48|8@1+ (1,0) [0|255] "m" Vector__XXX
 SG_ SP_default_lane_width : 40|8@1+ (0.05,0) [0|12.75] "m" Vector__XXX
 SG_ SP_max_coast_dist : 32|8@1+ (0.5,0) [0|127.5] "m" Vector__XXX
 SG_ SP_pred_lmrkr_mode : 14|2@1+ (1,0) [0|3] "" Vector__XXX
 SG_ SP_type_age : 16|8@1+ (1,0) [0|255] "" Vector__XXX
 SG_ SP_RLM_PO_similarity : 12|2@1+ (1,0) [0|3] "" Vector__XXX
 SG_ SP_LLM_PO_similarity : 10|2@1+ (1,0) [0|3] "" Vector__XXX
 SG_ SP_LLM_RLM_similarity : 8|2@1+ (1,0) [0|3] "" Vector__XXX
 SG_ SP_lane_width : 0|8@1+ (0.05,0) [0|12.75] "m" Vector__XXX

BO_ 290 TJA_SPP_VisPlaus: 8 IFV_CWMP
 SG_ VP_rlm_input_sim_v : 61|1@1+ (1,0) [0|1] "" Vector__XXX
 SG_ VP_po_input_sim_v : 63|1@1+ (1,0) [0|1] "" Vector__XXX
 SG_ VP_llm_input_sim_v : 60|1@1+ (1,0) [0|1] "" Vector__XXX
 SG_ VP_blm_input_sim_v : 62|1@1+ (1,0) [0|1] "" Vector__XXX
 SG_ VP_MPC_v : 10|1@1+ (1,0) [0|1] "" Vector__XXX
 SG_ VP_rlm_rhwl_offset : 48|10@1- (0.01,0) [-5.12|5.11] "m" Vector__XXX
 SG_ VP_llm_lwhl_offset : 32|10@1- (0.01,0) [-5.12|5.11] "m" Vector__XXX
 SG_ VP_rlm_valid : 3|1@1+ (1,0) [0|1] "" Vector__XXX
 SG_ VP_rlm_straddle : 5|1@1+ (1,0) [0|1] "" Vector__XXX
 SG_ VP_rlm_delta_valid : 4|1@1+ (1,0) [0|1] "" Vector__XXX
 SG_ VP_pred_lw_valid : 6|1@1+ (1,0) [0|1] "" Vector__XXX
 SG_ VP_pred_lw : 16|16@1+ (0.1,0) [0|25.5] "m" Vector__XXX
 SG_ VP_overall_lmrkr_valid : 7|1@1+ (1,0) [0|1] "" Vector__XXX
 SG_ VP_llm_valid : 0|1@1+ (1,0) [0|1] "" Vector__XXX
 SG_ VP_llm_straddle : 2|1@1+ (1,0) [0|1] "" Vector__XXX
 SG_ VP_llm_delta_valid : 1|1@1+ (1,0) [0|1] "" Vector__XXX
 SG_ VP_diverging : 8|2@1+ (1,0) [0|3] "" Vector__XXX

BO_ 275 TJA_SPP_LW_Info_1: 8 IFV_CWMP
 SG_ LW_rightVRE_rlm_sim : 62|2@1+ (1,0) [0|3] "na" Vector__XXX
 SG_ LW_leftVRE_llm_sim : 60|2@1+ (1,0) [0|3] "na" Vector__XXX
 SG_ LW_rightGR_VRE_sim : 58|2@1+ (1,0) [0|3] "na" Vector__XXX
 SG_ LW_leftGR_VRE_sim : 56|2@1+ (1,0) [0|3] "na" Vector__XXX
 SG_ LW_rightVRE_plaus : 51|1@1+ (1,0) [0|1] "na" Vector__XXX
 SG_ LW_rightGR_spp_sim : 54|2@1+ (1,0) [0|3] "na" Vector__XXX
 SG_ LW_leftVRE_plaus : 50|1@1+ (1,0) [0|1] "na" Vector__XXX
 SG_ LW_leftGR_spp_sim : 52|2@1+ (1,0) [0|3] "na" Vector__XXX
 SG_ LW_rightGR_plaus : 49|1@1+ (1,0) [0|1] "na" Vector__XXX
 SG_ LW_leftGR_plaus : 48|1@1+ (1,0) [0|1] "na" Vector__XXX
 SG_ LW_right_bound_type : 44|4@1+ (1,0) [0|15] "" Vector__XXX
 SG_ LW_left_bound_type : 40|4@1+ (1,0) [0|15] "" Vector__XXX
 SG_ LW_coast_dist_v_meas_lw : 32|8@1+ (0.25,0) [0|63.75] "m" Vector__XXX
 SG_ LW_slope_to_preset : 24|8@1+ (5,0) [0|1275] "cm/m" Vector__XXX
 SG_ LW_slope_to_meas : 16|8@1+ (5,0) [0|1275] "cm/m" Vector__XXX
 SG_ LW_distance_in_state : 8|8@1+ (5,0) [0|1275] "m" Vector__XXX
 SG_ LW_max_coast_distance : 0|8@1+ (0.25,0) [0|63.75] "m" Vector__XXX

BO_ 2024 SP_MEM_Develop: 5 IFV_CWMP
 SG_ ME_RLM_Valid : 3|1@0+ (1,0) [0|1] "" Vector__XXX
 SG_ ME_LLM_Valid : 2|1@0+ (1,0) [0|1] "" Vector__XXX
 SG_ ME_BLM_Valid : 1|1@0+ (1,0) [0|1] "" Vector__XXX
 SG_ SP_type_mem : 20|3@0+ (1,0) [0|7] "" Vector__XXX
 SG_ SP_mem_State : 36|3@0+ (1,0) [0|7] "" Vector__XXX
 SG_ SP_MEM_SLM_MAX_TM : 31|11@0+ (0.1,0) [0|204.7] "" Vector__XXX
 SG_ SP_mem_host_low_spd_flg : 4|1@0+ (1,0) [0|1] "" Vector__XXX
 SG_ SP_MEM_BLM_MAX_TM : 15|11@0+ (0.1,0) [0|204.7] "" Vector__XXX
 SG_ SP_conf_mem : 7|3@0+ (1,0) [0|7] "" Vector__XXX

CM_ SG_ 2007 TJA_wait_hold_release "indicate TJA is working with safe stop hold status";
CM_ SG_ 2007 TJA_InvalidDrv_TillStop "indicate driver has been invalid in current ignition cycle";
CM_ SG_ 2007 TJA_Active_ACCOnly "indicate TJA is working in ACTIVE mode with ACC only ";
CM_ SG_ 2007 TJA_Allow_Activation_Magic "bit 0: vehicle invalid
bit 1: hands on
bit 2: lane valid
bit 3: host speed
bit 4: driver cancel";
CM_ SG_ 2007 TJA_Res_Rq "0x0:  no request for driver resume press 
0x1:  request for driver resume press ";
CM_ SG_ 2007 TJA_LatCtrl_Rq "0x0: Inhibit Lateral Control
0x1: Enable Lateral Control";
CM_ SG_ 2007 TJA_UcrtLocation_flg "0x0: TJA Location is Certain
0x1: TJA Location is Uncertain";
CM_ SG_ 2007 TJA_handsoff_Warning "0x0: No take Over Request
0x1: Taker Over Request";
CM_ SG_ 2007 TJA_DrvCancel_flg "0x0: No Driver Cancel
0x1: Driver Cancel";
CM_ SG_ 2007 TJA_DriverInvalid_flg "0x0: Driver valid
ox1: Driver Invalid (hands  off for long time)";
CM_ SG_ 2007 TJA_Allow_Activation "0x0: TJA is not Allowed to Activate
0x1: TJA Allow Activation";
CM_ SG_ 281 SP_lane_width "Steering path lane width. Either measured or filtered depending on availability and validity of the current measured lane width.";
CM_ SG_ 281 SP_type "Report which combination of lane markings and primary object trail were used to calculate the current steering path.";
CM_ SG_ 281 SP_conf "Reports the level of confidence the steering path processing algorithm has that the current steering path is correct.";
CM_ SG_ 281 SP_status "Reports the maturity status of the lane line detections and whether they are currently detected or coasted.";
CM_ SG_ 281 SP_LD_max_lw "Indication whether filtered lane width is used, because measured lane width is greater than maximum allowed lane width";
CM_ SG_ 281 SP_LD_min_lw "Indication whether filtered lane width is used, because measured lane width is less than minimum allowed lane width";
CM_ SG_ 281 BLM_Status "Left Lane Model confidence";
CM_ SG_ 281 SPP_max_range "Right lane Model confidence";
BA_DEF_ SG_  "GenSigVtName" STRING ;
BA_DEF_ SG_  "GenSigVtIndex" STRING ;
BA_DEF_ SG_  "GenSigVtEn" STRING ;
BA_DEF_ SG_  "GenSigCmt" STRING ;
BA_DEF_ SG_  "GenSigStartValue" INT 0 1000000000;
BA_DEF_ SG_  "UsedOnPgmDBC" ENUM  "No","Yes";
BA_DEF_ SG_  "GenSigMissingSourceValue" INT 0 1000000000;
BA_DEF_ SG_  "GenSigInactiveValue" INT 0 100000;
BA_DEF_ SG_  "GenSigSendType" ENUM  "Cyclic","OnWrite","vector_leerstring","OnChange","vector_leerstring","IfActive","vector_leerstring","NoSigSendType";
BA_DEF_ BO_  "NetworkInitialization" ENUM  "No","Yes";
BA_DEF_ BO_  "EventRateOfChange" INT 10 10000;
BA_DEF_ BO_  "GenMsgSendType" ENUM  "FixedPeriodic","Event","EnabledPeriodic","NotUsed","NotUsed","EventPeriodic","NotUsed","NotUsed","NoMsgSendType";
BA_DEF_ BO_  "TpApplType" STRING ;
BA_DEF_ BO_  "GenMsgILSupport" ENUM  "No","Yes";
BA_DEF_ SG_  "SystemSignalLongSymbol" STRING ;
BA_DEF_DEF_  "GenSigVtName" "";
BA_DEF_DEF_  "GenSigVtIndex" "";
BA_DEF_DEF_  "GenSigVtEn" "";
BA_DEF_DEF_  "GenSigCmt" "";
BA_DEF_DEF_  "GenSigStartValue" 0;
BA_DEF_DEF_  "UsedOnPgmDBC" "Yes";
BA_DEF_DEF_  "GenSigMissingSourceValue" 0;
BA_DEF_DEF_  "GenSigInactiveValue" 0;
BA_DEF_DEF_  "GenSigSendType" "NoSigSendType";
BA_DEF_DEF_  "NetworkInitialization" "Yes";
BA_DEF_DEF_  "EventRateOfChange" 10000;
BA_DEF_DEF_  "GenMsgSendType" "NoMsgSendType";
BA_DEF_DEF_  "TpApplType" "";
BA_DEF_DEF_  "GenMsgILSupport" "Yes";
BA_DEF_DEF_  "SystemSignalLongSymbol" "";
BA_ "GenMsgSendType" BO_ 2008 1;
BA_ "GenMsgSendType" BO_ 2007 1;
BA_ "GenMsgSendType" BO_ 1988 1;
BA_ "GenMsgSendType" BO_ 1987 1;
BA_ "GenMsgSendType" BO_ 1986 1;
BA_ "GenMsgSendType" BO_ 1994 1;
BA_ "GenMsgSendType" BO_ 1993 1;
BA_ "GenMsgSendType" BO_ 1992 1;
BA_ "GenMsgSendType" BO_ 1973 1;
BA_ "GenMsgSendType" BO_ 1972 1;
BA_ "GenMsgSendType" BO_ 1971 1;
BA_ "GenMsgSendType" BO_ 1970 1;
BA_ "GenMsgSendType" BO_ 1969 1;
BA_ "GenMsgSendType" BO_ 1968 1;
BA_ "GenMsgSendType" BO_ 1974 1;
BA_ "GenMsgSendType" BO_ 1975 1;
BA_ "GenMsgSendType" BO_ 1976 1;
BA_ "GenMsgSendType" BO_ 1977 1;
BA_ "GenMsgSendType" BO_ 1978 1;
BA_ "GenMsgSendType" BO_ 1979 1;
BA_ "GenMsgSendType" BO_ 1980 1;
BA_ "GenMsgSendType" BO_ 1981 1;
BA_ "GenMsgSendType" BO_ 1982 1;
BA_ "GenMsgSendType" BO_ 1984 1;
BA_ "GenMsgSendType" BO_ 1985 1;
BA_ "GenMsgSendType" BO_ 1989 1;
BA_ "GenMsgSendType" BO_ 1990 1;
BA_ "GenMsgSendType" BO_ 1991 1;
BA_ "GenMsgSendType" BO_ 1995 1;
BA_ "GenMsgSendType" BO_ 1996 1;
BA_ "GenMsgSendType" BO_ 1997 1;
BA_ "GenMsgSendType" BO_ 2000 1;
BA_ "GenMsgSendType" BO_ 1958 1;
BA_ "GenMsgSendType" BO_ 1957 1;
BA_ "GenMsgSendType" BO_ 1956 1;
BA_ "GenMsgSendType" BO_ 1955 1;
BA_ "GenMsgSendType" BO_ 1954 1;
BA_ "GenMsgSendType" BO_ 1953 1;
BA_ "GenMsgSendType" BO_ 1952 1;
BA_ "GenMsgSendType" BO_ 1998 1;
BA_ "GenMsgSendType" BO_ 1962 1;
BA_ "GenMsgSendType" BO_ 1961 1;
BA_ "GenMsgSendType" BO_ 1960 1;
BA_ "GenMsgSendType" BO_ 1966 1;
BA_ "GenMsgSendType" BO_ 1965 1;
BA_ "GenMsgSendType" BO_ 1964 1;
BA_ "GenMsgSendType" BO_ 2003 1;
BA_ "GenMsgSendType" BO_ 2002 1;
BA_ "GenMsgSendType" BO_ 2001 1;
BA_ "GenMsgSendType" BO_ 2018 1;
BA_ "GenMsgSendType" BO_ 2017 1;
BA_ "GenMsgSendType" BO_ 2016 1;
BA_ "GenSigSendType" SG_ 3221225472 VIS_TSR_SIGN_ID_1 1;
BA_ "GenSigSendType" SG_ 3221225472 VIS_TSR_SCENE_STATUS_1 1;
BA_ "GenSigVtName" SG_ 3221225472 VIS_TSR_SCENE_STATUS_1 "VtSig_VIS_TSR_SCENE_STATUS_1";
BA_ "GenSigVtEn" SG_ 3221225472 VIS_TSR_SCENE_STATUS_1 "TRUE";
BA_ "GenSigSendType" SG_ 3221225472 VIS_TSR_SCENE_ID_1 1;
BA_ "GenSigSendType" SG_ 3221225472 VIS_TSR_LANE_CHANGE 1;
BA_ "GenSigVtName" SG_ 3221225472 VIS_TSR_LANE_CHANGE "VtSig_VIS_TSR_LANE_CHANGE";
BA_ "GenSigVtEn" SG_ 3221225472 VIS_TSR_LANE_CHANGE "TRUE";
BA_ "GenSigSendType" SG_ 3221225472 VIS_TSR_ROAD_CLASS 1;
BA_ "GenSigVtName" SG_ 3221225472 VIS_TSR_ROAD_CLASS "VtSig_VIS_TSR_ROAD_CLASS";
BA_ "GenSigVtEn" SG_ 3221225472 VIS_TSR_ROAD_CLASS "TRUE";
BA_ "GenSigSendType" SG_ 3221225472 VIS_TSR_SPEED_UNIT 1;
BA_ "GenSigVtName" SG_ 3221225472 VIS_TSR_SPEED_UNIT "VtSig_VIS_TSR_SPEED_UNIT";
BA_ "GenSigVtEn" SG_ 3221225472 VIS_TSR_SPEED_UNIT "TRUE";
BA_ "GenSigSendType" SG_ 3221225472 VIS_TSR_TRAFFIC_STYLE 1;
BA_ "GenSigVtName" SG_ 3221225472 VIS_TSR_TRAFFIC_STYLE "VtSig_VIS_TSR_TRAFFIC_STYLE";
BA_ "GenSigVtEn" SG_ 3221225472 VIS_TSR_TRAFFIC_STYLE "TRUE";
BA_ "GenSigSendType" SG_ 3221225472 VIS_AHBC_DARK_ONCOMING_LANE 1;
BA_ "GenSigVtName" SG_ 3221225472 VIS_AHBC_DARK_ONCOMING_LANE "VtSig_VIS_AHBC_DARK_ONCOMING_LANE";
BA_ "GenSigVtEn" SG_ 3221225472 VIS_AHBC_DARK_ONCOMING_LANE "TRUE";
BA_ "GenSigSendType" SG_ 3221225472 VIS_AHBC_PRECEDING_SPOTS 1;
BA_ "GenSigSendType" SG_ 3221225472 VIS_AHBC_ONCOMING_SPOTS 1;
BA_ "GenSigSendType" SG_ 3221225472 VIS_AHBC_CLEAR_FIELD_OF_VIEW 1;
BA_ "GenSigVtName" SG_ 3221225472 VIS_AHBC_CLEAR_FIELD_OF_VIEW "VtSig_VIS_AHBC_CLEAR_FIELD_OF_VIEW";
BA_ "GenSigVtEn" SG_ 3221225472 VIS_AHBC_CLEAR_FIELD_OF_VIEW "TRUE";
BA_ "GenSigSendType" SG_ 3221225472 VIS_AHBC_STRUCT_SEPARATION_DET 1;
BA_ "GenSigVtName" SG_ 3221225472 VIS_AHBC_STRUCT_SEPARATION_DET "VtSig_VIS_AHBC_STRUCT_SEPARATION_DET";
BA_ "GenSigVtEn" SG_ 3221225472 VIS_AHBC_STRUCT_SEPARATION_DET "TRUE";
BA_ "GenSigSendType" SG_ 3221225472 VIS_AHBC_DAY_TIME_STATUS 1;
BA_ "GenSigVtName" SG_ 3221225472 VIS_AHBC_DAY_TIME_STATUS "VtSig_VIS_AHBC_DAY_TIME_STATUS";
BA_ "GenSigVtEn" SG_ 3221225472 VIS_AHBC_DAY_TIME_STATUS "TRUE";
BA_ "GenSigSendType" SG_ 3221225472 VIS_AHBC_FOG_DETECTION 1;
BA_ "GenSigVtName" SG_ 3221225472 VIS_AHBC_FOG_DETECTION "VtSig_VIS_AHBC_FOG_DETECTION";
BA_ "GenSigVtEn" SG_ 3221225472 VIS_AHBC_FOG_DETECTION "TRUE";
BA_ "GenSigSendType" SG_ 3221225472 VIS_AHBC_HIGHWAY_DETECTION 1;
BA_ "GenSigVtName" SG_ 3221225472 VIS_AHBC_HIGHWAY_DETECTION "VtSig_VIS_AHBC_HIGHWAY_DETECTION";
BA_ "GenSigVtEn" SG_ 3221225472 VIS_AHBC_HIGHWAY_DETECTION "TRUE";
BA_ "GenSigSendType" SG_ 3221225472 VIS_AHBC_URBAN_AREA_DETECTION 1;
BA_ "GenSigVtName" SG_ 3221225472 VIS_AHBC_URBAN_AREA_DETECTION "VtSig_VIS_AHBC_URBAN_AREA_DETECTION";
BA_ "GenSigVtEn" SG_ 3221225472 VIS_AHBC_URBAN_AREA_DETECTION "TRUE";
BA_ "GenSigSendType" SG_ 3221225472 VIS_AHBC_TRAFFIC_STYLE_DETECTION 1;
BA_ "GenSigVtName" SG_ 3221225472 VIS_AHBC_TRAFFIC_STYLE_DETECTION "VtSig_VIS_AHBC_TRAFFIC_STYLE_DETECTION";
BA_ "GenSigVtEn" SG_ 3221225472 VIS_AHBC_TRAFFIC_STYLE_DETECTION "TRUE";
BA_ "GenSigSendType" SG_ 3221225472 VIS_AHBC_OBJ_10_VERTICAL_POS 1;
BA_ "GenSigSendType" SG_ 3221225472 VIS_AHBC_OBJ_10_TYPE 1;
BA_ "GenSigVtName" SG_ 3221225472 VIS_AHBC_OBJ_10_TYPE "VtSig_VIS_AHBC_OBJ_10_TYPE";
BA_ "GenSigVtEn" SG_ 3221225472 VIS_AHBC_OBJ_10_TYPE "TRUE";
BA_ "GenSigSendType" SG_ 3221225472 VIS_AHBC_OBJ_10_ID 1;
BA_ "GenSigSendType" SG_ 3221225472 VIS_AHBC_OBJ_10_HORIZONTAL_POS 1;
BA_ "GenSigSendType" SG_ 3221225472 VIS_AHBC_OBJ_10_HORIZONTAL_DIM 1;
BA_ "GenSigSendType" SG_ 3221225472 VIS_AHBC_OBJ_10_DISTANCE 1;
BA_ "GenSigVtName" SG_ 3221225472 VIS_AHBC_OBJ_10_DISTANCE "VtSig_VIS_AHBC_OBJ_10_DISTANCE";
BA_ "GenSigVtEn" SG_ 3221225472 VIS_AHBC_OBJ_10_DISTANCE "TRUE";
BA_ "GenSigSendType" SG_ 3221225472 VIS_AHBC_OBJ_09_VERTICAL_POS 1;
BA_ "GenSigSendType" SG_ 3221225472 VIS_AHBC_OBJ_09_TYPE 1;
BA_ "GenSigVtName" SG_ 3221225472 VIS_AHBC_OBJ_09_TYPE "VtSig_VIS_AHBC_OBJ_09_TYPE";
BA_ "GenSigVtEn" SG_ 3221225472 VIS_AHBC_OBJ_09_TYPE "TRUE";
BA_ "GenSigSendType" SG_ 3221225472 VIS_AHBC_OBJ_09_ID 1;
BA_ "GenSigSendType" SG_ 3221225472 VIS_AHBC_OBJ_09_HORIZONTAL_POS 1;
BA_ "GenSigSendType" SG_ 3221225472 VIS_AHBC_OBJ_09_HORIZONTAL_DIM 1;
BA_ "GenSigSendType" SG_ 3221225472 VIS_AHBC_OBJ_09_DISTANCE 1;
BA_ "GenSigVtName" SG_ 3221225472 VIS_AHBC_OBJ_09_DISTANCE "VtSig_VIS_AHBC_OBJ_09_DISTANCE";
BA_ "GenSigVtEn" SG_ 3221225472 VIS_AHBC_OBJ_09_DISTANCE "TRUE";
BA_ "GenSigSendType" SG_ 3221225472 VIS_AHBC_OBJ_08_VERTICAL_POS 1;
BA_ "GenSigSendType" SG_ 3221225472 VIS_AHBC_OBJ_08_TYPE 1;
BA_ "GenSigVtName" SG_ 3221225472 VIS_AHBC_OBJ_08_TYPE "VtSig_VIS_AHBC_OBJ_08_TYPE";
BA_ "GenSigVtEn" SG_ 3221225472 VIS_AHBC_OBJ_08_TYPE "TRUE";
BA_ "GenSigSendType" SG_ 3221225472 VIS_AHBC_OBJ_08_ID 1;
BA_ "GenSigSendType" SG_ 3221225472 VIS_AHBC_OBJ_08_HORIZONTAL_POS 1;
BA_ "GenSigSendType" SG_ 3221225472 VIS_AHBC_OBJ_08_HORIZONTAL_DIM 1;
BA_ "GenSigSendType" SG_ 3221225472 VIS_AHBC_OBJ_08_DISTANCE 1;
BA_ "GenSigVtName" SG_ 3221225472 VIS_AHBC_OBJ_08_DISTANCE "VtSig_VIS_AHBC_OBJ_08_DISTANCE";
BA_ "GenSigVtEn" SG_ 3221225472 VIS_AHBC_OBJ_08_DISTANCE "TRUE";
BA_ "GenSigSendType" SG_ 3221225472 VIS_AHBC_OBJ_07_VERTICAL_POS 1;
BA_ "GenSigSendType" SG_ 3221225472 VIS_AHBC_OBJ_07_TYPE 1;
BA_ "GenSigVtName" SG_ 3221225472 VIS_AHBC_OBJ_07_TYPE "VtSig_VIS_AHBC_OBJ_07_TYPE";
BA_ "GenSigVtEn" SG_ 3221225472 VIS_AHBC_OBJ_07_TYPE "TRUE";
BA_ "GenSigSendType" SG_ 3221225472 VIS_AHBC_OBJ_07_ID 1;
BA_ "GenSigSendType" SG_ 3221225472 VIS_AHBC_OBJ_07_HORIZONTAL_POS 1;
BA_ "GenSigSendType" SG_ 3221225472 VIS_AHBC_OBJ_07_HORIZONTAL_DIM 1;
BA_ "GenSigSendType" SG_ 3221225472 VIS_AHBC_OBJ_07_DISTANCE 1;
BA_ "GenSigVtName" SG_ 3221225472 VIS_AHBC_OBJ_07_DISTANCE "VtSig_VIS_AHBC_OBJ_07_DISTANCE";
BA_ "GenSigVtEn" SG_ 3221225472 VIS_AHBC_OBJ_07_DISTANCE "TRUE";
BA_ "GenSigSendType" SG_ 3221225472 VIS_AHBC_OBJ_06_VERTICAL_POS 1;
BA_ "GenSigSendType" SG_ 3221225472 VIS_AHBC_OBJ_06_TYPE 1;
BA_ "GenSigVtName" SG_ 3221225472 VIS_AHBC_OBJ_06_TYPE "VtSig_VIS_AHBC_OBJ_06_TYPE";
BA_ "GenSigVtEn" SG_ 3221225472 VIS_AHBC_OBJ_06_TYPE "TRUE";
BA_ "GenSigSendType" SG_ 3221225472 VIS_AHBC_OBJ_06_ID 1;
BA_ "GenSigSendType" SG_ 3221225472 VIS_AHBC_OBJ_06_HORIZONTAL_POS 1;
BA_ "GenSigSendType" SG_ 3221225472 VIS_AHBC_OBJ_06_HORIZONTAL_DIM 1;
BA_ "GenSigSendType" SG_ 3221225472 VIS_AHBC_OBJ_06_DISTANCE 1;
BA_ "GenSigVtName" SG_ 3221225472 VIS_AHBC_OBJ_06_DISTANCE "VtSig_VIS_AHBC_OBJ_06_DISTANCE";
BA_ "GenSigVtEn" SG_ 3221225472 VIS_AHBC_OBJ_06_DISTANCE "TRUE";
BA_ "GenSigSendType" SG_ 3221225472 VIS_AHBC_OBJ_05_VERTICAL_POS 1;
BA_ "GenSigSendType" SG_ 3221225472 VIS_AHBC_OBJ_05_TYPE 1;
BA_ "GenSigVtName" SG_ 3221225472 VIS_AHBC_OBJ_05_TYPE "VtSig_VIS_AHBC_OBJ_05_TYPE";
BA_ "GenSigVtEn" SG_ 3221225472 VIS_AHBC_OBJ_05_TYPE "TRUE";
BA_ "GenSigSendType" SG_ 3221225472 VIS_AHBC_OBJ_05_ID 1;
BA_ "GenSigSendType" SG_ 3221225472 VIS_AHBC_OBJ_05_HORIZONTAL_POS 1;
BA_ "GenSigSendType" SG_ 3221225472 VIS_AHBC_OBJ_05_HORIZONTAL_DIM 1;
BA_ "GenSigSendType" SG_ 3221225472 VIS_AHBC_OBJ_05_DISTANCE 1;
BA_ "GenSigVtName" SG_ 3221225472 VIS_AHBC_OBJ_05_DISTANCE "VtSig_VIS_AHBC_OBJ_05_DISTANCE";
BA_ "GenSigVtEn" SG_ 3221225472 VIS_AHBC_OBJ_05_DISTANCE "TRUE";
BA_ "GenSigSendType" SG_ 3221225472 VIS_AHBC_OBJ_04_VERTICAL_POS 1;
BA_ "GenSigSendType" SG_ 3221225472 VIS_AHBC_OBJ_04_TYPE 1;
BA_ "GenSigVtName" SG_ 3221225472 VIS_AHBC_OBJ_04_TYPE "VtSig_VIS_AHBC_OBJ_04_TYPE";
BA_ "GenSigVtEn" SG_ 3221225472 VIS_AHBC_OBJ_04_TYPE "TRUE";
BA_ "GenSigSendType" SG_ 3221225472 VIS_AHBC_OBJ_04_ID 1;
BA_ "GenSigSendType" SG_ 3221225472 VIS_AHBC_OBJ_04_HORIZONTAL_POS 1;
BA_ "GenSigSendType" SG_ 3221225472 VIS_AHBC_OBJ_04_HORIZONTAL_DIM 1;
BA_ "GenSigSendType" SG_ 3221225472 VIS_AHBC_OBJ_04_DISTANCE 1;
BA_ "GenSigVtName" SG_ 3221225472 VIS_AHBC_OBJ_04_DISTANCE "VtSig_VIS_AHBC_OBJ_04_DISTANCE";
BA_ "GenSigVtEn" SG_ 3221225472 VIS_AHBC_OBJ_04_DISTANCE "TRUE";
BA_ "GenSigSendType" SG_ 3221225472 VIS_AHBC_OBJ_03_VERTICAL_POS 1;
BA_ "GenSigSendType" SG_ 3221225472 VIS_AHBC_OBJ_03_TYPE 1;
BA_ "GenSigVtName" SG_ 3221225472 VIS_AHBC_OBJ_03_TYPE "VtSig_VIS_AHBC_OBJ_03_TYPE";
BA_ "GenSigVtEn" SG_ 3221225472 VIS_AHBC_OBJ_03_TYPE "TRUE";
BA_ "GenSigSendType" SG_ 3221225472 VIS_AHBC_OBJ_03_ID 1;
BA_ "GenSigSendType" SG_ 3221225472 VIS_AHBC_OBJ_03_HORIZONTAL_POS 1;
BA_ "GenSigSendType" SG_ 3221225472 VIS_AHBC_OBJ_03_HORIZONTAL_DIM 1;
BA_ "GenSigSendType" SG_ 3221225472 VIS_AHBC_OBJ_03_DISTANCE 1;
BA_ "GenSigVtName" SG_ 3221225472 VIS_AHBC_OBJ_03_DISTANCE "VtSig_VIS_AHBC_OBJ_3_DISTANCE";
BA_ "GenSigVtEn" SG_ 3221225472 VIS_AHBC_OBJ_03_DISTANCE "TRUE";
BA_ "GenSigSendType" SG_ 3221225472 VIS_AHBC_OBJ_02_VERTICAL_POS 1;
BA_ "GenSigSendType" SG_ 3221225472 VIS_AHBC_OBJ_02_TYPE 1;
BA_ "GenSigVtName" SG_ 3221225472 VIS_AHBC_OBJ_02_TYPE "VtSig_VIS_AHBC_OBJ_02_TYPE";
BA_ "GenSigVtEn" SG_ 3221225472 VIS_AHBC_OBJ_02_TYPE "TRUE";
BA_ "GenSigSendType" SG_ 3221225472 VIS_AHBC_OBJ_02_ID 1;
BA_ "GenSigSendType" SG_ 3221225472 VIS_AHBC_OBJ_02_HORIZONTAL_POS 1;
BA_ "GenSigSendType" SG_ 3221225472 VIS_AHBC_OBJ_02_HORIZONTAL_DIM 1;
BA_ "GenSigSendType" SG_ 3221225472 VIS_AHBC_OBJ_02_DISTANCE 1;
BA_ "GenSigVtName" SG_ 3221225472 VIS_AHBC_OBJ_02_DISTANCE "VtSig_VIS_AHBC_OBJ_02_DISTANCE";
BA_ "GenSigVtEn" SG_ 3221225472 VIS_AHBC_OBJ_02_DISTANCE "TRUE";
BA_ "GenSigSendType" SG_ 3221225472 VIS_AHBC_OBJ_01_VERTICAL_POS 1;
BA_ "GenSigSendType" SG_ 3221225472 VIS_AHBC_OBJ_01_TYPE 1;
BA_ "GenSigVtName" SG_ 3221225472 VIS_AHBC_OBJ_01_TYPE "VtSig_VIS_AHBC_OBJ_01_TYPE";
BA_ "GenSigVtEn" SG_ 3221225472 VIS_AHBC_OBJ_01_TYPE "TRUE";
BA_ "GenSigSendType" SG_ 3221225472 VIS_AHBC_OBJ_01_ID 1;
BA_ "GenSigSendType" SG_ 3221225472 VIS_AHBC_OBJ_01_HORIZONTAL_POS 1;
BA_ "GenSigSendType" SG_ 3221225472 VIS_AHBC_OBJ_01_HORIZONTAL_DIM 1;
BA_ "GenSigSendType" SG_ 3221225472 VIS_AHBC_OBJ_01_DISTANCE 1;
BA_ "GenSigVtName" SG_ 3221225472 VIS_AHBC_OBJ_01_DISTANCE "VtSig_VIS_AHBC_OBJ_01_DISTANCE";
BA_ "GenSigVtEn" SG_ 3221225472 VIS_AHBC_OBJ_01_DISTANCE "TRUE";
BA_ "GenSigSendType" SG_ 3221225472 VIS_LANE_RIGHT_PARALL_STATUS 1;
BA_ "GenSigVtName" SG_ 3221225472 VIS_LANE_RIGHT_PARALL_STATUS "VtSig_VIS_LANE_RIGHT_PARALL_STATUS";
BA_ "GenSigVtEn" SG_ 3221225472 VIS_LANE_RIGHT_PARALL_STATUS "TRUE";
BA_ "GenSigSendType" SG_ 3221225472 VIS_LANE_RIGHT_INDIVID_STATUS 1;
BA_ "GenSigVtName" SG_ 3221225472 VIS_LANE_RIGHT_INDIVID_STATUS "VtSig_VIS_LANE_RIGHT_INIDIV_STATUS";
BA_ "GenSigVtEn" SG_ 3221225472 VIS_LANE_RIGHT_INDIVID_STATUS "TRUE";
BA_ "GenSigSendType" SG_ 3221225472 VIS_LANE_LEFT_PARALL_STATUS 1;
BA_ "GenSigVtName" SG_ 3221225472 VIS_LANE_LEFT_PARALL_STATUS "VtSig_VIS_LANE_LEFT_PARALL_STATUS";
BA_ "GenSigVtEn" SG_ 3221225472 VIS_LANE_LEFT_PARALL_STATUS "TRUE";
BA_ "GenSigSendType" SG_ 3221225472 VIS_LANE_LEFT_INDIVID_STATUS 1;
BA_ "GenSigVtName" SG_ 3221225472 VIS_LANE_LEFT_INDIVID_STATUS "VtSig_VIS_LANE_LEFT_INDIVID_STATUS";
BA_ "GenSigVtEn" SG_ 3221225472 VIS_LANE_LEFT_INDIVID_STATUS "TRUE";
BA_ "GenSigSendType" SG_ 3221225472 VIS_PREDICTION_INFORMATION_R 1;
BA_ "GenSigSendType" SG_ 3221225472 VIS_PREDICTION_INFORMATION_L 1;
BA_ "GenSigSendType" SG_ 3221225472 VIS_CENTER_POLYNOMIAL_WIDTH 1;
BA_ "GenSigSendType" SG_ 3221225472 VIS_CENTER_POLYNOMIAL_A3 1;
BA_ "GenSigSendType" SG_ 3221225472 VIS_CENTER_POLYNOMIAL_A2 1;
BA_ "GenSigSendType" SG_ 3221225472 VIS_CENTER_POLYNOMIAL_LINECASE 1;
BA_ "GenSigVtName" SG_ 3221225472 VIS_CENTER_POLYNOMIAL_LINECASE "VtSig_VIS_CENTER_POLYNOMIAL_LINECASE";
BA_ "GenSigVtEn" SG_ 3221225472 VIS_CENTER_POLYNOMIAL_LINECASE "TRUE";
BA_ "GenSigSendType" SG_ 3221225472 VIS_CENTER_POLYNOMIAL_A1 1;
BA_ "GenSigSendType" SG_ 3221225472 VIS_CENTER_POLYNOMIAL_A0 1;
BA_ "GenSigSendType" SG_ 3221225472 VIS_CENTER_POLYNOMIAL_LANECONF 1;
BA_ "GenSigVtName" SG_ 3221225472 VIS_CENTER_POLYNOMIAL_LANECONF "VtSig_VIS_CENTER_POLYNOMIAL_LANECONF";
BA_ "GenSigVtEn" SG_ 3221225472 VIS_CENTER_POLYNOMIAL_LANECONF "TRUE";
BA_ "GenSigStartValue" SG_ 3221225472 VIS_OBS_LONG_VEL_15 2048;
BA_ "GenSigStartValue" SG_ 3221225472 VIS_OBS_LONG_VEL_14 2048;
BA_ "GenSigStartValue" SG_ 3221225472 VIS_OBS_LONG_VEL_13 2048;
BA_ "GenSigStartValue" SG_ 3221225472 VIS_OBS_LONG_VEL_12 2048;
BA_ "GenSigStartValue" SG_ 3221225472 VIS_OBS_LONG_VEL_11 2048;
BA_ "GenSigStartValue" SG_ 3221225472 VIS_OBS_LONG_VEL_10 2048;
BA_ "GenSigStartValue" SG_ 3221225472 VIS_OBS_LONG_VEL_09 2048;
BA_ "GenSigStartValue" SG_ 3221225472 VIS_OBS_LONG_VEL_08 2048;
BA_ "GenSigStartValue" SG_ 3221225472 VIS_OBS_LONG_VEL_07 2048;
BA_ "GenSigStartValue" SG_ 3221225472 VIS_OBS_LONG_VEL_06 2048;
BA_ "GenSigStartValue" SG_ 3221225472 VIS_OBS_LONG_VEL_05 2048;
BA_ "GenSigStartValue" SG_ 3221225472 VIS_OBS_LONG_VEL_04 2048;
BA_ "GenSigStartValue" SG_ 3221225472 VIS_OBS_LONG_VEL_03 2048;
BA_ "GenSigStartValue" SG_ 3221225472 VIS_OBS_LONG_VEL_02 2048;
BA_ "GenSigStartValue" SG_ 3221225472 VIS_OBS_LAT_VEL_15 2048;
BA_ "GenSigStartValue" SG_ 3221225472 VIS_OBS_LAT_VEL_14 2048;
BA_ "GenSigStartValue" SG_ 3221225472 VIS_OBS_LAT_VEL_13 2048;
BA_ "GenSigStartValue" SG_ 3221225472 VIS_OBS_LAT_VEL_12 2048;
BA_ "GenSigStartValue" SG_ 3221225472 VIS_OBS_LAT_VEL_11 2048;
BA_ "GenSigStartValue" SG_ 3221225472 VIS_OBS_LAT_VEL_10 2048;
BA_ "GenSigStartValue" SG_ 3221225472 VIS_OBS_LAT_VEL_09 2048;
BA_ "GenSigStartValue" SG_ 3221225472 VIS_OBS_LAT_VEL_08 2048;
BA_ "GenSigStartValue" SG_ 3221225472 VIS_OBS_LAT_VEL_07 2048;
BA_ "GenSigStartValue" SG_ 3221225472 VIS_OBS_LAT_VEL_06 2048;
BA_ "GenSigStartValue" SG_ 3221225472 VIS_OBS_LAT_VEL_05 2048;
BA_ "GenSigStartValue" SG_ 3221225472 VIS_OBS_LAT_VEL_04 2048;
BA_ "GenSigStartValue" SG_ 3221225472 VIS_OBS_LAT_VEL_03 2048;
BA_ "GenSigStartValue" SG_ 3221225472 VIS_OBS_LAT_VEL_02 2048;
BA_ "GenSigStartValue" SG_ 3221225472 VIS_OBS_LAT_POS_15 2048;
BA_ "GenSigStartValue" SG_ 3221225472 VIS_OBS_LAT_POS_14 2048;
BA_ "GenSigStartValue" SG_ 3221225472 VIS_OBS_LAT_POS_13 2048;
BA_ "GenSigStartValue" SG_ 3221225472 VIS_OBS_LAT_POS_12 2048;
BA_ "GenSigStartValue" SG_ 3221225472 VIS_OBS_LAT_POS_11 2048;
BA_ "GenSigStartValue" SG_ 3221225472 VIS_OBS_LAT_POS_10 2048;
BA_ "GenSigStartValue" SG_ 3221225472 VIS_OBS_LAT_POS_09 2048;
BA_ "GenSigStartValue" SG_ 3221225472 VIS_OBS_LAT_POS_08 2048;
BA_ "GenSigStartValue" SG_ 3221225472 VIS_OBS_LAT_POS_07 2048;
BA_ "GenSigStartValue" SG_ 3221225472 VIS_OBS_LAT_POS_06 2048;
BA_ "GenSigStartValue" SG_ 3221225472 VIS_OBS_LAT_POS_05 2048;
BA_ "GenSigStartValue" SG_ 3221225472 VIS_OBS_LAT_POS_04 2048;
BA_ "GenSigStartValue" SG_ 3221225472 VIS_OBS_LAT_POS_03 2048;
BA_ "GenSigStartValue" SG_ 3221225472 VIS_OBS_LAT_POS_02 2048;
BA_ "GenSigStartValue" SG_ 3221225472 VIS_OBS_LONG_VEL_01 2048;
BA_ "GenSigStartValue" SG_ 3221225472 VIS_OBS_LAT_VEL_01 2048;
BA_ "GenSigStartValue" SG_ 3221225472 VIS_OBS_LAT_POS_01 2048;
BA_ "GenSigSendType" SG_ 3221225472 VIS_LANE_RIGHT_PARALL_RANGE 1;
BA_ "GenSigSendType" SG_ 3221225472 VIS_LANE_RIGHT_PARALL_A3 1;
BA_ "GenSigSendType" SG_ 3221225472 VIS_LANE_RIGHT_PARALL_A2 1;
BA_ "GenSigSendType" SG_ 3221225472 VIS_LANE_RIGHT_PARALL_A1 1;
BA_ "GenSigSendType" SG_ 3221225472 VIS_LANE_RIGHT_PARALL_A0 1;
BA_ "GenSigSendType" SG_ 3221225472 VIS_LANE_RIGHT_PA_MARKER_COLOR 1;
BA_ "GenSigVtName" SG_ 3221225472 VIS_LANE_RIGHT_PA_MARKER_COLOR "VtSig_VIS_LANE_RIGHT_PA_MARKER_COLOR";
BA_ "GenSigVtEn" SG_ 3221225472 VIS_LANE_RIGHT_PA_MARKER_COLOR "TRUE";
BA_ "GenSigSendType" SG_ 3221225472 VIS_LANE_RIGHT_INDIVID_RANGE 1;
BA_ "GenSigSendType" SG_ 3221225472 VIS_LANE_RIGHT_INDIVID_A3 1;
BA_ "GenSigSendType" SG_ 3221225472 VIS_LANE_RIGHT_INDIVID_A2 1;
BA_ "GenSigSendType" SG_ 3221225472 VIS_LANE_RIGHT_INDIVID_A1 1;
BA_ "GenSigSendType" SG_ 3221225472 VIS_LANE_RIGHT_INDIVID_A0 1;
BA_ "GenSigSendType" SG_ 3221225472 VIS_LANE_RIGHT_IN_MARKER_COLOR 1;
BA_ "GenSigVtName" SG_ 3221225472 VIS_LANE_RIGHT_IN_MARKER_COLOR "VtSig_VIS_LANE_RIGHT_IN_MARKER_COLOR";
BA_ "GenSigVtEn" SG_ 3221225472 VIS_LANE_RIGHT_IN_MARKER_COLOR "TRUE";
BA_ "GenSigSendType" SG_ 3221225472 VIS_LANE_LEFT_PARALL_RANGE 1;
BA_ "GenSigSendType" SG_ 3221225472 VIS_LANE_LEFT_PARALL_A3 1;
BA_ "GenSigSendType" SG_ 3221225472 VIS_LANE_LEFT_PARALL_A2 1;
BA_ "GenSigSendType" SG_ 3221225472 VIS_LANE_LEFT_PARALL_A1 1;
BA_ "GenSigSendType" SG_ 3221225472 VIS_LANE_LEFT_PARALL_A0 1;
BA_ "GenSigSendType" SG_ 3221225472 VIS_LANE_LEFT_PA_MARKER_COLOR 1;
BA_ "GenSigVtName" SG_ 3221225472 VIS_LANE_LEFT_PA_MARKER_COLOR "VtSig_VIS_LANE_LEFT_PA_MARKER_COLOR";
BA_ "GenSigVtEn" SG_ 3221225472 VIS_LANE_LEFT_PA_MARKER_COLOR "TRUE";
BA_ "GenSigSendType" SG_ 3221225472 VIS_LANE_LEFT_INDIVID_RANGE 1;
BA_ "GenSigSendType" SG_ 3221225472 VIS_LANE_LEFT_INDIVID_A3 1;
BA_ "GenSigSendType" SG_ 3221225472 VIS_LANE_LEFT_INDIVID_A2 1;
BA_ "GenSigSendType" SG_ 3221225472 VIS_LANE_LEFT_INDIVID_A1 1;
BA_ "GenSigSendType" SG_ 3221225472 VIS_LANE_LEFT_INDIVID_A0 1;
BA_ "GenSigSendType" SG_ 3221225472 VIS_LANE_LEFT_IN_MARKER_COLOR 1;
BA_ "GenSigVtName" SG_ 3221225472 VIS_LANE_LEFT_IN_MARKER_COLOR "VtSig_VIS_LANE_LEFT_IN_MARKER_COLOR";
BA_ "GenSigVtEn" SG_ 3221225472 VIS_LANE_LEFT_IN_MARKER_COLOR "TRUE";
BA_ "GenSigSendType" SG_ 3221225472 SIGN_8_VIS_TSR_RELEVANT 1;
BA_ "GenSigSendType" SG_ 3221225472 SIGN_8_VIS_TSR_RELEVANT_DECISION 1;
BA_ "GenSigVtName" SG_ 3221225472 SIGN_8_VIS_TSR_RELEVANT_DECISION "VtSig_SIGN_8_VIS_TRS_RELEVANT_DECISION";
BA_ "GenSigVtEn" SG_ 3221225472 SIGN_8_VIS_TSR_RELEVANT_DECISION "TRUE";
BA_ "GenSigSendType" SG_ 3221225472 SIGN_8_VIS_TSR_LOCATION 1;
BA_ "GenSigVtName" SG_ 3221225472 SIGN_8_VIS_TSR_LOCATION "VtSig_SIGN_8_VIS_TSR_LOCATION";
BA_ "GenSigVtEn" SG_ 3221225472 SIGN_8_VIS_TSR_LOCATION "TRUE";
BA_ "GenSigSendType" SG_ 3221225472 SIGN_8_VIS_TSR_SIGN_EMBEDDED 1;
BA_ "GenSigSendType" SG_ 3221225472 SIGN_8_VIS_TSR_POSITION_LATERAL 1;
BA_ "GenSigSendType" SG_ 3221225472 SIGN_8_VIS_TSR_SUPPL_TYPE_1ST 1;
BA_ "GenSigVtName" SG_ 3221225472 SIGN_8_VIS_TSR_SUPPL_TYPE_1ST "VtSig_SIGN_8_VIS_TSR_SUPPL_TYPE_1ST";
BA_ "GenSigVtEn" SG_ 3221225472 SIGN_8_VIS_TSR_SUPPL_TYPE_1ST "TRUE";
BA_ "GenSigSendType" SG_ 3221225472 SIGN_8_VIS_TSR_ID 1;
BA_ "GenSigSendType" SG_ 3221225472 SIGN_8_VIS_TSR_SIGN_VALUE 1;
BA_ "GenSigSendType" SG_ 3221225472 SIGN_8_VIS_TSR_CONFIDENCE 1;
BA_ "GenSigSendType" SG_ 3221225472 SIGN_8_VIS_TSR_STATUS 1;
BA_ "GenSigVtName" SG_ 3221225472 SIGN_8_VIS_TSR_STATUS "VtSig_SIGN_8_VIS_TSR_STATUS";
BA_ "GenSigVtEn" SG_ 3221225472 SIGN_8_VIS_TSR_STATUS "TRUE";
BA_ "GenSigSendType" SG_ 3221225472 SIGN_8_VIS_TSR_SUPPL_TYPE_2ND 1;
BA_ "GenSigVtName" SG_ 3221225472 SIGN_8_VIS_TSR_SUPPL_TYPE_2ND "VtSig_SIGN_8_VIS_TSR_SUPPL_TYPE_2ND";
BA_ "GenSigVtEn" SG_ 3221225472 SIGN_8_VIS_TSR_SUPPL_TYPE_2ND "TRUE";
BA_ "GenSigSendType" SG_ 3221225472 SIGN_8_VIS_TSR_LOCATION_LANE 1;
BA_ "GenSigSendType" SG_ 3221225472 SIGN_8_VIS_TSR_ELECTRONIC_SIGN 1;
BA_ "GenSigVtName" SG_ 3221225472 SIGN_8_VIS_TSR_ELECTRONIC_SIGN "VtSig_SIGN_8_VIS_TSR_ELECTRONIC_SIGN";
BA_ "GenSigVtEn" SG_ 3221225472 SIGN_8_VIS_TSR_ELECTRONIC_SIGN "TRUE";
BA_ "GenSigSendType" SG_ 3221225472 SIGN_8_VIS_TSR_TYPE 1;
BA_ "GenSigVtName" SG_ 3221225472 SIGN_8_VIS_TSR_TYPE "VtSig_SIGN_8_VIS_TSR_TYPE";
BA_ "GenSigVtEn" SG_ 3221225472 SIGN_8_VIS_TSR_TYPE "TRUE";
BA_ "GenSigSendType" SG_ 3221225472 SIGN_7_VIS_TSR_RELEVANT 1;
BA_ "GenSigSendType" SG_ 3221225472 SIGN_7_VIS_TSR_RELEVANT_DECISION 1;
BA_ "GenSigVtName" SG_ 3221225472 SIGN_7_VIS_TSR_RELEVANT_DECISION "VtSig_SIGN_7_VIS_TRS_RELEVANT_DECISION";
BA_ "GenSigVtEn" SG_ 3221225472 SIGN_7_VIS_TSR_RELEVANT_DECISION "TRUE";
BA_ "GenSigSendType" SG_ 3221225472 SIGN_7_VIS_TSR_LOCATION 1;
BA_ "GenSigVtName" SG_ 3221225472 SIGN_7_VIS_TSR_LOCATION "VtSig_SIGN_7_VIS_TSR_LOCATION";
BA_ "GenSigVtEn" SG_ 3221225472 SIGN_7_VIS_TSR_LOCATION "TRUE";
BA_ "GenSigSendType" SG_ 3221225472 SIGN_7_VIS_TSR_SIGN_EMBEDDED 1;
BA_ "GenSigSendType" SG_ 3221225472 SIGN_7_VIS_TSR_POSITION_LATERAL 1;
BA_ "GenSigSendType" SG_ 3221225472 SIGN_7_VIS_TSR_SUPPL_TYPE_1ST 1;
BA_ "GenSigVtName" SG_ 3221225472 SIGN_7_VIS_TSR_SUPPL_TYPE_1ST "VtSig_SIGN_7_VIS_TSR_SUPPL_TYPE_1ST";
BA_ "GenSigVtEn" SG_ 3221225472 SIGN_7_VIS_TSR_SUPPL_TYPE_1ST "TRUE";
BA_ "GenSigSendType" SG_ 3221225472 SIGN_7_VIS_TSR_ID 1;
BA_ "GenSigSendType" SG_ 3221225472 SIGN_7_VIS_TSR_SIGN_VALUE 1;
BA_ "GenSigSendType" SG_ 3221225472 SIGN_7_VIS_TSR_CONFIDENCE 1;
BA_ "GenSigSendType" SG_ 3221225472 SIGN_7_VIS_TSR_STATUS 1;
BA_ "GenSigVtName" SG_ 3221225472 SIGN_7_VIS_TSR_STATUS "VtSig_SIGN_7_VIS_TSR_STATUS";
BA_ "GenSigVtEn" SG_ 3221225472 SIGN_7_VIS_TSR_STATUS "TRUE";
BA_ "GenSigSendType" SG_ 3221225472 SIGN_7_VIS_TSR_SUPPL_TYPE_2ND 1;
BA_ "GenSigVtName" SG_ 3221225472 SIGN_7_VIS_TSR_SUPPL_TYPE_2ND "VtSig_SIGN_7_VIS_TSR_SUPPL_TYPE_2ND";
BA_ "GenSigVtEn" SG_ 3221225472 SIGN_7_VIS_TSR_SUPPL_TYPE_2ND "TRUE";
BA_ "GenSigSendType" SG_ 3221225472 SIGN_7_VIS_TSR_LOCATION_LANE 1;
BA_ "GenSigSendType" SG_ 3221225472 SIGN_7_VIS_TSR_ELECTRONIC_SIGN 1;
BA_ "GenSigVtName" SG_ 3221225472 SIGN_7_VIS_TSR_ELECTRONIC_SIGN "VtSig_SIGN_7_VIS_TSR_ELECTRONIC_SIGN";
BA_ "GenSigVtEn" SG_ 3221225472 SIGN_7_VIS_TSR_ELECTRONIC_SIGN "TRUE";
BA_ "GenSigSendType" SG_ 3221225472 SIGN_7_VIS_TSR_TYPE 1;
BA_ "GenSigVtName" SG_ 3221225472 SIGN_7_VIS_TSR_TYPE "VtSig_SIGN_7_VIS_TSR_TYPE";
BA_ "GenSigVtEn" SG_ 3221225472 SIGN_7_VIS_TSR_TYPE "TRUE";
BA_ "GenSigSendType" SG_ 3221225472 SIGN_6_VIS_TSR_RELEVANT 1;
BA_ "GenSigSendType" SG_ 3221225472 SIGN_6_VIS_TSR_RELEVANT_DECISION 1;
BA_ "GenSigVtName" SG_ 3221225472 SIGN_6_VIS_TSR_RELEVANT_DECISION "VtSig_SIGN_6_VIS_TRS_RELEVANT_DECISION";
BA_ "GenSigVtEn" SG_ 3221225472 SIGN_6_VIS_TSR_RELEVANT_DECISION "TRUE";
BA_ "GenSigSendType" SG_ 3221225472 SIGN_6_VIS_TSR_LOCATION 1;
BA_ "GenSigVtName" SG_ 3221225472 SIGN_6_VIS_TSR_LOCATION "VtSig_SIGN_6_VIS_TSR_LOCATION";
BA_ "GenSigVtEn" SG_ 3221225472 SIGN_6_VIS_TSR_LOCATION "TRUE";
BA_ "GenSigSendType" SG_ 3221225472 SIGN_6_VIS_TSR_SIGN_EMBEDDED 1;
BA_ "GenSigSendType" SG_ 3221225472 SIGN_6_VIS_TSR_POSITION_LATERAL 1;
BA_ "GenSigSendType" SG_ 3221225472 SIGN_6_VIS_TSR_SUPPL_TYPE_1ST 1;
BA_ "GenSigVtName" SG_ 3221225472 SIGN_6_VIS_TSR_SUPPL_TYPE_1ST "VtSig_SIGN_6_VIS_TSR_SUPPL_TYPE_1ST";
BA_ "GenSigVtEn" SG_ 3221225472 SIGN_6_VIS_TSR_SUPPL_TYPE_1ST "TRUE";
BA_ "GenSigSendType" SG_ 3221225472 SIGN_6_VIS_TSR_ID 1;
BA_ "GenSigSendType" SG_ 3221225472 SIGN_6_VIS_TSR_SIGN_VALUE 1;
BA_ "GenSigSendType" SG_ 3221225472 SIGN_6_VIS_TSR_CONFIDENCE 1;
BA_ "GenSigSendType" SG_ 3221225472 SIGN_6_VIS_TSR_STATUS 1;
BA_ "GenSigVtName" SG_ 3221225472 SIGN_6_VIS_TSR_STATUS "VtSig_SIGN_6_VIS_TSR_STATUS";
BA_ "GenSigVtEn" SG_ 3221225472 SIGN_6_VIS_TSR_STATUS "TRUE";
BA_ "GenSigSendType" SG_ 3221225472 SIGN_6_VIS_TSR_SUPPL_TYPE_2ND 1;
BA_ "GenSigVtName" SG_ 3221225472 SIGN_6_VIS_TSR_SUPPL_TYPE_2ND "VtSig_SIGN_6_VIS_TSR_SUPPL_TYPE_2ND";
BA_ "GenSigVtEn" SG_ 3221225472 SIGN_6_VIS_TSR_SUPPL_TYPE_2ND "TRUE";
BA_ "GenSigSendType" SG_ 3221225472 SIGN_6_VIS_TSR_LOCATION_LANE 1;
BA_ "GenSigSendType" SG_ 3221225472 SIGN_6_VIS_TSR_ELECTRONIC_SIGN 1;
BA_ "GenSigVtName" SG_ 3221225472 SIGN_6_VIS_TSR_ELECTRONIC_SIGN "VtSig_SIGN_6_VIS_TSR_ELECTRONIC_SIGN";
BA_ "GenSigVtEn" SG_ 3221225472 SIGN_6_VIS_TSR_ELECTRONIC_SIGN "TRUE";
BA_ "GenSigSendType" SG_ 3221225472 SIGN_6_VIS_TSR_TYPE 1;
BA_ "GenSigVtName" SG_ 3221225472 SIGN_6_VIS_TSR_TYPE "VtSig_SIGN_6_VIS_TSR_TYPE";
BA_ "GenSigVtEn" SG_ 3221225472 SIGN_6_VIS_TSR_TYPE "TRUE";
BA_ "GenSigSendType" SG_ 3221225472 SIGN_5_VIS_TSR_RELEVANT 1;
BA_ "GenSigSendType" SG_ 3221225472 SIGN_5_VIS_TSR_RELEVANT_DECISION 1;
BA_ "GenSigVtName" SG_ 3221225472 SIGN_5_VIS_TSR_RELEVANT_DECISION "VtSig_SIGN_5_VIS_TRS_RELEVANT_DECISION";
BA_ "GenSigVtEn" SG_ 3221225472 SIGN_5_VIS_TSR_RELEVANT_DECISION "TRUE";
BA_ "GenSigSendType" SG_ 3221225472 SIGN_5_VIS_TSR_LOCATION 1;
BA_ "GenSigVtName" SG_ 3221225472 SIGN_5_VIS_TSR_LOCATION "VtSig_SIGN_5_VIS_TSR_LOCATION";
BA_ "GenSigVtEn" SG_ 3221225472 SIGN_5_VIS_TSR_LOCATION "TRUE";
BA_ "GenSigSendType" SG_ 3221225472 SIGN_5_VIS_TSR_SIGN_EMBEDDED 1;
BA_ "GenSigSendType" SG_ 3221225472 SIGN_5_VIS_TSR_POSITION_LATERAL 1;
BA_ "GenSigSendType" SG_ 3221225472 SIGN_5_VIS_TSR_SUPPL_TYPE_1ST 1;
BA_ "GenSigVtName" SG_ 3221225472 SIGN_5_VIS_TSR_SUPPL_TYPE_1ST "VtSig_SIGN_5_VIS_TSR_SUPPL_TYPE_1ST";
BA_ "GenSigVtEn" SG_ 3221225472 SIGN_5_VIS_TSR_SUPPL_TYPE_1ST "TRUE";
BA_ "GenSigSendType" SG_ 3221225472 SIGN_5_VIS_TSR_ID 1;
BA_ "GenSigSendType" SG_ 3221225472 SIGN_5_VIS_TSR_SIGN_VALUE 1;
BA_ "GenSigSendType" SG_ 3221225472 SIGN_5_VIS_TSR_CONFIDENCE 1;
BA_ "GenSigSendType" SG_ 3221225472 SIGN_5_VIS_TSR_STATUS 1;
BA_ "GenSigVtName" SG_ 3221225472 SIGN_5_VIS_TSR_STATUS "VtSig_SIGN_5_VIS_TSR_STATUS";
BA_ "GenSigVtEn" SG_ 3221225472 SIGN_5_VIS_TSR_STATUS "TRUE";
BA_ "GenSigSendType" SG_ 3221225472 SIGN_5_VIS_TSR_SUPPL_TYPE_2ND 1;
BA_ "GenSigVtName" SG_ 3221225472 SIGN_5_VIS_TSR_SUPPL_TYPE_2ND "VtSig_SIGN_5_VIS_TSR_SUPPL_TYPE_2ND";
BA_ "GenSigVtEn" SG_ 3221225472 SIGN_5_VIS_TSR_SUPPL_TYPE_2ND "TRUE";
BA_ "GenSigSendType" SG_ 3221225472 SIGN_5_VIS_TSR_LOCATION_LANE 1;
BA_ "GenSigSendType" SG_ 3221225472 SIGN_5_VIS_TSR_ELECTRONIC_SIGN 1;
BA_ "GenSigVtName" SG_ 3221225472 SIGN_5_VIS_TSR_ELECTRONIC_SIGN "VtSig_SIGN_5_VIS_TSR_ELECTRONIC_SIGN";
BA_ "GenSigVtEn" SG_ 3221225472 SIGN_5_VIS_TSR_ELECTRONIC_SIGN "TRUE";
BA_ "GenSigSendType" SG_ 3221225472 SIGN_5_VIS_TSR_TYPE 1;
BA_ "GenSigVtName" SG_ 3221225472 SIGN_5_VIS_TSR_TYPE "VtSig_SIGN_5_VIS_TSR_TYPE";
BA_ "GenSigVtEn" SG_ 3221225472 SIGN_5_VIS_TSR_TYPE "TRUE";
BA_ "GenSigSendType" SG_ 3221225472 SIGN_4_VIS_TSR_RELEVANT 1;
BA_ "GenSigSendType" SG_ 3221225472 SIGN_4_VIS_TSR_RELEVANT_DECISION 1;
BA_ "GenSigVtName" SG_ 3221225472 SIGN_4_VIS_TSR_RELEVANT_DECISION "VtSig_SIGN_4_VIS_TRS_RELEVANT_DECISION";
BA_ "GenSigVtEn" SG_ 3221225472 SIGN_4_VIS_TSR_RELEVANT_DECISION "TRUE";
BA_ "GenSigSendType" SG_ 3221225472 SIGN_4_VIS_TSR_LOCATION 1;
BA_ "GenSigVtName" SG_ 3221225472 SIGN_4_VIS_TSR_LOCATION "VtSig_SIGN_4_VIS_TSR_LOCATION";
BA_ "GenSigVtEn" SG_ 3221225472 SIGN_4_VIS_TSR_LOCATION "TRUE";
BA_ "GenSigSendType" SG_ 3221225472 SIGN_4_VIS_TSR_SIGN_EMBEDDED 1;
BA_ "GenSigSendType" SG_ 3221225472 SIGN_4_VIS_TSR_POSITION_LATERAL 1;
BA_ "GenSigSendType" SG_ 3221225472 SIGN_4_VIS_TSR_SUPPL_TYPE_1ST 1;
BA_ "GenSigVtName" SG_ 3221225472 SIGN_4_VIS_TSR_SUPPL_TYPE_1ST "VtSig_SIGN_4_VIS_TSR_SUPPL_TYPE_1ST";
BA_ "GenSigVtEn" SG_ 3221225472 SIGN_4_VIS_TSR_SUPPL_TYPE_1ST "TRUE";
BA_ "GenSigSendType" SG_ 3221225472 SIGN_4_VIS_TSR_ID 1;
BA_ "GenSigSendType" SG_ 3221225472 SIGN_4_VIS_TSR_SIGN_VALUE 1;
BA_ "GenSigSendType" SG_ 3221225472 SIGN_4_VIS_TSR_CONFIDENCE 1;
BA_ "GenSigSendType" SG_ 3221225472 SIGN_4_VIS_TSR_STATUS 1;
BA_ "GenSigVtName" SG_ 3221225472 SIGN_4_VIS_TSR_STATUS "VtSig_SIGN_4_VIS_TSR_STATUS";
BA_ "GenSigVtEn" SG_ 3221225472 SIGN_4_VIS_TSR_STATUS "TRUE";
BA_ "GenSigSendType" SG_ 3221225472 SIGN_4_VIS_TSR_SUPPL_TYPE_2ND 1;
BA_ "GenSigVtName" SG_ 3221225472 SIGN_4_VIS_TSR_SUPPL_TYPE_2ND "VtSig_SIGN_4_VIS_TSR_SUPPL_TYPE_2ND";
BA_ "GenSigVtEn" SG_ 3221225472 SIGN_4_VIS_TSR_SUPPL_TYPE_2ND "TRUE";
BA_ "GenSigSendType" SG_ 3221225472 SIGN_4_VIS_TSR_LOCATION_LANE 1;
BA_ "GenSigSendType" SG_ 3221225472 SIGN_4_VIS_TSR_ELECTRONIC_SIGN 1;
BA_ "GenSigVtName" SG_ 3221225472 SIGN_4_VIS_TSR_ELECTRONIC_SIGN "VtSig_SIGN_4_VIS_TSR_ELECTRONIC_SIGN";
BA_ "GenSigVtEn" SG_ 3221225472 SIGN_4_VIS_TSR_ELECTRONIC_SIGN "TRUE";
BA_ "GenSigSendType" SG_ 3221225472 SIGN_4_VIS_TSR_TYPE 1;
BA_ "GenSigVtName" SG_ 3221225472 SIGN_4_VIS_TSR_TYPE "VtSig_SIGN_4_VIS_TSR_TYPE";
BA_ "GenSigVtEn" SG_ 3221225472 SIGN_4_VIS_TSR_TYPE "TRUE";
BA_ "GenSigSendType" SG_ 3221225472 SIGN_3_VIS_TSR_RELEVANT 1;
BA_ "GenSigSendType" SG_ 3221225472 SIGN_3_VIS_TSR_RELEVANT_DECISION 1;
BA_ "GenSigVtName" SG_ 3221225472 SIGN_3_VIS_TSR_RELEVANT_DECISION "VtSig_SIGN_3_VIS_TRS_RELEVANT_DECISION";
BA_ "GenSigVtEn" SG_ 3221225472 SIGN_3_VIS_TSR_RELEVANT_DECISION "TRUE";
BA_ "GenSigSendType" SG_ 3221225472 SIGN_3_VIS_TSR_LOCATION 1;
BA_ "GenSigVtName" SG_ 3221225472 SIGN_3_VIS_TSR_LOCATION "VtSig_SIGN_3_VIS_TSR_LOCATION";
BA_ "GenSigVtEn" SG_ 3221225472 SIGN_3_VIS_TSR_LOCATION "TRUE";
BA_ "GenSigSendType" SG_ 3221225472 SIGN_3_VIS_TSR_SIGN_EMBEDDED 1;
BA_ "GenSigSendType" SG_ 3221225472 SIGN_3_VIS_TSR_POSITION_LATERAL 1;
BA_ "GenSigSendType" SG_ 3221225472 SIGN_3_VIS_TSR_SUPPL_TYPE_1ST 1;
BA_ "GenSigVtName" SG_ 3221225472 SIGN_3_VIS_TSR_SUPPL_TYPE_1ST "VtSig_SIGN_3_VIS_TSR_SUPPL_TYPE_1ST";
BA_ "GenSigVtEn" SG_ 3221225472 SIGN_3_VIS_TSR_SUPPL_TYPE_1ST "TRUE";
BA_ "GenSigSendType" SG_ 3221225472 SIGN_3_VIS_TSR_ID 1;
BA_ "GenSigSendType" SG_ 3221225472 SIGN_3_VIS_TSR_SIGN_VALUE 1;
BA_ "GenSigSendType" SG_ 3221225472 SIGN_3_VIS_TSR_CONFIDENCE 1;
BA_ "GenSigSendType" SG_ 3221225472 SIGN_3_VIS_TSR_STATUS 1;
BA_ "GenSigVtName" SG_ 3221225472 SIGN_3_VIS_TSR_STATUS "VtSig_SIGN_3_VIS_TSR_STATUS";
BA_ "GenSigVtEn" SG_ 3221225472 SIGN_3_VIS_TSR_STATUS "TRUE";
BA_ "GenSigSendType" SG_ 3221225472 SIGN_3_VIS_TSR_SUPPL_TYPE_2ND 1;
BA_ "GenSigVtName" SG_ 3221225472 SIGN_3_VIS_TSR_SUPPL_TYPE_2ND "VtSig_SIGN_3_VIS_TSR_SUPPL_TYPE_2ND";
BA_ "GenSigVtEn" SG_ 3221225472 SIGN_3_VIS_TSR_SUPPL_TYPE_2ND "TRUE";
BA_ "GenSigSendType" SG_ 3221225472 SIGN_3_VIS_TSR_LOCATION_LANE 1;
BA_ "GenSigSendType" SG_ 3221225472 SIGN_3_VIS_TSR_ELECTRONIC_SIGN 1;
BA_ "GenSigVtName" SG_ 3221225472 SIGN_3_VIS_TSR_ELECTRONIC_SIGN "VtSig_SIGN_3_VIS_TSR_ELECTRONIC_SIGN";
BA_ "GenSigVtEn" SG_ 3221225472 SIGN_3_VIS_TSR_ELECTRONIC_SIGN "TRUE";
BA_ "GenSigSendType" SG_ 3221225472 SIGN_3_VIS_TSR_TYPE 1;
BA_ "GenSigVtName" SG_ 3221225472 SIGN_3_VIS_TSR_TYPE "VtSig_SIGN_3_VIS_TSR_TYPE";
BA_ "GenSigVtEn" SG_ 3221225472 SIGN_3_VIS_TSR_TYPE "TRUE";
BA_ "GenSigSendType" SG_ 3221225472 SIGN_2_VIS_TSR_RELEVANT 1;
BA_ "GenSigSendType" SG_ 3221225472 SIGN_2_VIS_TSR_RELEVANT_DECISION 1;
BA_ "GenSigVtName" SG_ 3221225472 SIGN_2_VIS_TSR_RELEVANT_DECISION "VtSig_SIGN_2_VIS_TRS_RELEVANT_DECISION";
BA_ "GenSigVtEn" SG_ 3221225472 SIGN_2_VIS_TSR_RELEVANT_DECISION "TRUE";
BA_ "GenSigSendType" SG_ 3221225472 SIGN_2_VIS_TSR_LOCATION 1;
BA_ "GenSigVtName" SG_ 3221225472 SIGN_2_VIS_TSR_LOCATION "VtSig_SIGN_2_VIS_TSR_LOCATION";
BA_ "GenSigVtEn" SG_ 3221225472 SIGN_2_VIS_TSR_LOCATION "TRUE";
BA_ "GenSigSendType" SG_ 3221225472 SIGN_2_VIS_TSR_SIGN_EMBEDDED 1;
BA_ "GenSigSendType" SG_ 3221225472 SIGN_2_VIS_TSR_POSITION_LATERAL 1;
BA_ "GenSigSendType" SG_ 3221225472 SIGN_2_VIS_TSR_SUPPL_TYPE_1ST 1;
BA_ "GenSigVtName" SG_ 3221225472 SIGN_2_VIS_TSR_SUPPL_TYPE_1ST "VtSig_SIGN_2_VIS_TSR_SUPPL_TYPE_1ST";
BA_ "GenSigVtEn" SG_ 3221225472 SIGN_2_VIS_TSR_SUPPL_TYPE_1ST "TRUE";
BA_ "GenSigSendType" SG_ 3221225472 SIGN_2_VIS_TSR_ID 1;
BA_ "GenSigSendType" SG_ 3221225472 SIGN_2_VIS_TSR_SIGN_VALUE 1;
BA_ "GenSigSendType" SG_ 3221225472 SIGN_2_VIS_TSR_CONFIDENCE 1;
BA_ "GenSigSendType" SG_ 3221225472 SIGN_2_VIS_TSR_STATUS 1;
BA_ "GenSigVtName" SG_ 3221225472 SIGN_2_VIS_TSR_STATUS "VtSig_SIGN_2_VIS_TSR_STATUS";
BA_ "GenSigVtEn" SG_ 3221225472 SIGN_2_VIS_TSR_STATUS "TRUE";
BA_ "GenSigSendType" SG_ 3221225472 SIGN_2_VIS_TSR_SUPPL_TYPE_2ND 1;
BA_ "GenSigVtName" SG_ 3221225472 SIGN_2_VIS_TSR_SUPPL_TYPE_2ND "VtSig_SIGN_2_VIS_TSR_SUPPL_TYPE_2ND";
BA_ "GenSigVtEn" SG_ 3221225472 SIGN_2_VIS_TSR_SUPPL_TYPE_2ND "TRUE";
BA_ "GenSigSendType" SG_ 3221225472 SIGN_2_VIS_TSR_LOCATION_LANE 1;
BA_ "GenSigSendType" SG_ 3221225472 SIGN_2_VIS_TSR_ELECTRONIC_SIGN 1;
BA_ "GenSigVtName" SG_ 3221225472 SIGN_2_VIS_TSR_ELECTRONIC_SIGN "VtSig_SIGN_2_VIS_TSR_ELECTRONIC_SIGN";
BA_ "GenSigVtEn" SG_ 3221225472 SIGN_2_VIS_TSR_ELECTRONIC_SIGN "TRUE";
BA_ "GenSigSendType" SG_ 3221225472 SIGN_2_VIS_TSR_TYPE 1;
BA_ "GenSigVtName" SG_ 3221225472 SIGN_2_VIS_TSR_TYPE "VtSig_SIGN_2_VIS_TSR_TYPE";
BA_ "GenSigVtEn" SG_ 3221225472 SIGN_2_VIS_TSR_TYPE "TRUE";
BA_ "GenSigSendType" SG_ 3221225472 SIGN_1_VIS_TSR_RELEVANT 1;
BA_ "GenSigSendType" SG_ 3221225472 SIGN_1_VIS_TSR_RELEVANT_DECISION 1;
BA_ "GenSigVtName" SG_ 3221225472 SIGN_1_VIS_TSR_RELEVANT_DECISION "VtSig_SIGN_1_VIS_TRS_RELEVANT_DECISION";
BA_ "GenSigVtEn" SG_ 3221225472 SIGN_1_VIS_TSR_RELEVANT_DECISION "TRUE";
BA_ "GenSigSendType" SG_ 3221225472 SIGN_1_VIS_TSR_LOCATION 1;
BA_ "GenSigVtName" SG_ 3221225472 SIGN_1_VIS_TSR_LOCATION "VtSig_SIGN_1_VIS_TSR_LOCATION";
BA_ "GenSigVtEn" SG_ 3221225472 SIGN_1_VIS_TSR_LOCATION "TRUE";
BA_ "GenSigSendType" SG_ 3221225472 SIGN_1_VIS_TSR_SIGN_EMBEDDED 1;
BA_ "GenSigSendType" SG_ 3221225472 SIGN_1_VIS_TSR_POSITION_LATERAL 1;
BA_ "GenSigSendType" SG_ 3221225472 SIGN_1_VIS_TSR_SUPPL_TYPE_1ST 1;
BA_ "GenSigVtName" SG_ 3221225472 SIGN_1_VIS_TSR_SUPPL_TYPE_1ST "VtSig_SIGN_1_VIS_TSR_SUPPL_TYPE_1ST";
BA_ "GenSigVtEn" SG_ 3221225472 SIGN_1_VIS_TSR_SUPPL_TYPE_1ST "TRUE";
BA_ "GenSigSendType" SG_ 3221225472 SIGN_1_VIS_TSR_ID 1;
BA_ "GenSigSendType" SG_ 3221225472 SIGN_1_VIS_TSR_SIGN_VALUE 1;
BA_ "GenSigSendType" SG_ 3221225472 SIGN_1_VIS_TSR_CONFIDENCE 1;
BA_ "GenSigSendType" SG_ 3221225472 SIGN_1_VIS_TSR_STATUS 1;
BA_ "GenSigVtName" SG_ 3221225472 SIGN_1_VIS_TSR_STATUS "VtSig_SIGN_1_VIS_TSR_STATUS";
BA_ "GenSigVtEn" SG_ 3221225472 SIGN_1_VIS_TSR_STATUS "TRUE";
BA_ "GenSigSendType" SG_ 3221225472 SIGN_1_VIS_TSR_SUPPL_TYPE_2ND 1;
BA_ "GenSigVtName" SG_ 3221225472 SIGN_1_VIS_TSR_SUPPL_TYPE_2ND "VtSig_SIGN_1_VIS_TSR_SUPPL_TYPE_2ND";
BA_ "GenSigVtEn" SG_ 3221225472 SIGN_1_VIS_TSR_SUPPL_TYPE_2ND "TRUE";
BA_ "GenSigSendType" SG_ 3221225472 SIGN_1_VIS_TSR_LOCATION_LANE 1;
BA_ "GenSigSendType" SG_ 3221225472 SIGN_1_VIS_TSR_ELECTRONIC_SIGN 1;
BA_ "GenSigVtName" SG_ 3221225472 SIGN_1_VIS_TSR_ELECTRONIC_SIGN "VtSig_SIGN_1_VIS_TSR_ELECTRONIC_SIGN";
BA_ "GenSigVtEn" SG_ 3221225472 SIGN_1_VIS_TSR_ELECTRONIC_SIGN "TRUE";
BA_ "GenSigSendType" SG_ 3221225472 SIGN_1_VIS_TSR_TYPE 1;
BA_ "GenSigVtName" SG_ 3221225472 SIGN_1_VIS_TSR_TYPE "VtSig_SIGN_1_VIS_TSR_TYPE";
BA_ "GenSigVtEn" SG_ 3221225472 SIGN_1_VIS_TSR_TYPE "TRUE";
BA_ "GenSigSendType" SG_ 3221225472 VIS_LANE_PARALL_PROB 1;
BA_ "GenSigSendType" SG_ 3221225472 VIS_ROAD_ISTUNNEL_ENTRYEXIT 1;
BA_ "GenSigSendType" SG_ 3221225472 VIS_OBS_CIPV 1;
BA_ "GenSigSendType" SG_ 3221225472 VIS_FCN_VIS_VRU_FCE_UNCONF_BRK 1;
BA_ "GenSigSendType" SG_ 3221225472 VIS_FCN_VIS_VEH_FCE_UNCONF_BRK 1;
BA_ "GenSigSendType" SG_ 3221225472 VIS_FCW_VIS_ONLY_VRU_WARN 1;
BA_ "GenSigSendType" SG_ 3221225472 VIS_FCW_VIS_ONLY_VRU_PART_BRAKE 1;
BA_ "GenSigSendType" SG_ 3221225472 VIS_FCW_VIS_ONLY_VEH_PART_BRAKE 1;
BA_ "GenSigSendType" SG_ 3221225472 VIS_FCW_SENS_LEVEL 1;
BA_ "GenSigVtName" SG_ 3221225472 VIS_FCW_SENS_LEVEL "VtSig_VIS_FCW_SENS_LEVEL";
BA_ "GenSigVtEn" SG_ 3221225472 VIS_FCW_SENS_LEVEL "TRUE";
BA_ "GenSigSendType" SG_ 3221225472 VIS_FCW_NEAR_RNG_OBS_VIO 1;
BA_ "GenSigVtName" SG_ 3221225472 VIS_FCW_NEAR_RNG_OBS_VIO "VtSig_VIS_FCN_NEAR_RNG_OBS_VIO";
BA_ "GenSigVtEn" SG_ 3221225472 VIS_FCW_NEAR_RNG_OBS_VIO "TRUE";
BA_ "GenSigSendType" SG_ 3221225472 VIS_FCW_VIS_ONLY_VEH_WARN 1;
BA_ "GenSigSendType" SG_ 3221225472 VIS_FCW_VIS_ONLY_VEH_BRAKE 1;
BA_ "GenSigSendType" SG_ 3221225472 VIS_FCW_VIS_ONLY_VRU_BRAKE 1;
BA_ "GenSigSendType" SG_ 3221225472 PAC_visTrkID 1;
BA_ "GenSigSendType" SG_ 3221225472 PAC_Stage_age 1;
BA_ "GenSigSendType" SG_ 3221225472 PAC_Object_class 1;
BA_ "GenSigVtName" SG_ 3221225472 PAC_Object_class "VtSig_PAC_Object_class";
BA_ "GenSigVtEn" SG_ 3221225472 PAC_Object_class "TRUE";
BA_ "GenSigSendType" SG_ 3221225472 P9C_visTrkID 1;
BA_ "GenSigSendType" SG_ 3221225472 P9C_Stage_age 1;
BA_ "GenSigSendType" SG_ 3221225472 P9C_Object_class 1;
BA_ "GenSigVtName" SG_ 3221225472 P9C_Object_class "VtSig_P9C_Object_class";
BA_ "GenSigVtEn" SG_ 3221225472 P9C_Object_class "TRUE";
BA_ "GenSigSendType" SG_ 3221225472 P8C_visTrkID 1;
BA_ "GenSigSendType" SG_ 3221225472 P8C_Stage_age 1;
BA_ "GenSigSendType" SG_ 3221225472 P8C_Object_class 1;
BA_ "GenSigVtName" SG_ 3221225472 P8C_Object_class "VtSig_P8C_Object_class";
BA_ "GenSigVtEn" SG_ 3221225472 P8C_Object_class "TRUE";
BA_ "GenSigSendType" SG_ 3221225472 P7C_visTrkID 1;
BA_ "GenSigSendType" SG_ 3221225472 P7C_Stage_age 1;
BA_ "GenSigSendType" SG_ 3221225472 P7C_Object_class 1;
BA_ "GenSigVtName" SG_ 3221225472 P7C_Object_class "VtSig_P7C_Object_class";
BA_ "GenSigVtEn" SG_ 3221225472 P7C_Object_class "TRUE";
BA_ "GenSigSendType" SG_ 3221225472 P6C_visTrkID 1;
BA_ "GenSigSendType" SG_ 3221225472 P6C_Stage_age 1;
BA_ "GenSigSendType" SG_ 3221225472 P6C_Object_class 1;
BA_ "GenSigVtName" SG_ 3221225472 P6C_Object_class "VtSig_P6C_Object_class";
BA_ "GenSigVtEn" SG_ 3221225472 P6C_Object_class "TRUE";
BA_ "GenSigSendType" SG_ 3221225472 P5C_visTrkID 1;
BA_ "GenSigSendType" SG_ 3221225472 P5C_Stage_age 1;
BA_ "GenSigSendType" SG_ 3221225472 P5C_Object_class 1;
BA_ "GenSigVtName" SG_ 3221225472 P5C_Object_class "VtSig_P5C_Object_class";
BA_ "GenSigVtEn" SG_ 3221225472 P5C_Object_class "TRUE";
BA_ "GenSigSendType" SG_ 3221225472 P4C_visTrkID 1;
BA_ "GenSigSendType" SG_ 3221225472 P4C_Stage_age 1;
BA_ "GenSigSendType" SG_ 3221225472 P4C_Object_class 1;
BA_ "GenSigVtName" SG_ 3221225472 P4C_Object_class "VtSig_P4C_Object_class";
BA_ "GenSigVtEn" SG_ 3221225472 P4C_Object_class "TRUE";
BA_ "GenSigSendType" SG_ 3221225472 P3C_visTrkID 1;
BA_ "GenSigSendType" SG_ 3221225472 P3C_Stage_age 1;
BA_ "GenSigSendType" SG_ 3221225472 P3C_Object_class 1;
BA_ "GenSigVtName" SG_ 3221225472 P3C_Object_class "VtSig_P3C_Object_class";
BA_ "GenSigVtEn" SG_ 3221225472 P3C_Object_class "TRUE";
BA_ "GenSigSendType" SG_ 3221225472 P2C_visTrkID 1;
BA_ "GenSigSendType" SG_ 3221225472 P2C_Stage_age 1;
BA_ "GenSigSendType" SG_ 3221225472 P2C_Object_class 1;
BA_ "GenSigVtName" SG_ 3221225472 P2C_Object_class "VtSig_P2C_Object_class";
BA_ "GenSigVtEn" SG_ 3221225472 P2C_Object_class "TRUE";
BA_ "GenSigSendType" SG_ 3221225472 PAB_A_lat_obj 1;
BA_ "GenSigSendType" SG_ 3221225472 PAB_V_lat_obj 1;
BA_ "GenSigSendType" SG_ 3221225472 PAB_FcwConfidence 1;
BA_ "GenSigSendType" SG_ 3221225472 PAB_CmbbPrimaryConfidence 1;
BA_ "GenSigSendType" SG_ 3221225472 PAB_Status 1;
BA_ "GenSigVtName" SG_ 3221225472 PAB_Status "VtSig_PAB_Status";
BA_ "GenSigVtEn" SG_ 3221225472 PAB_Status "TRUE";
BA_ "GenSigSendType" SG_ 3221225472 PAB_Age 1;
BA_ "GenSigSendType" SG_ 3221225472 P9B_V_lat_obj 1;
BA_ "GenSigSendType" SG_ 3221225472 P9B_FcwConfidence 1;
BA_ "GenSigSendType" SG_ 3221225472 P9B_CmbbPrimaryConfidence 1;
BA_ "GenSigSendType" SG_ 3221225472 P9B_Status 1;
BA_ "GenSigVtName" SG_ 3221225472 P9B_Status "VtSig_P9B_Status";
BA_ "GenSigVtEn" SG_ 3221225472 P9B_Status "TRUE";
BA_ "GenSigSendType" SG_ 3221225472 P9B_Age 1;
BA_ "GenSigSendType" SG_ 3221225472 P9B_A_lat_obj 1;
BA_ "GenSigSendType" SG_ 3221225472 P8B_V_lat_obj 1;
BA_ "GenSigSendType" SG_ 3221225472 P8B_FcwConfidence 1;
BA_ "GenSigSendType" SG_ 3221225472 P8B_CmbbPrimaryConfidence 1;
BA_ "GenSigSendType" SG_ 3221225472 P8B_Status 1;
BA_ "GenSigVtName" SG_ 3221225472 P8B_Status "VtSig_P8B_Status";
BA_ "GenSigVtEn" SG_ 3221225472 P8B_Status "TRUE";
BA_ "GenSigSendType" SG_ 3221225472 P8B_Age 1;
BA_ "GenSigSendType" SG_ 3221225472 P8B_A_lat_obj 1;
BA_ "GenSigSendType" SG_ 3221225472 P7B_V_lat_obj 1;
BA_ "GenSigSendType" SG_ 3221225472 P7B_FcwConfidence 1;
BA_ "GenSigSendType" SG_ 3221225472 P7B_CmbbPrimaryConfidence 1;
BA_ "GenSigSendType" SG_ 3221225472 P7B_Status 1;
BA_ "GenSigVtName" SG_ 3221225472 P7B_Status "VtSig_P7B_Status";
BA_ "GenSigVtEn" SG_ 3221225472 P7B_Status "TRUE";
BA_ "GenSigSendType" SG_ 3221225472 P7B_Age 1;
BA_ "GenSigSendType" SG_ 3221225472 P7B_A_lat_obj 1;
BA_ "GenSigSendType" SG_ 3221225472 P6B_V_lat_obj 1;
BA_ "GenSigSendType" SG_ 3221225472 P6B_FcwConfidence 1;
BA_ "GenSigSendType" SG_ 3221225472 P6B_CmbbPrimaryConfidence 1;
BA_ "GenSigSendType" SG_ 3221225472 P6B_Status 1;
BA_ "GenSigVtName" SG_ 3221225472 P6B_Status "VtSig_P6B_Status";
BA_ "GenSigVtEn" SG_ 3221225472 P6B_Status "TRUE";
BA_ "GenSigSendType" SG_ 3221225472 P6B_Age 1;
BA_ "GenSigSendType" SG_ 3221225472 P6B_A_lat_obj 1;
BA_ "GenSigSendType" SG_ 3221225472 P5B_V_lat_obj 1;
BA_ "GenSigSendType" SG_ 3221225472 P5B_FcwConfidence 1;
BA_ "GenSigSendType" SG_ 3221225472 P5B_CmbbPrimaryConfidence 1;
BA_ "GenSigSendType" SG_ 3221225472 P5B_Status 1;
BA_ "GenSigVtName" SG_ 3221225472 P5B_Status "VtSig_P5B_Status";
BA_ "GenSigVtEn" SG_ 3221225472 P5B_Status "TRUE";
BA_ "GenSigSendType" SG_ 3221225472 P5B_Age 1;
BA_ "GenSigSendType" SG_ 3221225472 P5B_A_lat_obj 1;
BA_ "GenSigSendType" SG_ 3221225472 P4B_V_lat_obj 1;
BA_ "GenSigSendType" SG_ 3221225472 P4B_FcwConfidence 1;
BA_ "GenSigSendType" SG_ 3221225472 P4B_CmbbPrimaryConfidence 1;
BA_ "GenSigSendType" SG_ 3221225472 P4B_Status 1;
BA_ "GenSigVtName" SG_ 3221225472 P4B_Status "VtSig_P4B_Status";
BA_ "GenSigVtEn" SG_ 3221225472 P4B_Status "TRUE";
BA_ "GenSigSendType" SG_ 3221225472 P4B_Age 1;
BA_ "GenSigSendType" SG_ 3221225472 P4B_A_lat_obj 1;
BA_ "GenSigSendType" SG_ 3221225472 P3B_V_lat_obj 1;
BA_ "GenSigSendType" SG_ 3221225472 P3B_FcwConfidence 1;
BA_ "GenSigSendType" SG_ 3221225472 P3B_CmbbPrimaryConfidence 1;
BA_ "GenSigSendType" SG_ 3221225472 P3B_Status 1;
BA_ "GenSigVtName" SG_ 3221225472 P3B_Status "VtSig_P3B_Status";
BA_ "GenSigVtEn" SG_ 3221225472 P3B_Status "TRUE";
BA_ "GenSigSendType" SG_ 3221225472 P3B_Age 1;
BA_ "GenSigSendType" SG_ 3221225472 P3B_A_lat_obj 1;
BA_ "GenSigSendType" SG_ 3221225472 P2B_V_lat_obj 1;
BA_ "GenSigSendType" SG_ 3221225472 P2B_FcwConfidence 1;
BA_ "GenSigSendType" SG_ 3221225472 P2B_CmbbPrimaryConfidence 1;
BA_ "GenSigSendType" SG_ 3221225472 P2B_Status 1;
BA_ "GenSigVtName" SG_ 3221225472 P2B_Status "VtSig_P2B_Status";
BA_ "GenSigVtEn" SG_ 3221225472 P2B_Status "TRUE";
BA_ "GenSigSendType" SG_ 3221225472 P2B_Age 1;
BA_ "GenSigSendType" SG_ 3221225472 P2B_A_lat_obj 1;
BA_ "GenSigSendType" SG_ 3221225472 PAA_V_long_obj 1;
BA_ "GenSigSendType" SG_ 3221225472 PAA_TrackID 1;
BA_ "GenSigSendType" SG_ 3221225472 PAA_L_long_rel 1;
BA_ "GenSigStartValue" SG_ 3221225472 PAA_L_long_rel 3000;
BA_ "GenSigSendType" SG_ 3221225472 PAA_L_lat_rel 1;
BA_ "GenSigSendType" SG_ 3221225472 PAA_A_long_obj 1;
BA_ "GenSigSendType" SG_ 3221225472 P9A_V_long_obj 1;
BA_ "GenSigSendType" SG_ 3221225472 P9A_TrackID 1;
BA_ "GenSigSendType" SG_ 3221225472 P9A_L_long_rel 1;
BA_ "GenSigStartValue" SG_ 3221225472 P9A_L_long_rel 3000;
BA_ "GenSigSendType" SG_ 3221225472 P9A_L_lat_rel 1;
BA_ "GenSigSendType" SG_ 3221225472 P9A_A_long_obj 1;
BA_ "GenSigSendType" SG_ 3221225472 P8A_V_long_obj 1;
BA_ "GenSigSendType" SG_ 3221225472 P8A_TrackID 1;
BA_ "GenSigSendType" SG_ 3221225472 P8A_L_long_rel 1;
BA_ "GenSigStartValue" SG_ 3221225472 P8A_L_long_rel 3000;
BA_ "GenSigSendType" SG_ 3221225472 P8A_L_lat_rel 1;
BA_ "GenSigSendType" SG_ 3221225472 P8A_A_long_obj 1;
BA_ "GenSigSendType" SG_ 3221225472 P7A_V_long_obj 1;
BA_ "GenSigSendType" SG_ 3221225472 P7A_TrackID 1;
BA_ "GenSigSendType" SG_ 3221225472 P7A_L_long_rel 1;
BA_ "GenSigStartValue" SG_ 3221225472 P7A_L_long_rel 3000;
BA_ "GenSigSendType" SG_ 3221225472 P7A_L_lat_rel 1;
BA_ "GenSigSendType" SG_ 3221225472 P7A_A_long_obj 1;
BA_ "GenSigSendType" SG_ 3221225472 P6A_L_lat_rel 1;
BA_ "GenSigSendType" SG_ 3221225472 P6A_A_long_obj 1;
BA_ "GenSigSendType" SG_ 3221225472 P6A_V_long_obj 1;
BA_ "GenSigSendType" SG_ 3221225472 P6A_L_long_rel 1;
BA_ "GenSigStartValue" SG_ 3221225472 P6A_L_long_rel 3000;
BA_ "GenSigSendType" SG_ 3221225472 P6A_TrackID 1;
BA_ "GenSigSendType" SG_ 3221225472 P5A_L_lat_rel 1;
BA_ "GenSigSendType" SG_ 3221225472 P5A_A_long_obj 1;
BA_ "GenSigSendType" SG_ 3221225472 P5A_V_long_obj 1;
BA_ "GenSigSendType" SG_ 3221225472 P5A_L_long_rel 1;
BA_ "GenSigStartValue" SG_ 3221225472 P5A_L_long_rel 3000;
BA_ "GenSigSendType" SG_ 3221225472 P5A_TrackID 1;
BA_ "GenSigSendType" SG_ 3221225472 P4A_L_lat_rel 1;
BA_ "GenSigSendType" SG_ 3221225472 P4A_A_long_obj 1;
BA_ "GenSigSendType" SG_ 3221225472 P4A_V_long_obj 1;
BA_ "GenSigSendType" SG_ 3221225472 P4A_L_long_rel 1;
BA_ "GenSigStartValue" SG_ 3221225472 P4A_L_long_rel 3000;
BA_ "GenSigSendType" SG_ 3221225472 P4A_TrackID 1;
BA_ "GenSigSendType" SG_ 3221225472 P3A_L_lat_rel 1;
BA_ "GenSigSendType" SG_ 3221225472 P3A_A_long_obj 1;
BA_ "GenSigSendType" SG_ 3221225472 P3A_V_long_obj 1;
BA_ "GenSigSendType" SG_ 3221225472 P3A_L_long_rel 1;
BA_ "GenSigStartValue" SG_ 3221225472 P3A_L_long_rel 3000;
BA_ "GenSigSendType" SG_ 3221225472 P3A_TrackID 1;
BA_ "GenSigSendType" SG_ 3221225472 P2A_L_lat_rel 1;
BA_ "GenSigSendType" SG_ 3221225472 P2A_V_long_obj 1;
BA_ "GenSigSendType" SG_ 3221225472 P2A_A_long_obj 1;
BA_ "GenSigSendType" SG_ 3221225472 P2A_L_long_rel 1;
BA_ "GenSigStartValue" SG_ 3221225472 P2A_L_long_rel 3000;
BA_ "GenSigSendType" SG_ 3221225472 P2A_TrackID 1;
BA_ "GenSigSendType" SG_ 3221225472 P1B_Age 1;
BA_ "GenSigSendType" SG_ 3221225472 P1B_V_lat_obj 1;
BA_ "GenSigSendType" SG_ 3221225472 P1B_FcwConfidence 1;
BA_ "GenSigSendType" SG_ 3221225472 P1B_CmbbPrimaryConfidence 1;
BA_ "GenSigSendType" SG_ 3221225472 P1B_Status 1;
BA_ "GenSigVtName" SG_ 3221225472 P1B_Status "VtSig_P1B_Status";
BA_ "GenSigVtEn" SG_ 3221225472 P1B_Status "TRUE";
BA_ "GenSigSendType" SG_ 3221225472 P1B_A_lat_obj 1;
BA_ "GenSigStartValue" SG_ 289 SPP_POLY_COEFF_A3 32766.9999997451;
BA_ "GenSigStartValue" SG_ 289 SPP_POLY_COEFF_A2 32767.000000512;
BA_ "GenSigStartValue" SG_ 289 SPP_POLY_COEFF_A1 32767.000000512;
BA_ "GenSigStartValue" SG_ 289 SPP_POLY_COEFF_A0 32768;
BA_ "GenSigStartValue" SG_ 274 LLM_A3 32766.9999997451;
BA_ "GenSigStartValue" SG_ 274 LLM_A2 32767.000000512;
BA_ "GenSigStartValue" SG_ 274 LLM_A1 32767.000000512;
BA_ "GenSigStartValue" SG_ 274 LLM_A0 32768;
BA_ "GenSigStartValue" SG_ 280 RLM_A3 32766.9999997451;
BA_ "GenSigStartValue" SG_ 280 RLM_A2 32767.000000512;
BA_ "GenSigStartValue" SG_ 280 RLM_A1 32767.000000512;
BA_ "GenSigStartValue" SG_ 280 RLM_A0 32768;
BA_ "GenSigStartValue" SG_ 277 PO_lat_pos 2048;
BA_ "GenSigStartValue" SG_ 277 PO_corrCoeff 256;
BA_ "GenSigStartValue" SG_ 278 PO_A3 32766.9999997451;
BA_ "GenSigStartValue" SG_ 278 PO_A2 32767.000000512;
BA_ "GenSigStartValue" SG_ 278 PO_A1 32767.000000512;
BA_ "GenSigStartValue" SG_ 278 PO_A0 32768;
VAL_ 3221225472 VIS_TSR_SCENE_STATUS_1 1 "open" 0 "closed" ;
VAL_ 3221225472 VIS_TSR_LANE_CHANGE 2 "lane change right" 1 "lane change left" 0 "no lane change detected" ;
VAL_ 3221225472 VIS_TSR_ROAD_CLASS 4 "motorway" 3 "expressway" 2 "outside a city" 1 "inside a city" 0 "unknown" ;
VAL_ 3221225472 VIS_TSR_SPEED_UNIT 2 "mph" 1 "kph" 0 "unknown" ;
VAL_ 3221225472 VIS_TSR_TRAFFIC_STYLE 1 "left hand driving" 0 "right hand driving" ;
VAL_ 3221225472 VIS_AHBC_DARK_ONCOMING_LANE 1 "not dark" 0 "dark" ;
VAL_ 3221225472 VIS_AHBC_CLEAR_FIELD_OF_VIEW 2 "clear field of view" 1 "no clear field of view" 0 "unknown" ;
VAL_ 3221225472 VIS_AHBC_STRUCT_SEPARATION_DET 4 "unknown/alternating separation" 3 "separation covering cars complet" 2 "separation covering cars partly" 1 "separation covering headlamps" 0 "no structural separation" ;
VAL_ 3221225472 VIS_AHBC_DAY_TIME_STATUS 3 "tunnel" 2 "night" 1 "twilight" 0 "day" ;
VAL_ 3221225472 VIS_AHBC_FOG_DETECTION 1 "fog" 0 "no fog" ;
VAL_ 3221225472 VIS_AHBC_HIGHWAY_DETECTION 1 "autobahn/highway" 0 "no autobahn/highway" ;
VAL_ 3221225472 VIS_AHBC_URBAN_AREA_DETECTION 2 "city" 1 "subdivision" 0 "no urban area" ;
VAL_ 3221225472 VIS_AHBC_TRAFFIC_STYLE_DETECTION 1 "left hand traffic" 0 "right hand traffic" ;
VAL_ 3221225472 VIS_AHBC_OBJ_10_TYPE 5 "truck cabin top lights" 4 "pair of tail-lamps" 3 "pair of headlamps" 2 "tail-lamp" 1 "headlamp" 0 "none" ;
VAL_ 3221225472 VIS_AHBC_OBJ_10_DISTANCE 15 ">1000m" 14 ">800m - 1000m" 13 ">700m - 800m" 12 ">600m - 700m" 11 ">500m - 600m" 10 ">400m - 500m" 9 ">300m - 400m" 8 ">200m - 300m" 7 ">175m - 200m" 6 ">150m - 175m" 5 ">125m - 150m" 4 ">100m - 125m" 3 ">75m - 100m" 2 ">50m - 75m" 1 ">25m - 50m" 0 "0m - 25m" ;
VAL_ 3221225472 VIS_AHBC_OBJ_09_TYPE 5 "truck cabin top lights" 4 "pair of tail-lamps" 3 "pair of headlamps" 2 "tail-lamp" 1 "headlamp" 0 "none" ;
VAL_ 3221225472 VIS_AHBC_OBJ_09_DISTANCE 15 ">1000m" 14 ">800m - 1000m" 13 ">700m - 800m" 12 ">600m - 700m" 11 ">500m - 600m" 10 ">400m - 500m" 9 ">300m - 400m" 8 ">200m - 300m" 7 ">175m - 200m" 6 ">150m - 175m" 5 ">125m - 150m" 4 ">100m - 125m" 3 ">75m - 100m" 2 ">50m - 75m" 1 ">25m - 50m" 0 "0m - 25m" ;
VAL_ 3221225472 VIS_AHBC_OBJ_08_TYPE 5 "truck cabin top lights" 4 "pair of tail-lamps" 3 "pair of headlamps" 2 "tail-lamp" 1 "headlamp" 0 "none" ;
VAL_ 3221225472 VIS_AHBC_OBJ_08_DISTANCE 15 ">1000m" 14 ">800m - 1000m" 13 ">700m - 800m" 12 ">600m - 700m" 11 ">500m - 600m" 10 ">400m - 500m" 9 ">300m - 400m" 8 ">200m - 300m" 7 ">175m - 200m" 6 ">150m - 175m" 5 ">125m - 150m" 4 ">100m - 125m" 3 ">75m - 100m" 2 ">50m - 75m" 1 ">25m - 50m" 0 "0m - 25m" ;
VAL_ 3221225472 VIS_AHBC_OBJ_07_TYPE 5 "truck cabin top lights" 4 "pair of tail-lamps" 3 "pair of headlamps" 2 "tail-lamp" 1 "headlamp" 0 "none" ;
VAL_ 3221225472 VIS_AHBC_OBJ_07_DISTANCE 15 ">1000m" 14 ">800m - 1000m" 13 ">700m - 800m" 12 ">600m - 700m" 11 ">500m - 600m" 10 ">400m - 500m" 9 ">300m - 400m" 8 ">200m - 300m" 7 ">175m - 200m" 6 ">150m - 175m" 5 ">125m - 150m" 4 ">100m - 125m" 3 ">75m - 100m" 2 ">50m - 75m" 1 ">25m - 50m" 0 "0m - 25m" ;
VAL_ 3221225472 VIS_AHBC_OBJ_06_TYPE 5 "truck cabin top lights" 4 "pair of tail-lamps" 3 "pair of headlamps" 2 "tail-lamp" 1 "headlamp" 0 "none" ;
VAL_ 3221225472 VIS_AHBC_OBJ_06_DISTANCE 15 ">1000m" 14 ">800m - 1000m" 13 ">700m - 800m" 12 ">600m - 700m" 11 ">500m - 600m" 10 ">400m - 500m" 9 ">300m - 400m" 8 ">200m - 300m" 7 ">175m - 200m" 6 ">150m - 175m" 5 ">125m - 150m" 4 ">100m - 125m" 3 ">75m - 100m" 2 ">50m - 75m" 1 ">25m - 50m" 0 "0m - 25m" ;
VAL_ 3221225472 VIS_AHBC_OBJ_05_TYPE 5 "truck cabin top lights" 4 "pair of tail-lamps" 3 "pair of headlamps" 2 "tail-lamp" 1 "headlamp" 0 "none" ;
VAL_ 3221225472 VIS_AHBC_OBJ_05_DISTANCE 15 ">1000m" 14 ">800m - 1000m" 13 ">700m - 800m" 12 ">600m - 700m" 11 ">500m - 600m" 10 ">400m - 500m" 9 ">300m - 400m" 8 ">200m - 300m" 7 ">175m - 200m" 6 ">150m - 175m" 5 ">125m - 150m" 4 ">100m - 125m" 3 ">75m - 100m" 2 ">50m - 75m" 1 ">25m - 50m" 0 "0m - 25m" ;
VAL_ 3221225472 VIS_AHBC_OBJ_04_TYPE 5 "truck cabin top lights" 4 "pair of tail-lamps" 3 "pair of headlamps" 2 "tail-lamp" 1 "headlamp" 0 "none" ;
VAL_ 3221225472 VIS_AHBC_OBJ_04_DISTANCE 15 ">1000m" 14 ">800m - 1000m" 13 ">700m - 800m" 12 ">600m - 700m" 11 ">500m - 600m" 10 ">400m - 500m" 9 ">300m - 400m" 8 ">200m - 300m" 7 ">175m - 200m" 6 ">150m - 175m" 5 ">125m - 150m" 4 ">100m - 125m" 3 ">75m - 100m" 2 ">50m - 75m" 1 ">25m - 50m" 0 "0m - 25m" ;
VAL_ 3221225472 VIS_AHBC_OBJ_03_TYPE 5 "truck cabin top lights" 4 "pair of tail-lamps" 3 "pair of headlamps" 2 "tail-lamp" 1 "headlamp" 0 "none" ;
VAL_ 3221225472 VIS_AHBC_OBJ_03_DISTANCE 15 ">1000m" 14 ">800m - 1000m" 13 ">700m - 800m" 12 ">600m - 700m" 11 ">500m - 600m" 10 ">400m - 500m" 9 ">300m - 400m" 8 ">200m - 300m" 7 ">175m - 200m" 6 ">150m - 175m" 5 ">125m - 150m" 4 ">100m - 125m" 3 ">75m - 100m" 2 ">50m - 75m" 1 ">25m - 50m" 0 "0m - 25m" ;
VAL_ 3221225472 VIS_AHBC_OBJ_02_TYPE 5 "truck cabin top lights" 4 "pair of tail-lamps" 3 "pair of headlamps" 2 "tail-lamp" 1 "headlamp" 0 "none" ;
VAL_ 3221225472 VIS_AHBC_OBJ_02_DISTANCE 15 ">1000m" 14 ">800m - 1000m" 13 ">700m - 800m" 12 ">600m - 700m" 11 ">500m - 600m" 10 ">400m - 500m" 9 ">300m - 400m" 8 ">200m - 300m" 7 ">175m - 200m" 6 ">150m - 175m" 5 ">125m - 150m" 4 ">100m - 125m" 3 ">75m - 100m" 2 ">50m - 75m" 1 ">25m - 50m" 0 "0m - 25m" ;
VAL_ 3221225472 VIS_AHBC_OBJ_01_TYPE 5 "truck cabin top lights" 4 "pair of tail-lamps" 3 "pair of headlamps" 2 "tail-lamp" 1 "headlamp" 0 "none" ;
VAL_ 3221225472 VIS_AHBC_OBJ_01_DISTANCE 15 ">1000m" 14 ">800m - 1000m" 13 ">700m - 800m" 12 ">600m - 700m" 11 ">500m - 600m" 10 ">400m - 500m" 9 ">300m - 400m" 8 ">200m - 300m" 7 ">175m - 200m" 6 ">150m - 175m" 5 ">125m - 150m" 4 ">100m - 125m" 3 ">75m - 100m" 2 ">50m - 75m" 1 ">25m - 50m" 0 "0m - 25m" ;
VAL_ 3221225472 VIS_LANE_RIGHT_PARALL_STATUS 7 "reserved" 6 "coasted measurement" 5 "updated measurement of geometry" 4 "reserved" 3 "reserved" 2 "new geometry detected" 1 "reserved" 0 "invalid" ;
VAL_ 3221225472 VIS_LANE_RIGHT_INDIVID_STATUS 7 "reserved" 6 "coasted measurement" 5 "updated measurement of geometry" 4 "reserved" 3 "reserved" 2 "new geometry detected" 1 "reserved" 0 "invalid" ;
VAL_ 3221225472 VIS_LANE_LEFT_PARALL_STATUS 7 "reserved" 6 "coasted measurement" 5 "updated measurement of geometry" 4 "reserved" 3 "reserved" 2 "new geometry detected" 1 "reserved" 0 "invalid" ;
VAL_ 3221225472 VIS_LANE_LEFT_INDIVID_STATUS 7 "reserved" 6 "coasted measurement" 5 "updated measurement of geometry" 4 "reserved" 3 "reserved" 2 "new geometry detected" 1 "reserved" 0 "invalid" ;
VAL_ 3221225472 VIS_CENTER_POLYNOMIAL_LINECASE 3 "left and right line" 2 "right line" 1 "left line" 0 "no line" ;
VAL_ 3221225472 VIS_CENTER_POLYNOMIAL_LANECONF 2 "good" 1 "middle" 0 "bad" ;
VAL_ 3221225472 VIS_OBS_TURN_INDICATOR_15 3 "unknown" 2 "right turn indicator active" 1 "left turn indicator active" 0 "no turn indicator active" ;
VAL_ 3221225472 VIS_OBS_TURN_INDICATOR_14 3 "unknown" 2 "right turn indicator active" 1 "left turn indicator active" 0 "no turn indicator active" ;
VAL_ 3221225472 VIS_OBS_TURN_INDICATOR_13 3 "unknown" 2 "right turn indicator active" 1 "left turn indicator active" 0 "no turn indicator active" ;
VAL_ 3221225472 VIS_OBS_TURN_INDICATOR_12 3 "unknown" 2 "right turn indicator active" 1 "left turn indicator active" 0 "no turn indicator active" ;
VAL_ 3221225472 VIS_OBS_TURN_INDICATOR_11 3 "unknown" 2 "right turn indicator active" 1 "left turn indicator active" 0 "no turn indicator active" ;
VAL_ 3221225472 VIS_OBS_TURN_INDICATOR_10 3 "unknown" 2 "right turn indicator active" 1 "left turn indicator active" 0 "no turn indicator active" ;
VAL_ 3221225472 VIS_OBS_TURN_INDICATOR_09 3 "unknown" 2 "right turn indicator active" 1 "left turn indicator active" 0 "no turn indicator active" ;
VAL_ 3221225472 VIS_OBS_TURN_INDICATOR_08 3 "unknown" 2 "right turn indicator active" 1 "left turn indicator active" 0 "no turn indicator active" ;
VAL_ 3221225472 VIS_OBS_TURN_INDICATOR_07 3 "unknown" 2 "right turn indicator active" 1 "left turn indicator active" 0 "no turn indicator active" ;
VAL_ 3221225472 VIS_OBS_TURN_INDICATOR_06 3 "unknown" 2 "right turn indicator active" 1 "left turn indicator active" 0 "no turn indicator active" ;
VAL_ 3221225472 VIS_OBS_TURN_INDICATOR_05 3 "unknown" 2 "right turn indicator active" 1 "left turn indicator active" 0 "no turn indicator active" ;
VAL_ 3221225472 VIS_OBS_TURN_INDICATOR_04 3 "unknown" 2 "right turn indicator active" 1 "left turn indicator active" 0 "no turn indicator active" ;
VAL_ 3221225472 VIS_OBS_TURN_INDICATOR_03 3 "unknown" 2 "right turn indicator active" 1 "left turn indicator active" 0 "no turn indicator active" ;
VAL_ 3221225472 VIS_OBS_TURN_INDICATOR_02 3 "unknown" 2 "right turn indicator active" 1 "left turn indicator active" 0 "no turn indicator active" ;
VAL_ 3221225472 VIS_OBS_PED_WAIST_UP_15 1 "false" 0 "true" ;
VAL_ 3221225472 VIS_OBS_PED_WAIST_UP_14 1 "false" 0 "true" ;
VAL_ 3221225472 VIS_OBS_PED_WAIST_UP_13 1 "false" 0 "true" ;
VAL_ 3221225472 VIS_OBS_PED_WAIST_UP_12 1 "false" 0 "true" ;
VAL_ 3221225472 VIS_OBS_PED_WAIST_UP_11 1 "false" 0 "true" ;
VAL_ 3221225472 VIS_OBS_PED_WAIST_UP_10 1 "false" 0 "true" ;
VAL_ 3221225472 VIS_OBS_PED_WAIST_UP_09 1 "false" 0 "true" ;
VAL_ 3221225472 VIS_OBS_PED_WAIST_UP_08 1 "false" 0 "true" ;
VAL_ 3221225472 VIS_OBS_PED_WAIST_UP_07 1 "false" 0 "true" ;
VAL_ 3221225472 VIS_OBS_PED_WAIST_UP_06 1 "false" 0 "true" ;
VAL_ 3221225472 VIS_OBS_PED_WAIST_UP_05 1 "false" 0 "true" ;
VAL_ 3221225472 VIS_OBS_PED_WAIST_UP_04 1 "false" 0 "true" ;
VAL_ 3221225472 VIS_OBS_PED_WAIST_UP_03 1 "false" 0 "true" ;
VAL_ 3221225472 VIS_OBS_PED_WAIST_UP_02 1 "false" 0 "true" ;
VAL_ 3221225472 VIS_OBS_CLASSIFICATION_15 10 "unidentified vehicle" 9 "bicycle" 8 "general on-road object" 7 "animal" 6 "reserved" 5 "reserved" 4 "pedestrian" 3 "truck" 2 "motorcycle" 1 "car" 0 "undetermined" ;
VAL_ 3221225472 VIS_OBS_CLASSIFICATION_14 10 "unidentified vehicle" 9 "bicycle" 8 "general on-road object" 7 "animal" 6 "reserved" 5 "reserved" 4 "pedestrian" 3 "truck" 2 "motorcycle" 1 "car" 0 "undetermined" ;
VAL_ 3221225472 VIS_OBS_CLASSIFICATION_13 10 "unidentified vehicle" 9 "bicycle" 8 "general on-road object" 7 "animal" 6 "reserved" 5 "reserved" 4 "pedestrian" 3 "truck" 2 "motorcycle" 1 "car" 0 "undetermined" ;
VAL_ 3221225472 VIS_OBS_CLASSIFICATION_12 10 "unidentified vehicle" 9 "bicycle" 8 "general on-road object" 7 "animal" 6 "reserved" 5 "reserved" 4 "pedestrian" 3 "truck" 2 "motorcycle" 1 "car" 0 "undetermined" ;
VAL_ 3221225472 VIS_OBS_CLASSIFICATION_11 10 "unidentified vehicle" 9 "bicycle" 8 "general on-road object" 7 "animal" 6 "reserved" 5 "reserved" 4 "pedestrian" 3 "truck" 2 "motorcycle" 1 "car" 0 "undetermined" ;
VAL_ 3221225472 VIS_OBS_CLASSIFICATION_10 10 "unidentified vehicle" 9 "bicycle" 8 "general on-road object" 7 "animal" 6 "reserved" 5 "reserved" 4 "pedestrian" 3 "truck" 2 "motorcycle" 1 "car" 0 "undetermined" ;
VAL_ 3221225472 VIS_OBS_CLASSIFICATION_09 10 "unidentified vehicle" 9 "bicycle" 8 "general on-road object" 7 "animal" 6 "reserved" 5 "reserved" 4 "pedestrian" 3 "truck" 2 "motorcycle" 1 "car" 0 "undetermined" ;
VAL_ 3221225472 VIS_OBS_CLASSIFICATION_08 10 "unidentified vehicle" 9 "bicycle" 8 "general on-road object" 7 "animal" 6 "reserved" 5 "reserved" 4 "pedestrian" 3 "truck" 2 "motorcycle" 1 "car" 0 "undetermined" ;
VAL_ 3221225472 VIS_OBS_CLASSIFICATION_07 10 "unidentified vehicle" 9 "bicycle" 8 "general on-road object" 7 "animal" 6 "reserved" 5 "reserved" 4 "pedestrian" 3 "truck" 2 "motorcycle" 1 "car" 0 "undetermined" ;
VAL_ 3221225472 VIS_OBS_CLASSIFICATION_06 10 "unidentified vehicle" 9 "bicycle" 8 "general on-road object" 7 "animal" 6 "reserved" 5 "reserved" 4 "pedestrian" 3 "truck" 2 "motorcycle" 1 "car" 0 "undetermined" ;
VAL_ 3221225472 VIS_OBS_CLASSIFICATION_05 10 "unidentified vehicle" 9 "bicycle" 8 "general on-road object" 7 "animal" 6 "reserved" 5 "reserved" 4 "pedestrian" 3 "truck" 2 "motorcycle" 1 "car" 0 "undetermined" ;
VAL_ 3221225472 VIS_OBS_CLASSIFICATION_04 10 "unidentified vehicle" 9 "bicycle" 8 "general on-road object" 7 "animal" 6 "reserved" 5 "reserved" 4 "pedestrian" 3 "truck" 2 "motorcycle" 1 "car" 0 "undetermined" ;
VAL_ 3221225472 VIS_OBS_CLASSIFICATION_03 10 "unidentified vehicle" 9 "bicycle" 8 "general on-road object" 7 "animal" 6 "reserved" 5 "reserved" 4 "pedestrian" 3 "truck" 2 "motorcycle" 1 "car" 0 "undetermined" ;
VAL_ 3221225472 VIS_OBS_CLASSIFICATION_02 10 "unidentified vehicle" 9 "bicycle" 8 "general on-road object" 7 "animal" 6 "reserved" 5 "reserved" 4 "pedestrian" 3 "truck" 2 "motorcycle" 1 "car" 0 "undetermined" ;
VAL_ 3221225472 VIS_OBS_BRAKE_LIGHT_INDIC_15 2 "brake light is steady active" 1 "no brake light is active" 0 "unknown" ;
VAL_ 3221225472 VIS_OBS_BRAKE_LIGHT_INDIC_14 2 "brake light is steady active" 1 "no brake light is active" 0 "unknown" ;
VAL_ 3221225472 VIS_OBS_BRAKE_LIGHT_INDIC_13 2 "brake light is steady active" 1 "no brake light is active" 0 "unknown" ;
VAL_ 3221225472 VIS_OBS_BRAKE_LIGHT_INDIC_12 2 "brake light is steady active" 1 "no brake light is active" 0 "unknown" ;
VAL_ 3221225472 VIS_OBS_BRAKE_LIGHT_INDIC_11 2 "brake light is steady active" 1 "no brake light is active" 0 "unknown" ;
VAL_ 3221225472 VIS_OBS_BRAKE_LIGHT_INDIC_10 2 "brake light is steady active" 1 "no brake light is active" 0 "unknown" ;
VAL_ 3221225472 VIS_OBS_BRAKE_LIGHT_INDIC_09 2 "brake light is steady active" 1 "no brake light is active" 0 "unknown" ;
VAL_ 3221225472 VIS_OBS_BRAKE_LIGHT_INDIC_08 2 "brake light is steady active" 1 "no brake light is active" 0 "unknown" ;
VAL_ 3221225472 VIS_OBS_BRAKE_LIGHT_INDIC_07 2 "brake light is steady active" 1 "no brake light is active" 0 "unknown" ;
VAL_ 3221225472 VIS_OBS_BRAKE_LIGHT_INDIC_06 2 "brake light is steady active" 1 "no brake light is active" 0 "unknown" ;
VAL_ 3221225472 VIS_OBS_BRAKE_LIGHT_INDIC_05 2 "brake light is steady active" 1 "no brake light is active" 0 "unknown" ;
VAL_ 3221225472 VIS_OBS_BRAKE_LIGHT_INDIC_04 2 "brake light is steady active" 1 "no brake light is active" 0 "unknown" ;
VAL_ 3221225472 VIS_OBS_BRAKE_LIGHT_INDIC_03 2 "brake light is steady active" 1 "no brake light is active" 0 "unknown" ;
VAL_ 3221225472 VIS_OBS_BRAKE_LIGHT_INDIC_02 2 "brake light is steady active" 1 "no brake light is active" 0 "unknown" ;
VAL_ 3221225472 VIS_OBS_TURN_INDICATOR_01 3 "unknown" 2 "right turn indicator active" 1 "left turn indicator active" 0 "no turn indicator active" ;
VAL_ 3221225472 VIS_OBS_PED_WAIST_UP_01 1 "false" 0 "true" ;
VAL_ 3221225472 VIS_OBS_CLASSIFICATION_01 10 "unidentified vehicle" 9 "bicycle" 8 "general on-road object" 7 "animal" 6 "reserved" 5 "reserved" 4 "pedestrian" 3 "truck" 2 "motorcycle" 1 "car" 0 "undetermined" ;
VAL_ 3221225472 VIS_OBS_BRAKE_LIGHT_INDIC_01 2 "brake light is steady active" 1 "no brake light is active" 0 "unknown" ;
VAL_ 3221225472 VIS_LANE_RIGHT_PA_MARKER_COLOR 3 "blue" 2 "white" 1 "yellow" 0 "unknown" ;
VAL_ 3221225472 VIS_LANE_RIGHT_IN_MARKER_COLOR 3 "blue" 2 "white" 1 "yellow" 0 "unknown" ;
VAL_ 3221225472 VIS_LANE_LEFT_PA_MARKER_COLOR 3 "blue" 2 "white" 1 "yellow" 0 "unknown" ;
VAL_ 3221225472 VIS_LANE_LEFT_IN_MARKER_COLOR 3 "blue" 2 "white" 1 "yellow" 0 "unknown" ;
VAL_ 3221225472 SIGN_8_VIS_TSR_RELEVANT_DECISION 7 "other filter reason" 6 "internal sign contradiction" 5 "far irrelevant sign" 4 "sign on turn" 3 "parallel road signs" 2 "lane assignment sign" 1 "highway exit" 0 "relevant sign" ;
VAL_ 3221225472 SIGN_8_VIS_TSR_LOCATION 1 "above current road" 0 "unknown" ;
VAL_ 3221225472 SIGN_8_VIS_TSR_SUPPL_TYPE_1ST 24 "Beschreibung für den Wert '0x18'" 23 "distance for AND in" 22 "ice" 21 "end" 20 "bend right" 19 "bend left" 18 "arrow right" 17 "arrow left" 16 "tractor" 15 "truck" 14 "trailer" 13 "zone" 12 "night" 11 "fog" 10 "snow rain" 9 "snow" 8 "rain cloud" 7 "rain" 6 "school" 5 "weight" 4 "time" 3 "distance arrow" 2 "distance" 1 "generic" 0 "none" ;
VAL_ 3221225472 SIGN_8_VIS_TSR_STATUS 7 "reserved" 6 "reserved" 5 "updated" 4 "reserved" 3 "reserved" 2 "new" 1 "reserved" 0 "invalid" ;
VAL_ 3221225472 SIGN_8_VIS_TSR_SUPPL_TYPE_2ND 27 "end of all" 26 "round about" 25 "no overtaking trucks end" 24 "no overtaking trucks start" 23 "reserved (not used)" 22 "reserved (not used)" 21 "reserved (not used)" 20 "reserved (not used)" 19 "advisory speed limit start" 18 "no entrance" 17 "no overtaking end" 16 "no overtaking start" 15 "stop" 14 "low speed area end" 13 "low speed area start" 12 "town end" 11 "town start" 10 "reserved (not used" 9 "reserved (not used)" 8 "freeway end" 7 "freeway start" 6 "hightway end" 5 "highway start" 4 "reserved (not used)" 3 "reserved (not used)" 2 "speed limit end" 1 "speed limit start" 0 "unknown" ;
VAL_ 3221225472 SIGN_8_VIS_TSR_ELECTRONIC_SIGN 1 "electronic sign" 0 "no electronic sign" ;
VAL_ 3221225472 SIGN_8_VIS_TSR_TYPE 27 "end of all" 26 "round about" 25 "no overtaking trucks end" 24 "no overtaking trucks start" 23 "reserved (not used)" 22 "reserved (not used)" 21 "reserved (not used)" 20 "reserved (not used)" 19 "advisory speed limit start" 18 "no entrance" 17 "no overtaking end" 16 "no overtaking start" 15 "stop" 14 "low speed area end" 13 "low speed area start" 12 "town end" 11 "town start" 10 "reserved (not used)" 9 "reserved (not used)" 8 "freeway end" 7 "freeway start" 6 "highway end" 5 "highway start" 4 "reserved (not used)" 3 "reserved (not used)" 2 "speed limit end" 1 "speed limit start" 0 "start" ;
VAL_ 3221225472 SIGN_7_VIS_TSR_RELEVANT_DECISION 7 "other filter reason" 6 "internal sign contradiction" 5 "far irrelevant sign" 4 "sign on turn" 3 "parallel road signs" 2 "lane assignment sign" 1 "highway exit" 0 "relevant sign" ;
VAL_ 3221225472 SIGN_7_VIS_TSR_LOCATION 1 "above current road" 0 "unknown" ;
VAL_ 3221225472 SIGN_7_VIS_TSR_SUPPL_TYPE_1ST 24 "Beschreibung für den Wert '0x18'" 23 "distance for AND in" 22 "ice" 21 "end" 20 "bend right" 19 "bend left" 18 "arrow right" 17 "arrow left" 16 "tractor" 15 "truck" 14 "trailer" 13 "zone" 12 "night" 11 "fog" 10 "snow rain" 9 "snow" 8 "rain cloud" 7 "rain" 6 "school" 5 "weight" 4 "time" 3 "distance arrow" 2 "distance" 1 "generic" 0 "none" ;
VAL_ 3221225472 SIGN_7_VIS_TSR_STATUS 7 "reserved" 6 "reserved" 5 "updated" 4 "reserved" 3 "reserved" 2 "new" 1 "reserved" 0 "invalid" ;
VAL_ 3221225472 SIGN_7_VIS_TSR_SUPPL_TYPE_2ND 27 "end of all" 26 "round about" 25 "no overtaking trucks end" 24 "no overtaking trucks start" 23 "reserved (not used)" 22 "reserved (not used)" 21 "reserved (not used)" 20 "reserved (not used)" 19 "advisory speed limit start" 18 "no entrance" 17 "no overtaking end" 16 "no overtaking start" 15 "stop" 14 "low speed area end" 13 "low speed area start" 12 "town end" 11 "town start" 10 "reserved (not used" 9 "reserved (not used)" 8 "freeway end" 7 "freeway start" 6 "hightway end" 5 "highway start" 4 "reserved (not used)" 3 "reserved (not used)" 2 "speed limit end" 1 "speed limit start" 0 "unknown" ;
VAL_ 3221225472 SIGN_7_VIS_TSR_ELECTRONIC_SIGN 1 "electronic sign" 0 "no electronic sign" ;
VAL_ 3221225472 SIGN_7_VIS_TSR_TYPE 27 "end of all" 26 "round about" 25 "no overtaking trucks end" 24 "no overtaking trucks start" 23 "reserved (not used)" 22 "reserved (not used)" 21 "reserved (not used)" 20 "reserved (not used)" 19 "advisory speed limit start" 18 "no entrance" 17 "no overtaking end" 16 "no overtaking start" 15 "stop" 14 "low speed area end" 13 "low speed area start" 12 "town end" 11 "town start" 10 "reserved (not used)" 9 "reserved (not used)" 8 "freeway end" 7 "freeway start" 6 "highway end" 5 "highway start" 4 "reserved (not used)" 3 "reserved (not used)" 2 "speed limit end" 1 "speed limit start" 0 "start" ;
VAL_ 3221225472 SIGN_6_VIS_TSR_RELEVANT_DECISION 7 "other filter reason" 6 "internal sign contradiction" 5 "far irrelevant sign" 4 "sign on turn" 3 "parallel road signs" 2 "lane assignment sign" 1 "highway exit" 0 "relevant sign" ;
VAL_ 3221225472 SIGN_6_VIS_TSR_LOCATION 1 "above current road" 0 "unknown" ;
VAL_ 3221225472 SIGN_6_VIS_TSR_SUPPL_TYPE_1ST 24 "Beschreibung für den Wert '0x18'" 23 "distance for AND in" 22 "ice" 21 "end" 20 "bend right" 19 "bend left" 18 "arrow right" 17 "arrow left" 16 "tractor" 15 "truck" 14 "trailer" 13 "zone" 12 "night" 11 "fog" 10 "snow rain" 9 "snow" 8 "rain cloud" 7 "rain" 6 "school" 5 "weight" 4 "time" 3 "distance arrow" 2 "distance" 1 "generic" 0 "none" ;
VAL_ 3221225472 SIGN_6_VIS_TSR_STATUS 7 "reserved" 6 "reserved" 5 "updated" 4 "reserved" 3 "reserved" 2 "new" 1 "reserved" 0 "invalid" ;
VAL_ 3221225472 SIGN_6_VIS_TSR_SUPPL_TYPE_2ND 27 "end of all" 26 "round about" 25 "no overtaking trucks end" 24 "no overtaking trucks start" 23 "reserved (not used)" 22 "reserved (not used)" 21 "reserved (not used)" 20 "reserved (not used)" 19 "advisory speed limit start" 18 "no entrance" 17 "no overtaking end" 16 "no overtaking start" 15 "stop" 14 "low speed area end" 13 "low speed area start" 12 "town end" 11 "town start" 10 "reserved (not used" 9 "reserved (not used)" 8 "freeway end" 7 "freeway start" 6 "hightway end" 5 "highway start" 4 "reserved (not used)" 3 "reserved (not used)" 2 "speed limit end" 1 "speed limit start" 0 "unknown" ;
VAL_ 3221225472 SIGN_6_VIS_TSR_ELECTRONIC_SIGN 1 "electronic sign" 0 "no electronic sign" ;
VAL_ 3221225472 SIGN_6_VIS_TSR_TYPE 27 "end of all" 26 "round about" 25 "no overtaking trucks end" 24 "no overtaking trucks start" 23 "reserved (not used)" 22 "reserved (not used)" 21 "reserved (not used)" 20 "reserved (not used)" 19 "advisory speed limit start" 18 "no entrance" 17 "no overtaking end" 16 "no overtaking start" 15 "stop" 14 "low speed area end" 13 "low speed area start" 12 "town end" 11 "town start" 10 "reserved (not used)" 9 "reserved (not used)" 8 "freeway end" 7 "freeway start" 6 "highway end" 5 "highway start" 4 "reserved (not used)" 3 "reserved (not used)" 2 "speed limit end" 1 "speed limit start" 0 "start" ;
VAL_ 3221225472 SIGN_5_VIS_TSR_RELEVANT_DECISION 7 "other filter reason" 6 "internal sign contradiction" 5 "far irrelevant sign" 4 "sign on turn" 3 "parallel road signs" 2 "lane assignment sign" 1 "highway exit" 0 "relevant sign" ;
VAL_ 3221225472 SIGN_5_VIS_TSR_LOCATION 1 "above current road" 0 "unknown" ;
VAL_ 3221225472 SIGN_5_VIS_TSR_SUPPL_TYPE_1ST 24 "Beschreibung für den Wert '0x18'" 23 "distance for AND in" 22 "ice" 21 "end" 20 "bend right" 19 "bend left" 18 "arrow right" 17 "arrow left" 16 "tractor" 15 "truck" 14 "trailer" 13 "zone" 12 "night" 11 "fog" 10 "snow rain" 9 "snow" 8 "rain cloud" 7 "rain" 6 "school" 5 "weight" 4 "time" 3 "distance arrow" 2 "distance" 1 "generic" 0 "none" ;
VAL_ 3221225472 SIGN_5_VIS_TSR_STATUS 7 "reserved" 6 "reserved" 5 "updated" 4 "reserved" 3 "reserved" 2 "new" 1 "reserved" 0 "invalid" ;
VAL_ 3221225472 SIGN_5_VIS_TSR_SUPPL_TYPE_2ND 27 "end of all" 26 "round about" 25 "no overtaking trucks end" 24 "no overtaking trucks start" 23 "reserved (not used)" 22 "reserved (not used)" 21 "reserved (not used)" 20 "reserved (not used)" 19 "advisory speed limit start" 18 "no entrance" 17 "no overtaking end" 16 "no overtaking start" 15 "stop" 14 "low speed area end" 13 "low speed area start" 12 "town end" 11 "town start" 10 "reserved (not used" 9 "reserved (not used)" 8 "freeway end" 7 "freeway start" 6 "hightway end" 5 "highway start" 4 "reserved (not used)" 3 "reserved (not used)" 2 "speed limit end" 1 "speed limit start" 0 "unknown" ;
VAL_ 3221225472 SIGN_5_VIS_TSR_ELECTRONIC_SIGN 1 "electronic sign" 0 "no electronic sign" ;
VAL_ 3221225472 SIGN_5_VIS_TSR_TYPE 27 "end of all" 26 "round about" 25 "no overtaking trucks end" 24 "no overtaking trucks start" 23 "reserved (not used)" 22 "reserved (not used)" 21 "reserved (not used)" 20 "reserved (not used)" 19 "advisory speed limit start" 18 "no entrance" 17 "no overtaking end" 16 "no overtaking start" 15 "stop" 14 "low speed area end" 13 "low speed area start" 12 "town end" 11 "town start" 10 "reserved (not used)" 9 "reserved (not used)" 8 "freeway end" 7 "freeway start" 6 "highway end" 5 "highway start" 4 "reserved (not used)" 3 "reserved (not used)" 2 "speed limit end" 1 "speed limit start" 0 "start" ;
VAL_ 3221225472 SIGN_4_VIS_TSR_RELEVANT_DECISION 7 "other filter reason" 6 "internal sign contradiction" 5 "far irrelevant sign" 4 "sign on turn" 3 "parallel road signs" 2 "lane assignment sign" 1 "highway exit" 0 "relevant sign" ;
VAL_ 3221225472 SIGN_4_VIS_TSR_LOCATION 1 "above current road" 0 "unknown" ;
VAL_ 3221225472 SIGN_4_VIS_TSR_SUPPL_TYPE_1ST 24 "Beschreibung für den Wert '0x18'" 23 "distance for AND in" 22 "ice" 21 "end" 20 "bend right" 19 "bend left" 18 "arrow right" 17 "arrow left" 16 "tractor" 15 "truck" 14 "trailer" 13 "zone" 12 "night" 11 "fog" 10 "snow rain" 9 "snow" 8 "rain cloud" 7 "rain" 6 "school" 5 "weight" 4 "time" 3 "distance arrow" 2 "distance" 1 "generic" 0 "none" ;
VAL_ 3221225472 SIGN_4_VIS_TSR_STATUS 7 "reserved" 6 "reserved" 5 "updated" 4 "reserved" 3 "reserved" 2 "new" 1 "reserved" 0 "invalid" ;
VAL_ 3221225472 SIGN_4_VIS_TSR_SUPPL_TYPE_2ND 27 "end of all" 26 "round about" 25 "no overtaking trucks end" 24 "no overtaking trucks start" 23 "reserved (not used)" 22 "reserved (not used)" 21 "reserved (not used)" 20 "reserved (not used)" 19 "advisory speed limit start" 18 "no entrance" 17 "no overtaking end" 16 "no overtaking start" 15 "stop" 14 "low speed area end" 13 "low speed area start" 12 "town end" 11 "town start" 10 "reserved (not used" 9 "reserved (not used)" 8 "freeway end" 7 "freeway start" 6 "hightway end" 5 "highway start" 4 "reserved (not used)" 3 "reserved (not used)" 2 "speed limit end" 1 "speed limit start" 0 "unknown" ;
VAL_ 3221225472 SIGN_4_VIS_TSR_ELECTRONIC_SIGN 1 "electronic sign" 0 "no electronic sign" ;
VAL_ 3221225472 SIGN_4_VIS_TSR_TYPE 27 "end of all" 26 "round about" 25 "no overtaking trucks end" 24 "no overtaking trucks start" 23 "reserved (not used)" 22 "reserved (not used)" 21 "reserved (not used)" 20 "reserved (not used)" 19 "advisory speed limit start" 18 "no entrance" 17 "no overtaking end" 16 "no overtaking start" 15 "stop" 14 "low speed area end" 13 "low speed area start" 12 "town end" 11 "town start" 10 "reserved (not used)" 9 "reserved (not used)" 8 "freeway end" 7 "freeway start" 6 "highway end" 5 "highway start" 4 "reserved (not used)" 3 "reserved (not used)" 2 "speed limit end" 1 "speed limit start" 0 "start" ;
VAL_ 3221225472 SIGN_3_VIS_TSR_RELEVANT_DECISION 7 "other filter reason" 6 "internal sign contradiction" 5 "far irrelevant sign" 4 "sign on turn" 3 "parallel road signs" 2 "lane assignment sign" 1 "highway exit" 0 "relevant sign" ;
VAL_ 3221225472 SIGN_3_VIS_TSR_LOCATION 1 "above current road" 0 "unknown" ;
VAL_ 3221225472 SIGN_3_VIS_TSR_SUPPL_TYPE_1ST 24 "Beschreibung für den Wert '0x18'" 23 "distance for AND in" 22 "ice" 21 "end" 20 "bend right" 19 "bend left" 18 "arrow right" 17 "arrow left" 16 "tractor" 15 "truck" 14 "trailer" 13 "zone" 12 "night" 11 "fog" 10 "snow rain" 9 "snow" 8 "rain cloud" 7 "rain" 6 "school" 5 "weight" 4 "time" 3 "distance arrow" 2 "distance" 1 "generic" 0 "none" ;
VAL_ 3221225472 SIGN_3_VIS_TSR_STATUS 7 "reserved" 6 "reserved" 5 "updated" 4 "reserved" 3 "reserved" 2 "new" 1 "reserved" 0 "invalid" ;
VAL_ 3221225472 SIGN_3_VIS_TSR_SUPPL_TYPE_2ND 27 "end of all" 26 "round about" 25 "no overtaking trucks end" 24 "no overtaking trucks start" 23 "reserved (not used)" 22 "reserved (not used)" 21 "reserved (not used)" 20 "reserved (not used)" 19 "advisory speed limit start" 18 "no entrance" 17 "no overtaking end" 16 "no overtaking start" 15 "stop" 14 "low speed area end" 13 "low speed area start" 12 "town end" 11 "town start" 10 "reserved (not used" 9 "reserved (not used)" 8 "freeway end" 7 "freeway start" 6 "hightway end" 5 "highway start" 4 "reserved (not used)" 3 "reserved (not used)" 2 "speed limit end" 1 "speed limit start" 0 "unknown" ;
VAL_ 3221225472 SIGN_3_VIS_TSR_ELECTRONIC_SIGN 1 "electronic sign" 0 "no electronic sign" ;
VAL_ 3221225472 SIGN_3_VIS_TSR_TYPE 27 "end of all" 26 "round about" 25 "no overtaking trucks end" 24 "no overtaking trucks start" 23 "reserved (not used)" 22 "reserved (not used)" 21 "reserved (not used)" 20 "reserved (not used)" 19 "advisory speed limit start" 18 "no entrance" 17 "no overtaking end" 16 "no overtaking start" 15 "stop" 14 "low speed area end" 13 "low speed area start" 12 "town end" 11 "town start" 10 "reserved (not used)" 9 "reserved (not used)" 8 "freeway end" 7 "freeway start" 6 "highway end" 5 "highway start" 4 "reserved (not used)" 3 "reserved (not used)" 2 "speed limit end" 1 "speed limit start" 0 "start" ;
VAL_ 3221225472 SIGN_2_VIS_TSR_RELEVANT_DECISION 7 "other filter reason" 6 "internal sign contradiction" 5 "far irrelevant sign" 4 "sign on turn" 3 "parallel road signs" 2 "lane assignment sign" 1 "highway exit" 0 "relevant sign" ;
VAL_ 3221225472 SIGN_2_VIS_TSR_LOCATION 1 "above current road" 0 "unknown" ;
VAL_ 3221225472 SIGN_2_VIS_TSR_SUPPL_TYPE_1ST 24 "Beschreibung für den Wert '0x18'" 23 "distance for AND in" 22 "ice" 21 "end" 20 "bend right" 19 "bend left" 18 "arrow right" 17 "arrow left" 16 "tractor" 15 "truck" 14 "trailer" 13 "zone" 12 "night" 11 "fog" 10 "snow rain" 9 "snow" 8 "rain cloud" 7 "rain" 6 "school" 5 "weight" 4 "time" 3 "distance arrow" 2 "distance" 1 "generic" 0 "none" ;
VAL_ 3221225472 SIGN_2_VIS_TSR_STATUS 7 "reserved" 6 "reserved" 5 "updated" 4 "reserved" 3 "reserved" 2 "new" 1 "reserved" 0 "invalid" ;
VAL_ 3221225472 SIGN_2_VIS_TSR_SUPPL_TYPE_2ND 27 "end of all" 26 "round about" 25 "no overtaking trucks end" 24 "no overtaking trucks start" 23 "reserved (not used)" 22 "reserved (not used)" 21 "reserved (not used)" 20 "reserved (not used)" 19 "advisory speed limit start" 18 "no entrance" 17 "no overtaking end" 16 "no overtaking start" 15 "stop" 14 "low speed area end" 13 "low speed area start" 12 "town end" 11 "town start" 10 "reserved (not used" 9 "reserved (not used)" 8 "freeway end" 7 "freeway start" 6 "hightway end" 5 "highway start" 4 "reserved (not used)" 3 "reserved (not used)" 2 "speed limit end" 1 "speed limit start" 0 "unknown" ;
VAL_ 3221225472 SIGN_2_VIS_TSR_ELECTRONIC_SIGN 1 "electronic sign" 0 "no electronic sign" ;
VAL_ 3221225472 SIGN_2_VIS_TSR_TYPE 27 "end of all" 26 "round about" 25 "no overtaking trucks end" 24 "no overtaking trucks start" 23 "reserved (not used)" 22 "reserved (not used)" 21 "reserved (not used)" 20 "reserved (not used)" 19 "advisory speed limit start" 18 "no entrance" 17 "no overtaking end" 16 "no overtaking start" 15 "stop" 14 "low speed area end" 13 "low speed area start" 12 "town end" 11 "town start" 10 "reserved (not used)" 9 "reserved (not used)" 8 "freeway end" 7 "freeway start" 6 "highway end" 5 "highway start" 4 "reserved (not used)" 3 "reserved (not used)" 2 "speed limit end" 1 "speed limit start" 0 "start" ;
VAL_ 3221225472 SIGN_1_VIS_TSR_RELEVANT_DECISION 7 "other filter reason" 6 "internal sign contradiction" 5 "far irrelevant sign" 4 "sign on turn" 3 "parallel road signs" 2 "lane assignment sign" 1 "highway exit" 0 "relevant sign" ;
VAL_ 3221225472 SIGN_1_VIS_TSR_LOCATION 1 "above current road" 0 "unknown" ;
VAL_ 3221225472 SIGN_1_VIS_TSR_SUPPL_TYPE_1ST 24 "Beschreibung für den Wert '0x18'" 23 "distance for AND in" 22 "ice" 21 "end" 20 "bend right" 19 "bend left" 18 "arrow right" 17 "arrow left" 16 "tractor" 15 "truck" 14 "trailer" 13 "zone" 12 "night" 11 "fog" 10 "snow rain" 9 "snow" 8 "rain cloud" 7 "rain" 6 "school" 5 "weight" 4 "time" 3 "distance arrow" 2 "distance" 1 "generic" 0 "none" ;
VAL_ 3221225472 SIGN_1_VIS_TSR_STATUS 7 "reserved" 6 "reserved" 5 "updated" 4 "reserved" 3 "reserved" 2 "new" 1 "reserved" 0 "invalid" ;
VAL_ 3221225472 SIGN_1_VIS_TSR_SUPPL_TYPE_2ND 27 "end of all" 26 "round about" 25 "no overtaking trucks end" 24 "no overtaking trucks start" 23 "reserved (not used)" 22 "reserved (not used)" 21 "reserved (not used)" 20 "reserved (not used)" 19 "advisory speed limit start" 18 "no entrance" 17 "no overtaking end" 16 "no overtaking start" 15 "stop" 14 "low speed area end" 13 "low speed area start" 12 "town end" 11 "town start" 10 "reserved (not used" 9 "reserved (not used)" 8 "freeway end" 7 "freeway start" 6 "hightway end" 5 "highway start" 4 "reserved (not used)" 3 "reserved (not used)" 2 "speed limit end" 1 "speed limit start" 0 "unknown" ;
VAL_ 3221225472 SIGN_1_VIS_TSR_ELECTRONIC_SIGN 1 "electronic sign" 0 "no electronic sign" ;
VAL_ 3221225472 SIGN_1_VIS_TSR_TYPE 27 "end of all" 26 "round about" 25 "no overtaking trucks end" 24 "no overtaking trucks start" 23 "reserved (not used)" 22 "reserved (not used)" 21 "reserved (not used)" 20 "reserved (not used)" 19 "advisory speed limit start" 18 "no entrance" 17 "no overtaking end" 16 "no overtaking start" 15 "stop" 14 "low speed area end" 13 "low speed area start" 12 "town end" 11 "town start" 10 "reserved (not used)" 9 "reserved (not used)" 8 "freeway end" 7 "freeway start" 6 "highway end" 5 "highway start" 4 "reserved (not used)" 3 "reserved (not used)" 2 "speed limit end" 1 "speed limit start" 0 "start" ;
VAL_ 3221225472 VIS_FCW_SENS_LEVEL 2 "high" 1 "medium" 0 "low" ;
VAL_ 3221225472 VIS_FCW_NEAR_RNG_OBS_VIO 3 "not applicable" 2 "unused" 1 "violation" 0 "no violation" ;
VAL_ 3221225472 PAC_Object_class 10 "unidentified vehicle" 9 "bicycle" 8 "general on-road object" 7 "animal" 6 "tree" 5 "pole" 4 "pedestrian" 3 "truck" 2 "motorcycle" 1 "car" 0 "undetermined" ;
VAL_ 3221225472 P9C_Object_class 10 "unidentified vehicle" 9 "bicycle" 8 "general on-road object" 7 "animal" 6 "tree" 5 "pole" 4 "pedestrian" 3 "truck" 2 "motorcycle" 1 "car" 0 "undetermined" ;
VAL_ 3221225472 P8C_Object_class 10 "unidentified vehicle" 9 "bicycle" 8 "general on-road object" 7 "animal" 6 "tree" 5 "pole" 4 "pedestrian" 3 "truck" 2 "motorcycle" 1 "car" 0 "undetermined" ;
VAL_ 3221225472 P7C_Object_class 10 "unidentified vehicle" 9 "bicycle" 8 "general on-road object" 7 "animal" 6 "tree" 5 "pole" 4 "pedestrian" 3 "truck" 2 "motorcycle" 1 "car" 0 "undetermined" ;
VAL_ 3221225472 P6C_Object_class 10 "unidentified vehicle" 9 "bicycle" 8 "general on-road object" 7 "animal" 6 "tree" 5 "pole" 4 "pedestrian" 3 "truck" 2 "motorcycle" 1 "car" 0 "undetermined" ;
VAL_ 3221225472 P5C_Object_class 10 "unidentified vehicle" 9 "bicycle" 8 "general on-road object" 7 "animal" 6 "tree" 5 "pole" 4 "pedestrian" 3 "truck" 2 "motorcycle" 1 "car" 0 "undetermined" ;
VAL_ 3221225472 P4C_Object_class 10 "unidentified vehicle" 9 "bicycle" 8 "general on-road object" 7 "animal" 6 "tree" 5 "pole" 4 "pedestrian" 3 "truck" 2 "motorcycle" 1 "car" 0 "undetermined" ;
VAL_ 3221225472 P3C_Object_class 10 "unidentified vehicle" 9 "bicycle" 8 "general on-road object" 7 "animal" 6 "tree" 5 "pole" 4 "pedestrian" 3 "truck" 2 "motorcycle" 1 "car" 0 "undetermined" ;
VAL_ 3221225472 P2C_Object_class 10 "unidentified vehicle" 9 "bicycle" 8 "general on-road object" 7 "animal" 6 "tree" 5 "pole" 4 "pedestrian" 3 "truck" 2 "motorcycle" 1 "car" 0 "undetermined" ;
VAL_ 3221225472 PAB_Status 6 "coasted" 5 "updated" 4 "new updated" 3 "new coasted" 2 "new" 1 "merged" 0 "invalid" ;
VAL_ 3221225472 P9B_Status 6 "coasted" 5 "updated" 4 "new updated" 3 "new coasted" 2 "new" 1 "merged" 0 "invalid" ;
VAL_ 3221225472 P8B_Status 6 "coasted" 5 "updated" 4 "new updated" 3 "new coasted" 2 "new" 1 "merged" 0 "invalid" ;
VAL_ 3221225472 P7B_Status 6 "coasted" 5 "updated" 4 "new updated" 3 "new coasted" 2 "new" 1 "merged" 0 "invalid" ;
VAL_ 3221225472 P6B_Status 6 "coasted" 5 "updated" 4 "new updated" 3 "new coasted" 2 "new" 1 "merged" 0 "invalid" ;
VAL_ 3221225472 P5B_Status 6 "coasted" 5 "updated" 4 "new updated" 3 "new coasted" 2 "new" 1 "merged" 0 "invalid" ;
VAL_ 3221225472 P4B_Status 6 "coasted" 5 "updated" 4 "new updated" 3 "new coasted" 2 "new" 1 "merged" 0 "invalid" ;
VAL_ 3221225472 P3B_Status 6 "coasted" 5 "updated" 4 "new updated" 3 "new coasted" 2 "new" 1 "merged" 0 "invalid" ;
VAL_ 3221225472 P2B_Status 6 "coasted" 5 "updated" 4 "new updated" 3 "new coasted" 2 "new" 1 "merged" 0 "invalid" ;
VAL_ 3221225472 P1B_Status 6 "coasted" 5 "updated" 4 "new updated" 3 "new coasted" 2 "new" 1 "merged" 0 "invalid" ;
VAL_ 3221225472 LKA_Feature_diag 1 "Pass" 0 "Fault" ;
VAL_ 3221225472 ME_vision_fault 1 "Pass" 0 "Fault" ;
VAL_ 3221225472 ldp_LKAMode 8 "LKA_MODE_TRANSITION" 7 "LKA_MODE_STAGE2_RIGHT" 6 "LKA_MODE_STAGE2_LEFT" 5 "LKA_MODE_STAGE1_RIGHT" 4 "LKA_MODE_STAGE1_LEFT" 3 "LKA_MODE_ENABLED" 2 "LKA_MODE_STANDBY" 1 "LKA_MODE_OFF" 0 "LKA_MODE_FAIL" ;
VAL_ 2007 LatCtlRampType_Rq 3 "Immediately" 2 "Fast" 1 "Medium" 0 "Slow" ;
VAL_ 2007 TJA_Warn_Disp_Rq 3 "TJA_INFO_FAIL" 2 "TJA_INFO_CANCELLED" 1 "TJA_INFO_CANNOT_ACTIVATE" 0 "TJA_INFO_NO_DISP" ;
VAL_ 2007 TJA_Mode 15 "reserve" 14 "reserve" 13 "TJA_FAULT" 12 "TJA_RESM_RQ" 11 "TJA_DRV_CNCL" 10 "TJA_SYS_CNCL" 9 "TJA_TO_BRK" 8 "TJA_TO_NOACCL" 7 "TJA_LIM_TO" 6 "TJA_OVRD_LAT" 5 "TJA_OVRD_LONG" 4 "TJA_ACTIVECTRL" 3 "TJA_STANDBYLCKCHK" 2 "TJA_STANDBYENABLE" 1 "TJA_STANDBYDISABLE" 0 "TJA_OFF_MODE" ;
VAL_ 2007 TJA_ACC_Rq 3 "TJA_ACC_FORCE_DIS" 2 "TJA_ACC_BRK" 1 "TJA_ACC_INHIBIT_ACCEL" 0 "TJA_ACC_NO_REQ" ;
VAL_ 2007 TJA_Situation_enum 3 "reserve" 2 "Invalid" 1 "Uncertain" 0 "Valid" ;
VAL_ 2007 TJA_Drv_OvRd_enum 3 "reserve" 2 "Driver Override Longitudinally" 1 "Driver Override Laterally" 0 "No Driver Override" ;
VAL_ 1957 Type_Source_Boundary_Right 3 "Barrier" 2 "Road Edge" 1 "Lane Marker" 0 "None" ;
VAL_ 1957 Type_Source_Boundary_Left 3 "Barrier" 2 "Road Edge" 1 "Lane Marker" 0 "None" ;
VAL_ 281 SP_type 8 "Reserved" 7 "PO_and_BLM" 6 "PO_and_RLM" 5 "PO_and_LLM" 4 "PO_Only" 3 "BLM_Only" 2 "RLM_Only" 1 "LLM_Only" 0 "Invalid" ;
VAL_ 281 SP_conf 4 "High" 3 "MedHigh" 2 "Med" 1 "Low" 0 "Invalid" ;
VAL_ 281 SP_status 6 "RESERVED" 5 "MATURE_COASTED" 4 "MATURE_UPDATED" 3 "NEW_COASTED" 2 "NEW_UPDATED" 1 "NEW" 0 "INVALID" ;
VAL_ 281 BLM_Status 6 "RESERVED" 5 "MATURE_COASTED" 4 "MATURE_UPDATED" 3 "NEW_COASTED" 2 "NEW_UPDATED" 1 "NEW" 0 "INVALID" ;
VAL_ 273 LLM_type 22 "RESERVED" 21 "BLM" 20 "RLM" 19 "LLM" 18 "ETSEL" 17 "YAWRATE_MODEL" 16 "NON_PO_TRAIL" 9 "PO_TRAIL" 8 "FUSED_BARRIER" 7 "RADAR_GUARDRAIL" 6 "LM_ROAD_EDGE" 5 "LM_BARRIER" 0 "INVALID" ;
VAL_ 273 LLM_status 6 "RESERVED" 5 "MATURE_COASTED" 4 "MATURE_UPDATED" 3 "NEW_COASTED" 2 "NEW_UPDATED" 1 "NEW" 0 "INVALID" ;
VAL_ 279 RLM_type 22 "RESERVED" 21 "BLM" 20 "RLM" 19 "LLM" 18 "ETSEL" 17 "YAWRATE_MODEL" 16 "NON_PO_TRAIL" 9 "PO_TRAIL" 8 "FUSED_BARRIER" 7 "RADAR_GUARDRAIL" 6 "LM_ROAD_EDGE" 5 "LM_BARRIER" 0 "INVALID" ;
VAL_ 279 RLM_status 6 "RESERVED" 5 "MATURE_COASTED" 4 "MATURE_UPDATED" 3 "NEW_COASTED" 2 "NEW_UPDATED" 1 "NEW" 0 "INVALID" ;
VAL_ 276 PO_conf 3 "HIGH" 2 "MED" 1 "LOW" 0 "NONE" ;
VAL_ 276 PO_type 4 "RESERVED" 3 "VISION" 2 "ETSEL" 1 "YAWRATE" 0 "INVALID" ;
VAL_ 276 PO_status 6 "RESERVED" 5 "MATURE_COASTED" 4 "MATURE_UPDATED" 3 "NEW_COASTED" 2 "NEW_UPDATED" 1 "NEW" 0 "INVALID" ;
VAL_ 288 SP_PO_BLM_similarity 3 "HIGH" 2 "MED" 1 "LOW" 0 "NONE" ;
VAL_ 288 SP_RLM_PO_similarity 3 "HIGH" 2 "MED" 1 "LOW" 0 "NONE" ;
VAL_ 288 SP_LLM_PO_similarity 3 "HIGH" 2 "MED" 1 "LOW" 0 "NONE" ;
VAL_ 288 SP_LLM_RLM_similarity 3 "HIGH" 2 "MED" 1 "LOW" 0 "NONE" ;
